VERSION ""

NS_ :

BS_:

BU_: ORC MPAD EVCU2 EPS CVADAS BSM2 BSM ADCAM

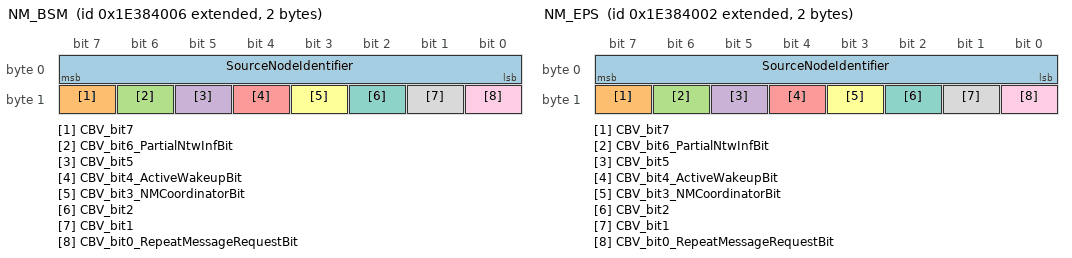
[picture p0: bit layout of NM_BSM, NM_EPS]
BO_ 2654486534 NM_BSM: 2 BSM
 SG_ SourceNodeIdentifier : 7|8@0+ (1,0) [0|255] "-"  CVADAS,ADCAM,MPAD,EVCU2,BSM2,ORC,EPS
 SG_ CBV_bit7 : 15|1@0+ (1,0) [0|1] "" CVADAS,ADCAM,MPAD,EVCU2,BSM2,ORC,EPS
 SG_ CBV_bit6_PartialNtwInfBit : 14|1@0+ (1,0) [0|1] "" CVADAS,ADCAM,MPAD,EVCU2,BSM2,ORC,EPS
 SG_ CBV_bit5 : 13|1@0+ (1,0) [0|1] "" CVADAS,ADCAM,MPAD,EVCU2,BSM2,ORC,EPS
 SG_ CBV_bit4_ActiveWakeupBit : 12|1@0+ (1,0) [0|1] "" CVADAS,ADCAM,MPAD,EVCU2,BSM2,ORC,EPS
 SG_ CBV_bit3_NMCoordinatorBit : 11|1@0+ (1,0) [0|1] "" CVADAS,ADCAM,MPAD,EVCU2,BSM2,ORC,EPS
 SG_ CBV_bit2 : 10|1@0+ (1,0) [0|1] "" CVADAS,ADCAM,MPAD,EVCU2,BSM2,ORC,EPS
 SG_ CBV_bit1 : 9|1@0+ (1,0) [0|1] "" CVADAS,ADCAM,MPAD,EVCU2,BSM2,ORC,EPS
 SG_ CBV_bit0_RepeatMessageRequestBit : 8|1@0+ (1,0) [0|1] "" CVADAS,ADCAM,MPAD,EVCU2,BSM2,ORC,EPS

BO_ 258 BRAKE_FD_2: 64 BSM
 SG_ YawRateFailSts_BSM : 87|1@0+ (1,0) [0|1] "-"  CVADAS,ADCAM,MPAD,EPS
 SG_ YawRate_BSM : 67|12@0+ (0.08,-163.84) [-163.84|163.68] "deg/s"  CVADAS,ADCAM,MPAD,EPS
 SG_ VehicleSpeedVSOSig : 4|13@0+ (0.0625,0) [0|511.875] "Km/h"  CVADAS,ADCAM,MPAD,EVCU2,BSM2,EPS
 SG_ Slope : 135|8@0+ (1,-100) [-100|154] "%"  CVADAS,MPAD
 SG_ PrefillActive : 86|1@0+ (1,0) [0|1] "-"  ADCAM,MPAD
 SG_ MessageCounter_BRAKE2 : 435|4@0+ (1,0) [0|15] "-"  CVADAS,ADCAM,MPAD,EVCU2,BSM2,EPS
 SG_ LongAccelerationFailSts_BSM : 69|1@0+ (1,0) [0|1] "-"  CVADAS,ADCAM,MPAD
 SG_ LongAcceleration_BSM : 35|12@0+ (0.02,-40.96) [-40.96|40.92] "m/s^2"  CVADAS,ADCAM,MPAD,EPS
 SG_ LatAccelerationFailSts_BSM : 68|1@0+ (1,0) [0|1] "-"  CVADAS,ADCAM,MPAD
 SG_ LatAcceleration_BSM : 19|12@0+ (0.02,-40.96) [-40.96|40.92] "m/s^2"  CVADAS,ADCAM,MPAD,EPS
 SG_ InternalError_BSM : 191|1@0+ (1,0) [0|1] "-"  ADCAM,MPAD
 SG_ ESP_Sys_Stat : 71|2@0+ (1,0) [0|3] "-"  Vector__XXX
 SG_ ESCActive : 84|1@0+ (1,0) [0|1] "-"  MPAD,EVCU2
 SG_ CRC_BRAKE2 : 447|8@0+ (1,0) [0|255] "-"  CVADAS,ADCAM,MPAD,EVCU2,BSM2,EPS
 SG_ BrakePedalPressure : 386|11@0+ (0.1,0) [0|200] "bar"  EVCU2
 SG_ BrakeInterventionSts : 103|1@0+ (1,0) [0|1] "-"  ADCAM,MPAD,BSM2
 SG_ BrakeBoostStat : 439|4@0+ (1,0) [0|14] "-"  Vector__XXX
 SG_ BrakeBoostPressure : 370|11@0+ (0.1,0) [0|200] "bar"  EVCU2
 SG_ ABSActive : 83|1@0+ (1,0) [0|1] "-"  MPAD,EVCU2
 SG_ WheelRPM_FR : 295|16@0+ (0.001953125,0) [0|127.9961] "Rev/s"  MPAD,EPS
 SG_ WheelRPM_FL : 279|16@0+ (0.001953125,0) [0|127.9961] "Rev/s"  MPAD,EPS
 SG_ Brk_Stat : 343|2@0+ (1,0) [0|2] "-"  CVADAS,ADCAM,MPAD,EVCU2
 SG_ ParkingGearShiftReq_BSM : 22|3@0+ (1,0) [0|6] "" CVADAS
 SG_ ParkingInterventionSts : 7|2@0+ (1,0) [0|3] "" CVADAS

BO_ 2654486530 NM_EPS: 2 EPS
 SG_ SourceNodeIdentifier : 7|8@0+ (1,0) [0|255] "-"  CVADAS,ADCAM,MPAD,EVCU2,BSM2,BSM,ORC
 SG_ CBV_bit7 : 15|1@0+ (1,0) [0|1] "" CVADAS,ADCAM,MPAD,EVCU2,BSM2,BSM,ORC
 SG_ CBV_bit6_PartialNtwInfBit : 14|1@0+ (1,0) [0|1] "" CVADAS,ADCAM,MPAD,EVCU2,BSM2,BSM,ORC
 SG_ CBV_bit5 : 13|1@0+ (1,0) [0|1] "" CVADAS,ADCAM,MPAD,EVCU2,BSM2,BSM,ORC
 SG_ CBV_bit4_ActiveWakeupBit : 12|1@0+ (1,0) [0|1] "" CVADAS,ADCAM,MPAD,EVCU2,BSM2,BSM,ORC
 SG_ CBV_bit3_NMCoordinatorBit : 11|1@0+ (1,0) [0|1] "" CVADAS,ADCAM,MPAD,EVCU2,BSM2,BSM,ORC
 SG_ CBV_bit2 : 10|1@0+ (1,0) [0|1] "" CVADAS,ADCAM,MPAD,EVCU2,BSM2,BSM,ORC
 SG_ CBV_bit1 : 9|1@0+ (1,0) [0|1] "" CVADAS,ADCAM,MPAD,EVCU2,BSM2,BSM,ORC
 SG_ CBV_bit0_RepeatMessageRequestBit : 8|1@0+ (1,0) [0|1] "" CVADAS,ADCAM,MPAD,EVCU2,BSM2,BSM,ORC

BO_ 524 BRAKE2_FD_2: 32 BSM2
 SG_ VehicleStandStillSts_B2 : 47|2@0+ (1,0) [0|2] "" MPAD,BSM
 SG_ BSM2_OpStat : 50|3@0+ (1,0) [0|5] "" MPAD,BSM
 SG_ Brake_OpStat_Sec : 53|3@0+ (1,0) [0|5] "" MPAD
 SG_ MessageCounter_BRAKE2_2 : 179|4@0+ (1,0) [0|15] "-"  MPAD,BSM,ORC
 SG_ CRC_BRAKE2_2 : 191|8@0+ (1,0) [0|255] "-"  MPAD,BSM,ORC
 SG_ BrkTrq_B2 : 6|15@0+ (3,0) [0|98301] "Nm"  MPAD
 SG_ BSM2_HEALTH_CHECK : 63|8@0+ (1,0) [0|255] "" BSM
 SG_ AEB_Type_Brk_B2 : 43|4@0+ (1,0) [0|15] "" MPAD

BO_ 257 BRAKE2_FD_1: 64 BSM2
 SG_ VehicleSpeedVSOSig_B2 : 36|13@0+ (0.0625,0) [0|511.875] "Km/h"  MPAD,EPS
 SG_ RHFWheelSpeed_B2 : 68|13@0+ (0.0625,0) [0|511.875] "Km/h"  MPAD
 SG_ RHF_FastPulseCounter_B2 : 95|8@0+ (1,0) [0|255] "pulse"  MPAD
 SG_ LHFWheelSpeed_B2 : 52|13@0+ (0.0625,0) [0|511.875] "Km/h"  MPAD
 SG_ LHF_FastPulseCounter_B2 : 87|8@0+ (1,0) [0|255] "pulse"  MPAD
 SG_ RHF_WheelSensorFailSts_B2 : 69|1@0+ (1,0) [0|1] "" MPAD
 SG_ RHF_Spin_B2 : 55|2@0+ (1,0) [0|3] "" MPAD
 SG_ MessageCounter_BRAKE2_1 : 435|4@0+ (1,0) [0|15] "-"  MPAD,ORC,EPS
 SG_ LHF_WheelSensorFailSts_B2 : 53|1@0+ (1,0) [0|1] "" MPAD
 SG_ LHF_Spin_B2 : 39|2@0+ (1,0) [0|3] "" MPAD
 SG_ Inlet_Pressure_Pos : 98|2@0+ (1,0) [0|2] "" MPAD
 SG_ CRC_BRAKE2_1 : 447|8@0+ (1,0) [0|255] "-"  MPAD,ORC,EPS
 SG_ Brk_Stat_B2 : 71|2@0+ (1,0) [0|2] "" MPAD
 SG_ ABSActive_B2 : 37|1@0+ (1,0) [0|1] "" MPAD
 SG_ Ft_RrTrqCoupling_ModeRq_B2 : 158|2@0+ (1,0) [0|3] "-"  Vector__XXX
 SG_ Ft_RrAxleCoupling_TrqRq_B2 : 143|8@0+ (12,0) [0|3060] "Nm"  Vector__XXX

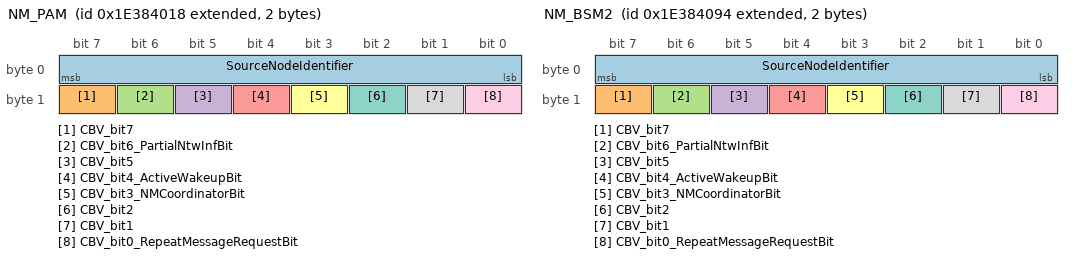
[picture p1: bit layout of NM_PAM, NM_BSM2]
BO_ 2654486552 NM_PAM: 2 CVADAS
 SG_ SourceNodeIdentifier : 7|8@0+ (1,0) [0|255] "-"  ADCAM,MPAD,EVCU2,BSM2,BSM,ORC,EPS
 SG_ CBV_bit7 : 15|1@0+ (1,0) [0|1] "" ADCAM,MPAD,EVCU2,BSM2,BSM,ORC,EPS
 SG_ CBV_bit6_PartialNtwInfBit : 14|1@0+ (1,0) [0|1] "" ADCAM,MPAD,EVCU2,BSM2,BSM,ORC,EPS
 SG_ CBV_bit5 : 13|1@0+ (1,0) [0|1] "" ADCAM,MPAD,EVCU2,BSM2,BSM,ORC,EPS
 SG_ CBV_bit4_ActiveWakeupBit : 12|1@0+ (1,0) [0|1] "" ADCAM,MPAD,EVCU2,BSM2,BSM,ORC,EPS
 SG_ CBV_bit3_NMCoordinatorBit : 11|1@0+ (1,0) [0|1] "" ADCAM,MPAD,EVCU2,BSM2,BSM,ORC,EPS
 SG_ CBV_bit2 : 10|1@0+ (1,0) [0|1] "" ADCAM,MPAD,EVCU2,BSM2,BSM,ORC,EPS
 SG_ CBV_bit1 : 9|1@0+ (1,0) [0|1] "" ADCAM,MPAD,EVCU2,BSM2,BSM,ORC,EPS
 SG_ CBV_bit0_RepeatMessageRequestBit : 8|1@0+ (1,0) [0|1] "" ADCAM,MPAD,EVCU2,BSM2,BSM,ORC,EPS

BO_ 2654486676 NM_BSM2: 2 BSM2
 SG_ SourceNodeIdentifier : 7|8@0+ (1,0) [0|255] "-"  CVADAS,ADCAM,MPAD,EVCU2,BSM,ORC,EPS
 SG_ CBV_bit7 : 15|1@0+ (1,0) [0|1] "" CVADAS,ADCAM,MPAD,EVCU2,BSM,ORC,EPS
 SG_ CBV_bit6_PartialNtwInfBit : 14|1@0+ (1,0) [0|1] "" CVADAS,ADCAM,MPAD,EVCU2,BSM,ORC,EPS
 SG_ CBV_bit5 : 13|1@0+ (1,0) [0|1] "" CVADAS,ADCAM,MPAD,EVCU2,BSM,ORC,EPS
 SG_ CBV_bit4_ActiveWakeupBit : 12|1@0+ (1,0) [0|1] "" CVADAS,ADCAM,MPAD,EVCU2,BSM,ORC,EPS
 SG_ CBV_bit3_NMCoordinatorBit : 11|1@0+ (1,0) [0|1] "" CVADAS,ADCAM,MPAD,EVCU2,BSM,ORC,EPS
 SG_ CBV_bit2 : 10|1@0+ (1,0) [0|1] "" CVADAS,ADCAM,MPAD,EVCU2,BSM,ORC,EPS
 SG_ CBV_bit1 : 9|1@0+ (1,0) [0|1] "" CVADAS,ADCAM,MPAD,EVCU2,BSM,ORC,EPS
 SG_ CBV_bit0_RepeatMessageRequestBit : 8|1@0+ (1,0) [0|1] "" CVADAS,ADCAM,MPAD,EVCU2,BSM,ORC,EPS

BO_ 727 CVPAM_FD_Data2: 64 CVADAS
 SG_ MessageCounter_CVPAM_FD_Data2 : 435|4@0+ (1,0) [0|15] "-"  MPAD
 SG_ CRC_CVPAM_FD_Data2 : 447|8@0+ (1,0) [0|255] "-"  MPAD

BO_ 726 CVPAM_FD_Data: 64 CVADAS
 SG_ MessageCounter_CVPAM_FD_Data : 435|4@0+ (1,0) [0|15] "-"  MPAD
 SG_ CRC_CVPAM_FD_Data : 447|8@0+ (1,0) [0|255] "-"  MPAD

BO_ 1156 BRAKE2_FD_3: 32 BSM2
 SG_ RollsModeAct_B2 : 6|1@0+ (1,0) [0|1] "" MPAD
 SG_ MessageCounter_BRAKE2_3 : 179|4@0+ (1,0) [0|15] "-"  ORC
 SG_ CRC_BRAKE2_3 : 191|8@0+ (1,0) [0|255] "-"  ORC
 SG_ ABSFailSts_B2 : 7|1@0+ (1,0) [0|1] "" MPAD

BO_ 280 ADAS_FD_INFO: 32 ADCAM
 SG_ Object_Dist : 127|8@0+ (1,0) [0|255] "m"  EVCU2,BSM,ORC
 SG_ MessageCounter_ADAS_FD_INFO : 179|4@0+ (1,0) [0|15] "-"  CVADAS,EVCU2,BSM2,BSM,ORC,EPS
 SG_ CRC_ADAS_FD_INFO : 191|8@0+ (1,0) [0|255] "-"  CVADAS,EVCU2,BSM2,BSM,ORC,EPS
 SG_ ACC_DsrSpeedKPH : 119|8@0+ (1,0) [0|255] "km/h"  EVCU2
 SG_ Intervention : 163|12@0+ (0.01,-16) [-16|24.95] "m/s2"  BSM2,BSM,ORC
 SG_ HIS_Req : 89|1@0+ (1,0) [0|1] "-"  BSM2,BSM,ORC
 SG_ GrMax_Rq_ACC : 150|4@0+ (1,0) [0|15] "-"  BSM
 SG_ CIPV_Fused : 101|1@0+ (1,0) [0|1] "-"  ORC
 SG_ Brake_Jerk_Req : 100|1@0+ (1,0) [0|1] "-"  BSM
 SG_ ACC_Engine_Torque_Enabled : 111|1@0+ (1,0) [0|1] "-"  BSM
 SG_ ACC_Drive_Cmd : 151|1@0+ (1,0) [0|1] "-"  BSM
 SG_ Prefill_Req : 91|1@0+ (1,0) [0|1] "-"  BSM
 SG_ PEB_SystemSts : 90|1@0+ (1,0) [0|1] "-"  ORC
 SG_ MRM_STATUS : 23|3@0+ (1,0) [0|6] "" CVADAS,EVCU2,BSM,ORC
 SG_ LANE_CHANGE_SIDE : 95|2@0+ (1,0) [0|2] "" ORC
 SG_ HAS_Status : 106|2@0+ (1,0) [0|3] "" CVADAS,BSM2,BSM
 SG_ HAS_OpStat_Prim : 4|3@0+ (1,0) [0|5] "" ORC
 SG_ HAS_LAT_CTRL_RequestSts : 110|2@0+ (1,0) [0|3] "-"  EPS
 SG_ ESCALATION_TYPE : 12|3@0+ (1,0) [0|4] "" ORC
 SG_ DDD_SystemSts : 103|1@0+ (1,0) [0|1] "-"  ORC
 SG_ DDD_Setting_Avail : 102|1@0+ (1,0) [0|1] "-"  Vector__XXX
 SG_ CADM_OpStat : 7|3@0+ (1,0) [0|5] "" CVADAS
 SG_ AEB_Type : 167|4@0+ (1,0) [0|14] "-"  BSM2,BSM,ORC
 SG_ AEB_Systemsts : 99|2@0+ (1,0) [0|2] "-"  ORC
 SG_ AEB_Sensitivity_Setting : 1|2@0+ (1,0) [0|2] "" Vector__XXX
 SG_ ACC_Systemsts : 183|4@0+ (1,0) [0|14] "-"  CVADAS,ADCAM,EVCU2,BSM2,BSM,ORC
 SG_ SteeringVibration_Type : 67|4@0+ (1,0) [0|14] "-"  EPS
 SG_ SteeringVibration_Rq : 135|1@0+ (1,0) [0|1] "-"  EPS
 SG_ LKA_LAT_CTRL_RequestSts : 108|2@0+ (1,0) [0|3] "-"  EPS
 SG_ LANE_CHANGE_STATUS : 71|4@0+ (1,0) [0|14] "" ADCAM,ORC
 SG_ LC_Jerk : 104|1@0+ (1,0) [0|1] "-"  BSM
 SG_ CADM2_EPSSEC_FAIL : 8|1@0+ (1,0) [0|1] "" EPS
 SG_ TorqueOverlaySteeringReq : 130|11@0+ (0.0048828125,-5) [-5|4.995117188] "-"  ORC,EPS

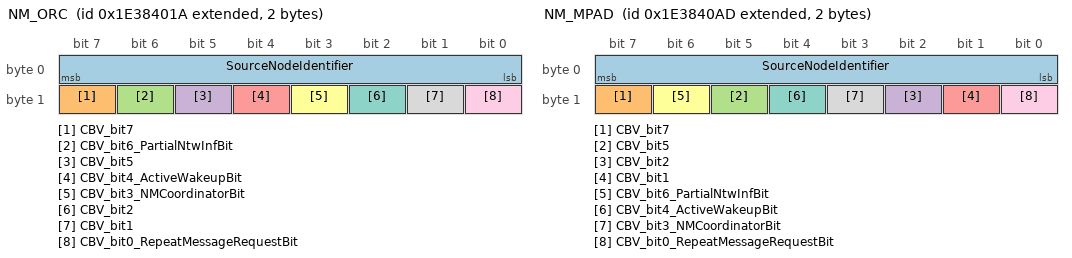
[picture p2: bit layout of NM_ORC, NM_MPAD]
BO_ 2654486554 NM_ORC: 2 ORC
 SG_ SourceNodeIdentifier : 7|8@0+ (1,0) [0|255] "-"  CVADAS,ADCAM,MPAD,EVCU2,BSM2,BSM,EPS
 SG_ CBV_bit7 : 15|1@0+ (1,0) [0|1] "" CVADAS,ADCAM,MPAD,EVCU2,BSM2,BSM,EPS
 SG_ CBV_bit6_PartialNtwInfBit : 14|1@0+ (1,0) [0|1] "" CVADAS,ADCAM,MPAD,EVCU2,BSM2,BSM,EPS
 SG_ CBV_bit5 : 13|1@0+ (1,0) [0|1] "" CVADAS,ADCAM,MPAD,EVCU2,BSM2,BSM,EPS
 SG_ CBV_bit4_ActiveWakeupBit : 12|1@0+ (1,0) [0|1] "" CVADAS,ADCAM,MPAD,EVCU2,BSM2,BSM,EPS
 SG_ CBV_bit3_NMCoordinatorBit : 11|1@0+ (1,0) [0|1] "" CVADAS,ADCAM,MPAD,EVCU2,BSM2,BSM,EPS
 SG_ CBV_bit2 : 10|1@0+ (1,0) [0|1] "" CVADAS,ADCAM,MPAD,EVCU2,BSM2,BSM,EPS
 SG_ CBV_bit1 : 9|1@0+ (1,0) [0|1] "" CVADAS,ADCAM,MPAD,EVCU2,BSM2,BSM,EPS
 SG_ CBV_bit0_RepeatMessageRequestBit : 8|1@0+ (1,0) [0|1] "" CVADAS,ADCAM,MPAD,EVCU2,BSM2,BSM,EPS

BO_ 205 BRAKE_FD_6: 64 BSM
 SG_ CRC_BRAKE_FD_6 : 447|8@0+ (1,0) [0|255] "-"  EVCU2
 SG_ MessageCounter_BRAKE_FD_6 : 435|4@0+ (1,0) [0|15] "-"  EVCU2
 SG_ RearAxle_Min_Rq_BSM : 52|1@0+ (1,0) [0|1] "" EVCU2
 SG_ RearAxle_Max_Rq_BSM : 53|1@0+ (1,0) [0|1] "" EVCU2
 SG_ FrontAxle_Min_Rq_BSM : 54|1@0+ (1,0) [0|1] "" EVCU2
 SG_ FrontAxle_Max_Rq_BSM : 55|1@0+ (1,0) [0|1] "" EVCU2
 SG_ TotalAxle_Min_Rq_BSM : 50|1@0+ (1,0) [0|1] "" EVCU2
 SG_ TotalAxle_Max_Rq_BSM : 51|1@0+ (1,0) [0|1] "" EVCU2
 SG_ DrvrIntd_TotalBrk_AxleTorq : 142|15@0+ (2,0) [0|65532] "Nm"  EVCU2
 SG_ DriverReq_AxleTrq_Enabled_BSM : 175|4@0+ (1,0) [0|15] "" CVADAS,EVCU2
 SG_ Cmnd_TotBrkFrict_AxleTorq : 126|15@0+ (2,0) [0|65532] "Nm"  EVCU2
 SG_ TotalAxle_Rq_BSM : 95|16@0+ (2,-65534) [-65534|65536] "Nm"  EVCU2
 SG_ DriverRequested_AxleTrq_BSM : 159|16@0+ (2,-65534) [-65534|65536] "Nm"  EVCU2
 SG_ RearAxle_Rq_BSM : 79|16@0+ (2,-65534) [-65534|65536] "Nm"  EVCU2
 SG_ FrontAxle_Rq_BSM : 63|16@0+ (2,-65534) [-65534|65536] "Nm"  EVCU2

BO_ 204 AXLE_TORQUE_FD_1: 48 EVCU2
 SG_ MessageCounter_AXLE_TORQUE_FD_1 : 307|4@0+ (1,0) [0|15] "-"  ADCAM,MPAD
 SG_ CRC_AXLE_TORQUE_FD_1 : 319|8@0+ (1,0) [0|255] "-"  ADCAM,MPAD
 SG_ Rear_Axle_Regen_Capacity : 197|14@0+ (2,0) [0|32764] "Nm"  BSM
 SG_ Rear_Axle_Est_Regen_Torq : 181|14@0+ (2,0) [0|32764] "Nm"  BSM
 SG_ Front_Axle_Regen_Capacity : 165|14@0+ (2,0) [0|32764] "Nm"  BSM
 SG_ Front_Axle_Est_Regen_Torq : 149|14@0+ (2,0) [0|32764] "Nm"  BSM
 SG_ Total_AxleTorque_Min : 23|16@0+ (2,-65534) [-65534|65536] "Nm"  ADCAM,MPAD,BSM
 SG_ Total_AxleTorque_Max : 7|16@0+ (2,-65534) [-65534|65536] "Nm"  ADCAM,MPAD
 SG_ Axle_TorqueStatic_D_TTC : 39|16@0+ (2,-65534) [-65534|65536] "Nm"  ADCAM,MPAD,BSM
 SG_ Axle_Torque_DrvReqMod : 55|16@0+ (2,-65534) [-65534|65536] "Nm"  ADCAM,MPAD,BSM
 SG_ Rear_AxleTorque_Min : 119|16@0+ (2,-65534) [-65534|65536] "Nm"  BSM
 SG_ Rear_AxleTorque_Max : 103|16@0+ (2,-65534) [-65534|65536] "Nm"  BSM
 SG_ Front_AxleTorque_Min : 87|16@0+ (2,-65534) [-65534|65536] "Nm"  BSM
 SG_ Front_AxleTorque_Max : 71|16@0+ (2,-65534) [-65534|65536] "Nm"  BSM

BO_ 292 BATTERY_HV_STATUS1: 64 EVCU2
 SG_ BPCM_HV_Trac_Main_Contac_Sts : 181|3@0+ (1,0) [0|7] "" Vector__XXX
 SG_ BPCM_HV_Trac_Bus_Sts : 36|3@0+ (1,0) [0|7] "" ORC
 SG_ BPCM_HV_SOC : 33|10@0+ (0.1,0) [0|102.3] "%"  BSM
 SG_ BPCM_HV_InternalVoltage : 133|14@0+ (0.1,90.9) [90.9|1729.2] "V"  ORC
 SG_ MessageCounter_BATT_HV_STATUS1 : 435|4@0+ (1,0) [0|15] "" ORC,BSM
 SG_ CRC_BATT_HV_STATUS1 : 447|8@0+ (1,0) [0|255] "" ORC,BSM

BO_ 2654486701 NM_MPAD: 2 MPAD
 SG_ SourceNodeIdentifier : 7|8@0+ (1,0) [0|255] "-"  CVADAS,ADCAM,EVCU2,BSM2,BSM,ORC,EPS
 SG_ CBV_bit7 : 15|1@0+ (1,0) [0|1] "" CVADAS,ADCAM,EVCU2,BSM2,BSM,ORC,EPS
 SG_ CBV_bit5 : 13|1@0+ (1,0) [0|1] "" CVADAS,ADCAM,EVCU2,BSM2,BSM,ORC,EPS
 SG_ CBV_bit2 : 10|1@0+ (1,0) [0|1] "" CVADAS,ADCAM,EVCU2,BSM2,BSM,ORC,EPS
 SG_ CBV_bit1 : 9|1@0+ (1,0) [0|1] "" CVADAS,ADCAM,EVCU2,BSM2,BSM,ORC,EPS
 SG_ CBV_bit6_PartialNtwInfBit : 14|1@0+ (1,0) [0|1] "-"  CVADAS,ADCAM,EVCU2,BSM2,BSM,ORC,EPS
 SG_ CBV_bit4_ActiveWakeupBit : 12|1@0+ (1,0) [0|1] "-"  CVADAS,ADCAM,EVCU2,BSM2,BSM,ORC,EPS
 SG_ CBV_bit3_NMCoordinatorBit : 11|1@0+ (1,0) [0|1] "-"  CVADAS,ADCAM,EVCU2,BSM2,BSM,ORC,EPS
 SG_ CBV_bit0_RepeatMessageRequestBit : 8|1@0+ (1,0) [0|1] "-"  CVADAS,ADCAM,EVCU2,BSM2,BSM,ORC,EPS

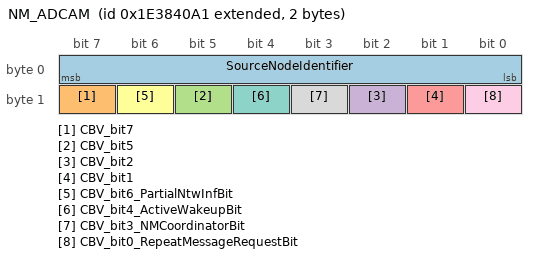
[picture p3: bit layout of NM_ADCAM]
BO_ 2654486689 NM_ADCAM: 2 ADCAM
 SG_ SourceNodeIdentifier : 7|8@0+ (1,0) [0|255] "-"  CVADAS,MPAD,EVCU2,BSM2,BSM,ORC,EPS
 SG_ CBV_bit7 : 15|1@0+ (1,0) [0|1] "" CVADAS,MPAD,EVCU2,BSM2,BSM,ORC,EPS
 SG_ CBV_bit5 : 13|1@0+ (1,0) [0|1] "" CVADAS,MPAD,EVCU2,BSM2,BSM,ORC,EPS
 SG_ CBV_bit2 : 10|1@0+ (1,0) [0|1] "" CVADAS,MPAD,EVCU2,BSM2,BSM,ORC,EPS
 SG_ CBV_bit1 : 9|1@0+ (1,0) [0|1] "" CVADAS,MPAD,EVCU2,BSM2,BSM,ORC,EPS
 SG_ CBV_bit6_PartialNtwInfBit : 14|1@0+ (1,0) [0|1] "-"  CVADAS,MPAD,EVCU2,BSM2,BSM,ORC,EPS
 SG_ CBV_bit4_ActiveWakeupBit : 12|1@0+ (1,0) [0|1] "-"  CVADAS,MPAD,EVCU2,BSM2,BSM,ORC,EPS
 SG_ CBV_bit3_NMCoordinatorBit : 11|1@0+ (1,0) [0|1] "-"  CVADAS,MPAD,EVCU2,BSM2,BSM,ORC,EPS
 SG_ CBV_bit0_RepeatMessageRequestBit : 8|1@0+ (1,0) [0|1] "-"  CVADAS,MPAD,EVCU2,BSM2,BSM,ORC,EPS

BO_ 299 ADAS_FD_INFO3: 32 ADCAM
 SG_ ACC_Axle_Torque : 7|16@0+ (2,-65534) [-65534|65536] "Nm"  BSM
 SG_ ACC_Axle_Torque_Enabled : 180|1@0+ (1,0) [0|1] "" BSM
 SG_ MessageCounter_ADAS_FD_INFO3 : 179|4@0+ (1,0) [0|15] "-"  MPAD,BSM
 SG_ CRC_ADAS_FD_INFO3 : 191|8@0+ (1,0) [0|255] "-"  MPAD,BSM
 SG_ ACC_TORSts : 22|1@0+ (1,0) [0|1] "" ADCAM

BO_TX_BU_ 280 : ADCAM,MPAD;
BO_TX_BU_ 299 : ADCAM,MPAD;
CM_ SG_ 2654486534 CBV_bit6_PartialNtwInfBit "Partial Network Information Bit (PNI)";
CM_ SG_ 2654486534 CBV_bit4_ActiveWakeupBit "Active Wakeup Bit";
CM_ SG_ 2654486534 CBV_bit3_NMCoordinatorBit "NM Coordinator Sleep Bit";
CM_ SG_ 2654486534 CBV_bit0_RepeatMessageRequestBit "Repeat Message Request Bit";
CM_ SG_ 2654486534 SourceNodeIdentifier "Source Node Identifier";
CM_ SG_ 258 YawRateFailSts_BSM "This signal indicates the Status of Yaw Rate Signal";
CM_ SG_ 258 YawRate_BSM "This signal indicates the Yaw Rate Value";
CM_ SG_ 258 WheelRPM_FL "Wheel RPM front left";
CM_ SG_ 258 Slope "Slope value detected by BSM";
CM_ SG_ 258 PrefillActive "This signal indicates the prefill function status.";
CM_ SG_ 258 ParkingInterventionSts "Current status of BSM during Autonomous Parking Maneuver";
CM_ SG_ 258 ParkingGearShiftReq_BSM "CVPAM Request to autonomously shift gears";
CM_ SG_ 258 VehicleSpeedVSOSig "It is the average vehicle speed calculated.";
CM_ SG_ 258 MessageCounter_BRAKE2 "This signal is a counter used for safety checks strategies. This counter is incremented of 1 (one) unit at each frame transmission.";
CM_ SG_ 258 LongAccelerationFailSts_BSM "This signal indicates the status of Longitudinal acceleration signal";
CM_ SG_ 258 LongAcceleration_BSM "This signal indicates the Longitudinal Acceleration Value";
CM_ SG_ 258 LatAccelerationFailSts_BSM "This signal indicates the status of Lateral Acceleration Signal";
CM_ SG_ 258 LatAcceleration_BSM "This signal indicates the Lateral Acceleration Value";
CM_ SG_ 258 InternalError_BSM "This signal indicates if an internal error has been processed";
CM_ SG_ 258 ESP_Sys_Stat "0";
CM_ SG_ 258 ESCActive "This signal is set to Active when the brake intervention by ESC is active.";
CM_ SG_ 258 Brk_Stat "Brake state";
CM_ SG_ 258 BrakePedalPressure "Pressure Information from Brake Pedal Simulator Pressure Sensor";
CM_ SG_ 258 BrakeInterventionSts "This signal is ?active? when the brake intervention is due to BSM events and ?not active? when the brake intervention is due to the driver";
CM_ SG_ 258 BrakeBoostStat "eBoost System Status INIT, eBOOST, PUSH-THROUGH, SNA";
CM_ SG_ 258 BrakeBoostPressure "Pressure Information from Brake Booster Pressure Sensor";
CM_ SG_ 258 ABSActive "This signal is set to Active when the ABS functionality is active.";
CM_ SG_ 258 CRC_BRAKE2 "CRC according to SAE J1850 standard at each frame transmission.";
CM_ SG_ 258 WheelRPM_FR "Wheel RPM front right";
CM_ SG_ 2654486530 SourceNodeIdentifier "Source Node Identifier";
CM_ SG_ 2654486530 CBV_bit6_PartialNtwInfBit "Partial Network Information Bit (PNI)";
CM_ SG_ 2654486530 CBV_bit4_ActiveWakeupBit "Active Wakeup Bit";
CM_ SG_ 2654486530 CBV_bit3_NMCoordinatorBit "NM Coordinator Sleep Bit";
CM_ SG_ 2654486530 CBV_bit0_RepeatMessageRequestBit "Repeat Message Request Bit";
CM_ SG_ 524 VehicleStandStillSts_B2 "VehicleStandStillSts_B2";
CM_ SG_ 524 MessageCounter_BRAKE2_2 "This signal is a counter used for safety checks strategies. This counter is incremented of 1 (one) unit at each frame transmission.";
CM_ SG_ 524 CRC_BRAKE2_2 "CRC according to SAE J1850 standard at each frame transmission.";
CM_ SG_ 524 BSM2_OpStat "Capability of the secondary brake control module to provide deceleration and/or stability control";
CM_ SG_ 524 BSM2_HEALTH_CHECK "BSM2_HEALTH_CHECK";
CM_ SG_ 524 BrkTrq_B2 "BrkTrq_B2";
CM_ SG_ 524 Brake_OpStat_Sec "Capability of the Braking system to perform deceleration and/or stability control as reported by the secondary actuator.";
CM_ SG_ 524 AEB_Type_Brk_B2 "AEB_Type_Brk_B2";
CM_ SG_ 257 VehicleSpeedVSOSig_B2 "VehicleSpeedVSOSig_B2";
CM_ SG_ 257 RHFWheelSpeed_B2 "RHFWheelSpeed_B2";
CM_ SG_ 257 RHF_WheelSensorFailSts_B2 "RHF_WheelSensorFailSts_B2";
CM_ SG_ 257 RHF_Spin_B2 "RHF_Spin_B2";
CM_ SG_ 257 RHF_FastPulseCounter_B2 "RHF_FastPulseCounter_B2";
CM_ SG_ 257 MessageCounter_BRAKE2_1 "This signal is a counter used for safety checks strategies. This counter is incremented of 1 (one) unit at each frame transmission.";
CM_ SG_ 257 LHFWheelSpeed_B2 "LHFWheelSpeed_B2";
CM_ SG_ 257 LHF_WheelSensorFailSts_B2 "LHF_WheelSensorFailSts_B2";
CM_ SG_ 257 LHF_Spin_B2 "LHF_Spin_B2";
CM_ SG_ 257 LHF_FastPulseCounter_B2 "LHF_FastPulseCounter_B2";
CM_ SG_ 257 Inlet_Pressure_Pos "Inlet Pressure Pos Indicates if the secondary brake control module detects upstream brake pressure";
CM_ SG_ 257 Ft_RrTrqCoupling_ModeRq_B2 "ESP Requested Center Differential State";
CM_ SG_ 257 Ft_RrAxleCoupling_TrqRq_B2 "Desired Torque for Center Diff";
CM_ SG_ 257 CRC_BRAKE2_1 "CRC according to SAE J1850 standard at each frame transmission.";
CM_ SG_ 257 Brk_Stat_B2 "Signifies a general braking event (both autonomous and driver requested) with the secondary brake control module";
CM_ SG_ 257 ABSActive_B2 "ABSActive_B2";
CM_ SG_ 2654486552 SourceNodeIdentifier "Source Node Identifier";
CM_ SG_ 2654486552 CBV_bit6_PartialNtwInfBit "Partial Network Information Bit (PNI)";
CM_ SG_ 2654486552 CBV_bit4_ActiveWakeupBit "Active Wakeup Bit";
CM_ SG_ 2654486552 CBV_bit3_NMCoordinatorBit "NM Coordinator Sleep Bit";
CM_ SG_ 2654486552 CBV_bit0_RepeatMessageRequestBit "Repeat Message Request Bit";
CM_ SG_ 2654486676 CBV_bit0_RepeatMessageRequestBit "Repeat Message Request Bit";
CM_ SG_ 2654486676 CBV_bit3_NMCoordinatorBit "NM Coordinator Sleep Bit";
CM_ SG_ 2654486676 CBV_bit4_ActiveWakeupBit "Active Wakeup Bit";
CM_ SG_ 2654486676 CBV_bit6_PartialNtwInfBit "Partial Network Information Bit (PNI)";
CM_ SG_ 2654486676 SourceNodeIdentifier "Source Node Identifier";
CM_ SG_ 727 MessageCounter_CVPAM_FD_Data2 "This signal is a counter used for safety checks strategies. This counter is incremented of 1 (one) unit at each frame transmission.";
CM_ SG_ 727 CRC_CVPAM_FD_Data2 "CRC according to SAE J1850 standard at each frame transmission.";
CM_ SG_ 726 MessageCounter_CVPAM_FD_Data "This signal is a counter used for safety checks strategies. This counter is incremented of 1 (one) unit at each frame transmission.";
CM_ SG_ 726 CRC_CVPAM_FD_Data "CRC according to SAE J1850 standard at each frame transmission.";
CM_ SG_ 1156 RollsModeAct_B2 "RollsModeAct_B2";
CM_ SG_ 1156 MessageCounter_BRAKE2_3 "This signal is a counter used for safety checks strategies. This counter is incremented of 1 (one) unit at each frame transmission.";
CM_ SG_ 1156 CRC_BRAKE2_3 "CRC according to SAE J1850 standard at each frame transmission.";
CM_ SG_ 1156 ABSFailSts_B2 "ABSFailSts_B2";
CM_ SG_ 280 TorqueOverlaySteeringReq "TorqueOverlaySteeringReq";
CM_ SG_ 280 SteeringVibration_Type "Type of Steering Wheel Vibration Request";
CM_ SG_ 280 SteeringVibration_Rq "Request to activate Steering Wheel Vibration";
CM_ SG_ 280 Prefill_Req "Prefill command of Brake System by DASM";
CM_ SG_ 280 PEB_SystemSts "PEB System Status";
CM_ SG_ 280 Object_Dist "It indicates the distance to the recognized object";
CM_ SG_ 280 MRM_STATUS "Status of the minimum risk maneuver to handle system faults or driver abuse as understood by primary controller";
CM_ SG_ 280 LKA_LAT_CTRL_RequestSts "LKA_LAT_CTRL_RequestSts";
CM_ SG_ 280 LC_Jerk "Lane Centering request for brake jerk";
CM_ SG_ 280 LANE_CHANGE_STATUS "Status of assisted lane change maneuver";
CM_ SG_ 280 LANE_CHANGE_SIDE "Direction of the currently in-progress lane change from a vehicle perspective";
CM_ SG_ 280 Intervention "Request to set target acceleration/deceleration for any feature";
CM_ SG_ 280 HIS_Req "Used to command Stop during Stop and Go ACC and FSFCW+";
CM_ SG_ 280 HAS_Status "Highway Assist System Status as reported by the main controller";
CM_ SG_ 280 HAS_OpStat_Prim "Capability of the primary controller to perform sensing, computing, and actuation";
CM_ SG_ 280 HAS_LAT_CTRL_RequestSts "HAS_LAT_CTRL_RequestSts";
CM_ SG_ 280 GrMax_Rq_ACC "Used to request Max Gear from TCM";
CM_ SG_ 280 ESCALATION_TYPE "Type of HMI escalation to be provided to driver from primary controller";
CM_ SG_ 280 DDD_SystemSts "DDD System Status";
CM_ SG_ 280 DDD_Setting_Avail "DDD_Setting Av Status";
CM_ SG_ 280 MessageCounter_ADAS_FD_INFO "This signal is a counter used for safety checks strategies. This counter is incremented of 1 (one) unit at each frame transmission.";
CM_ SG_ 280 CRC_ADAS_FD_INFO "CRC according to SAE J1850 standard at each frame transmission.";
CM_ SG_ 280 CIPV_Fused "Closest in-path vehicle is fused True = 1";
CM_ SG_ 280 CADM2_EPSSEC_FAIL "CADM2 detection of failure to communicate to EPS";
CM_ SG_ 280 CADM_OpStat "Capability of primary controller to sense and compute a valid trajectory path based on external data dependencies and internal failures";
CM_ SG_ 280 Brake_Jerk_Req "Request from DASM to perform Jerk Warning";
CM_ SG_ 280 AEB_Type "AEB Type";
CM_ SG_ 280 AEB_Systemsts "AEB System Status";
CM_ SG_ 280 AEB_Sensitivity_Setting "AEB sensitivity status";
CM_ SG_ 280 ACC_Engine_Torque_Enabled "An enable bit that Torque commands should be followed";
CM_ SG_ 280 ACC_DsrSpeedKPH "Desired speed in kilometers per hour";
CM_ SG_ 280 ACC_Drive_Cmd "ACC Drive Command";
CM_ SG_ 280 ACC_Systemsts "ACC System Status";
CM_ SG_ 2654486554 SourceNodeIdentifier "Source Node Identifier";
CM_ SG_ 2654486554 CBV_bit6_PartialNtwInfBit "Partial Network Information Bit (PNI)";
CM_ SG_ 2654486554 CBV_bit4_ActiveWakeupBit "Active Wakeup Bit";
CM_ SG_ 2654486554 CBV_bit3_NMCoordinatorBit "NM Coordinator Sleep Bit";
CM_ SG_ 2654486554 CBV_bit0_RepeatMessageRequestBit "Repeat Message Request Bit";
CM_ SG_ 205 TotalAxle_Rq_BSM "Combined axle traction torque request";
CM_ SG_ 205 TotalAxle_Min_Rq_BSM "Combined axle traction torque min limit flag. Active = [1]";
CM_ SG_ 205 TotalAxle_Max_Rq_BSM "Combined axle traction torque max limit flag. Active = [1]";
CM_ SG_ 205 RearAxle_Rq_BSM "Rear axle traction control torque request";
CM_ SG_ 205 RearAxle_Min_Rq_BSM "Rear axle traction torque min limit  flag. Active = [1]";
CM_ SG_ 205 RearAxle_Max_Rq_BSM "Rear axle traction torque max limit  flag. Active = [1]";
CM_ SG_ 205 MessageCounter_BRAKE_FD_6 "This signal is a counter used for safety checks strategies. This counter is incremented of 1 (one) unit at each frame transmission.";
CM_ SG_ 205 FrontAxle_Rq_BSM "Front axle traction control torque request";
CM_ SG_ 205 FrontAxle_Min_Rq_BSM "Front axle traction torque min limit flag. Active = [1]";
CM_ SG_ 205 FrontAxle_Max_Rq_BSM "Front axle traction torque max limit flag. Active = [1]";
CM_ SG_ 205 DrvrIntd_TotalBrk_AxleTorq "Total Brake Torque in Axle domain";
CM_ SG_ 205 DriverRequested_AxleTrq_BSM "Virtual driver torque request from BSM";
CM_ SG_ 205 DriverReq_AxleTrq_Enabled_BSM "It indicates the request to enable virtual driver torque interface for BSM driver functions";
CM_ SG_ 205 CRC_BRAKE_FD_6 "CRC according to SAE J1850 standard at each frame transmission.";
CM_ SG_ 205 Cmnd_TotBrkFrict_AxleTorq "Commanded Total Brake Friction torque in Axle domain";
CM_ SG_ 204 Axle_Torque_DrvReqMod "Driver requested Axle torque raw (no torque shaping)";
CM_ SG_ 204 Axle_TorqueStatic_D_TTC "Driver requested Axle torque (filtered/ torque shaped)";
CM_ SG_ 204 CRC_AXLE_TORQUE_FD_1 "CRC according to SAE J1850 standard at each frame transmission.";
CM_ SG_ 204 Front_Axle_Est_Regen_Torq "Estimated regen Braking Torque at the Front axle";
CM_ SG_ 204 Front_Axle_Regen_Capacity "Regenerative Braking front Axle Torque Capability";
CM_ SG_ 204 Front_AxleTorque_Max "Maximum front Axle torque";
CM_ SG_ 204 Front_AxleTorque_Min "Minimum front Axle torque";
CM_ SG_ 204 MessageCounter_AXLE_TORQUE_FD_1 "This signal is a counter used for safety checks strategies. This counter is incremented of 1 (one) unit at each frame transmission.";
CM_ SG_ 204 Rear_Axle_Est_Regen_Torq "Estimated regen Braking Torque at the Rear axle";
CM_ SG_ 204 Rear_Axle_Regen_Capacity "Regenerative Braking rear Axle Torque Capability";
CM_ SG_ 204 Rear_AxleTorque_Max "Maximum rear Axle torque";
CM_ SG_ 204 Rear_AxleTorque_Min "Minimum rear Axle torque";
CM_ SG_ 204 Total_AxleTorque_Max "Maximum total Axle torque";
CM_ SG_ 204 Total_AxleTorque_Min "Minimum total Axle torque";
CM_ SG_ 292 CRC_BATT_HV_STATUS1 "CRC according to SAE J1850 standard at each frame transmission.";
CM_ SG_ 292 MessageCounter_BATT_HV_STATUS1 "This signal is a counter used for safety checks strategies. This counter is incremented of 1 (one) unit at each frame transmission.";
CM_ SG_ 292 BPCM_HV_InternalVoltage "Battery internal voltage.";
CM_ SG_ 292 BPCM_HV_SOC "State of Charge";
CM_ SG_ 292 BPCM_HV_Trac_Main_Contac_Sts "Traction main contactor physical relay status";
CM_ SG_ 2654486701 SourceNodeIdentifier "Source Node Identifier";
CM_ SG_ 2654486701 CBV_bit6_PartialNtwInfBit "Partial Network Information Bit (PNI)";
CM_ SG_ 2654486701 CBV_bit4_ActiveWakeupBit "Active Wakeup Bit";
CM_ SG_ 2654486701 CBV_bit3_NMCoordinatorBit "NM Coordinator Sleep Bit";
CM_ SG_ 2654486701 CBV_bit0_RepeatMessageRequestBit "Repeat Message Request Bit";
CM_ SG_ 2654486689 SourceNodeIdentifier "Source Node Identifier";
CM_ SG_ 2654486689 CBV_bit6_PartialNtwInfBit "Partial Network Information Bit (PNI)";
CM_ SG_ 2654486689 CBV_bit4_ActiveWakeupBit "Active Wakeup Bit";
CM_ SG_ 2654486689 CBV_bit3_NMCoordinatorBit "NM Coordinator Sleep Bit";
CM_ SG_ 2654486689 CBV_bit0_RepeatMessageRequestBit "Repeat Message Request Bit";
CM_ SG_ 299 MessageCounter_ADAS_FD_INFO3 "This signal is a counter used for safety checks strategies. This counter is incremented of 1 (one) unit at each frame transmission.";
CM_ SG_ 299 CRC_ADAS_FD_INFO3 "CRC according to SAE J1850 standard at each frame transmission.";
CM_ SG_ 299 ACC_TORSts "Take Over Request status";
CM_ SG_ 299 ACC_Axle_Torque_Enabled "An enable bit that axle torque commands should be followed";
CM_ SG_ 299 ACC_Axle_Torque "ACC requested Axle Torque";
BA_DEF_ BO_ "CANFD_BRS" ENUM "0","1";
BA_DEF_ BO_ "VFrameFormat" ENUM "StandardCAN","ExtendedCAN","reserved","reserved","reserved","reserved","reserved","reserved","reserved","reserved","reserved","reserved","reserved","reserved","StandardCAN_FD","ExtendedCAN_FD";
BA_DEF_ BO_ "DiagConnection" HEX 0 65535;
BA_DEF_ BO_ "DiagState" ENUM "No","Yes";
BA_DEF_ BO_ "NmAsrMessage" ENUM "No","Yes";
BA_DEF_ BO_ "GenMsgDelayTime" INT 0 65535;
BA_DEF_ BO_ "GenMsgCycleTime" INT 0 65535;
BA_DEF_ BO_ "GenMsgCycleTimeFast" INT 0 65535;
BA_DEF_ BO_ "GenMsgStartDelayTime" INT 0 65535;
BA_DEF_ BO_ "GenMsgILSupport" ENUM "No","Yes";
BA_DEF_ BO_ "GenMsgNrOfRepetition" INT 0 255;
BA_DEF_ BO_ "GenMsgSendType" ENUM "Cyclic","NotUsed","NotUsed","NotUsed","NotUsed","NotUsed","NotUsed","NotUsed","NoMsgSendType";
BA_DEF_ BO_ "NmMessage" ENUM "No","Yes";
BA_DEF_ BO_ "DiagResponse" ENUM "No","Yes";
BA_DEF_ BO_ "Type" ENUM "P","C","PE","COC","PE_Cntrl","E","E_Cntrl","OC","S","BAF","DC","EM","MM","ISO-TP","-";
BA_DEF_ BO_ "DiagRequest" ENUM "No","Yes";
BA_DEF_ SG_ "GenSigTimeoutTime_ORC" INT 0 65535;
BA_DEF_ SG_ "GenSigTimeoutTime_MPAD" INT 0 65535;
BA_DEF_ SG_ "GenSigTimeoutTime_EVCU2" INT 0 65535;
BA_DEF_ SG_ "GenSigTimeoutTime_EPS" INT 0 65535;
BA_DEF_ SG_ "GenSigTimeoutTime_CVADAS" INT 0 65535;
BA_DEF_ SG_ "GenSigTimeoutTime_BSM2" INT 0 65535;
BA_DEF_ SG_ "GenSigTimeoutTime_BSM" INT 0 65535;
BA_DEF_ SG_ "GenSigTimeoutTime_ADCAM" INT 0 65535;
BA_DEF_ SG_ "GenSigSendType" ENUM "NotUsed","OnWrite","OnWriteWithRepetition","OnChange","OnChangeWithRepetition","IfActive","IfActiveWithRepetition","NoSigSendType";
BA_DEF_ SG_ "GenSigInactiveValue" INT 0 2147483647;
BA_DEF_ SG_ "GenSigStartValue" INT 0 2147483647;
BA_DEF_DEF_ "CANFD_BRS" "0";
BA_DEF_DEF_ "VFrameFormat" "StandardCAN_FD";
BA_DEF_DEF_ "DiagConnection" 0;
BA_DEF_DEF_ "DiagState" "No";
BA_DEF_DEF_ "NmAsrMessage" "No";
BA_DEF_DEF_ "GenMsgDelayTime" 0;
BA_DEF_DEF_ "GenMsgCycleTime" 0;
BA_DEF_DEF_ "GenMsgCycleTimeFast" 0;
BA_DEF_DEF_ "GenMsgStartDelayTime" 0;
BA_DEF_DEF_ "GenMsgILSupport" "No";
BA_DEF_DEF_ "GenMsgNrOfRepetition" 0;
BA_DEF_DEF_ "GenMsgSendType" "NoMsgSendType";
BA_DEF_DEF_ "NmMessage" "No";
BA_DEF_DEF_ "DiagResponse" "No";
BA_DEF_DEF_ "Type" "-";
BA_DEF_DEF_ "DiagRequest" "No";
BA_DEF_DEF_ "GenSigTimeoutTime_ORC" 2500;
BA_DEF_DEF_ "GenSigTimeoutTime_MPAD" 2500;
BA_DEF_DEF_ "GenSigTimeoutTime_EVCU2" 2500;
BA_DEF_DEF_ "GenSigTimeoutTime_EPS" 2500;
BA_DEF_DEF_ "GenSigTimeoutTime_CVADAS" 2500;
BA_DEF_DEF_ "GenSigTimeoutTime_BSM2" 2500;
BA_DEF_DEF_ "GenSigTimeoutTime_BSM" 2500;
BA_DEF_DEF_ "GenSigTimeoutTime_ADCAM" 2500;
BA_DEF_DEF_ "GenSigSendType" "NoSigSendType";
BA_DEF_DEF_ "GenSigInactiveValue" 0;
BA_DEF_DEF_ "GenSigStartValue" 0;
BA_ "CANFD_BRS" BO_ 2654486534 1;
BA_ "VFrameFormat" BO_ 2654486534 15;
BA_ "NmAsrMessage" BO_ 2654486534 1;
BA_ "NmMessage" BO_ 2654486534 1;
BA_ "Type" BO_ 2654486534 8;
BA_ "CANFD_BRS" BO_ 258 1;
BA_ "GenMsgCycleTime" BO_ 258 10;
BA_ "GenMsgILSupport" BO_ 258 1;
BA_ "GenMsgSendType" BO_ 258 0;
BA_ "Type" BO_ 258 1;
BA_ "CANFD_BRS" BO_ 2654486530 1;
BA_ "VFrameFormat" BO_ 2654486530 15;
BA_ "NmAsrMessage" BO_ 2654486530 1;
BA_ "NmMessage" BO_ 2654486530 1;
BA_ "Type" BO_ 2654486530 8;
BA_ "CANFD_BRS" BO_ 524 1;
BA_ "GenMsgCycleTime" BO_ 524 20;
BA_ "GenMsgILSupport" BO_ 524 1;
BA_ "GenMsgSendType" BO_ 524 0;
BA_ "Type" BO_ 524 1;
BA_ "CANFD_BRS" BO_ 257 1;
BA_ "GenMsgCycleTime" BO_ 257 10;
BA_ "GenMsgILSupport" BO_ 257 1;
BA_ "GenMsgSendType" BO_ 257 0;
BA_ "Type" BO_ 257 1;
BA_ "CANFD_BRS" BO_ 2654486552 1;
BA_ "VFrameFormat" BO_ 2654486552 15;
BA_ "NmAsrMessage" BO_ 2654486552 1;
BA_ "NmMessage" BO_ 2654486552 1;
BA_ "Type" BO_ 2654486552 8;
BA_ "CANFD_BRS" BO_ 2654486676 1;
BA_ "VFrameFormat" BO_ 2654486676 15;
BA_ "NmAsrMessage" BO_ 2654486676 1;
BA_ "NmMessage" BO_ 2654486676 1;
BA_ "Type" BO_ 2654486676 8;
BA_ "CANFD_BRS" BO_ 727 1;
BA_ "GenMsgCycleTime" BO_ 727 40;
BA_ "GenMsgILSupport" BO_ 727 1;
BA_ "GenMsgSendType" BO_ 727 0;
BA_ "Type" BO_ 727 1;
BA_ "CANFD_BRS" BO_ 726 1;
BA_ "GenMsgCycleTime" BO_ 726 40;
BA_ "GenMsgILSupport" BO_ 726 1;
BA_ "GenMsgSendType" BO_ 726 0;
BA_ "Type" BO_ 726 1;
BA_ "CANFD_BRS" BO_ 1156 1;
BA_ "GenMsgDelayTime" BO_ 1156 20;
BA_ "GenMsgCycleTime" BO_ 1156 500;
BA_ "GenMsgCycleTimeFast" BO_ 1156 20;
BA_ "GenMsgILSupport" BO_ 1156 1;
BA_ "GenMsgNrOfRepetition" BO_ 1156 2;
BA_ "GenMsgSendType" BO_ 1156 0;
BA_ "Type" BO_ 1156 3;
BA_ "CANFD_BRS" BO_ 280 1;
BA_ "GenMsgCycleTime" BO_ 280 10;
BA_ "GenMsgILSupport" BO_ 280 1;
BA_ "GenMsgSendType" BO_ 280 0;
BA_ "Type" BO_ 280 1;
BA_ "CANFD_BRS" BO_ 2654486554 1;
BA_ "VFrameFormat" BO_ 2654486554 15;
BA_ "NmAsrMessage" BO_ 2654486554 1;
BA_ "NmMessage" BO_ 2654486554 1;
BA_ "Type" BO_ 2654486554 8;
BA_ "GenMsgCycleTime" BO_ 205 10;
BA_ "GenMsgILSupport" BO_ 205 1;
BA_ "GenMsgSendType" BO_ 205 0;
BA_ "Type" BO_ 205 1;
BA_ "CANFD_BRS" BO_ 205 1;
BA_ "CANFD_BRS" BO_ 204 1;
BA_ "GenMsgCycleTime" BO_ 204 10;
BA_ "GenMsgILSupport" BO_ 204 1;
BA_ "GenMsgSendType" BO_ 204 0;
BA_ "Type" BO_ 204 1;
BA_ "CANFD_BRS" BO_ 292 1;
BA_ "GenMsgCycleTime" BO_ 292 10;
BA_ "GenMsgILSupport" BO_ 292 1;
BA_ "GenMsgSendType" BO_ 292 0;
BA_ "Type" BO_ 292 1;
BA_ "CANFD_BRS" BO_ 2654486701 1;
BA_ "VFrameFormat" BO_ 2654486701 15;
BA_ "NmAsrMessage" BO_ 2654486701 1;
BA_ "NmMessage" BO_ 2654486701 1;
BA_ "Type" BO_ 2654486701 8;
BA_ "CANFD_BRS" BO_ 2654486689 1;
BA_ "VFrameFormat" BO_ 2654486689 15;
BA_ "NmAsrMessage" BO_ 2654486689 1;
BA_ "NmMessage" BO_ 2654486689 1;
BA_ "Type" BO_ 2654486689 8;
BA_ "CANFD_BRS" BO_ 299 1;
BA_ "GenMsgCycleTime" BO_ 299 10;
BA_ "GenMsgILSupport" BO_ 299 1;
BA_ "GenMsgSendType" BO_ 299 0;
BA_ "Type" BO_ 299 1;
BA_ "GenSigTimeoutTime_ORC" SG_ 2654486530 CBV_bit6_PartialNtwInfBit 0;
BA_ "GenSigTimeoutTime_MPAD" SG_ 2654486530 CBV_bit6_PartialNtwInfBit 0;
BA_ "GenSigTimeoutTime_EVCU2" SG_ 2654486530 CBV_bit6_PartialNtwInfBit 0;
BA_ "GenSigTimeoutTime_EPS" SG_ 2654486530 CBV_bit6_PartialNtwInfBit 0;
BA_ "GenSigTimeoutTime_CVADAS" SG_ 2654486530 CBV_bit6_PartialNtwInfBit 0;
BA_ "GenSigTimeoutTime_BSM2" SG_ 2654486530 CBV_bit6_PartialNtwInfBit 0;
BA_ "GenSigTimeoutTime_BSM" SG_ 2654486530 CBV_bit6_PartialNtwInfBit 0;
BA_ "GenSigTimeoutTime_ADCAM" SG_ 2654486530 CBV_bit6_PartialNtwInfBit 0;
BA_ "GenSigTimeoutTime_ORC" SG_ 2654486676 CBV_bit6_PartialNtwInfBit 0;
BA_ "GenSigTimeoutTime_MPAD" SG_ 2654486676 CBV_bit6_PartialNtwInfBit 0;
BA_ "GenSigTimeoutTime_EVCU2" SG_ 2654486676 CBV_bit6_PartialNtwInfBit 0;
BA_ "GenSigTimeoutTime_EPS" SG_ 2654486676 CBV_bit6_PartialNtwInfBit 0;
BA_ "GenSigTimeoutTime_CVADAS" SG_ 2654486676 CBV_bit6_PartialNtwInfBit 0;
BA_ "GenSigTimeoutTime_BSM2" SG_ 2654486676 CBV_bit6_PartialNtwInfBit 0;
BA_ "GenSigTimeoutTime_BSM" SG_ 2654486676 CBV_bit6_PartialNtwInfBit 0;
BA_ "GenSigTimeoutTime_ADCAM" SG_ 2654486676 CBV_bit6_PartialNtwInfBit 0;
BA_ "GenSigTimeoutTime_ORC" SG_ 2654486530 CBV_bit7 0;
BA_ "GenSigTimeoutTime_MPAD" SG_ 2654486530 CBV_bit7 0;
BA_ "GenSigTimeoutTime_EVCU2" SG_ 2654486530 CBV_bit7 0;
BA_ "GenSigTimeoutTime_EPS" SG_ 2654486530 CBV_bit7 0;
BA_ "GenSigTimeoutTime_CVADAS" SG_ 2654486530 CBV_bit7 0;
BA_ "GenSigTimeoutTime_BSM2" SG_ 2654486530 CBV_bit7 0;
BA_ "GenSigTimeoutTime_BSM" SG_ 2654486530 CBV_bit7 0;
BA_ "GenSigTimeoutTime_ADCAM" SG_ 2654486530 CBV_bit7 0;
BA_ "GenSigTimeoutTime_ORC" SG_ 2654486676 CBV_bit7 0;
BA_ "GenSigTimeoutTime_MPAD" SG_ 2654486676 CBV_bit7 0;
BA_ "GenSigTimeoutTime_EVCU2" SG_ 2654486676 CBV_bit7 0;
BA_ "GenSigTimeoutTime_EPS" SG_ 2654486676 CBV_bit7 0;
BA_ "GenSigTimeoutTime_CVADAS" SG_ 2654486676 CBV_bit7 0;
BA_ "GenSigTimeoutTime_BSM2" SG_ 2654486676 CBV_bit7 0;
BA_ "GenSigTimeoutTime_BSM" SG_ 2654486676 CBV_bit7 0;
BA_ "GenSigTimeoutTime_ADCAM" SG_ 2654486676 CBV_bit7 0;
BA_ "GenSigTimeoutTime_ORC" SG_ 2654486534 CBV_bit7 0;
BA_ "GenSigTimeoutTime_MPAD" SG_ 2654486534 CBV_bit7 0;
BA_ "GenSigTimeoutTime_EVCU2" SG_ 2654486534 CBV_bit7 0;
BA_ "GenSigTimeoutTime_EPS" SG_ 2654486534 CBV_bit7 0;
BA_ "GenSigTimeoutTime_CVADAS" SG_ 2654486534 CBV_bit7 0;
BA_ "GenSigTimeoutTime_ORC" SG_ 2654486676 SourceNodeIdentifier 0;
BA_ "GenSigTimeoutTime_MPAD" SG_ 2654486676 SourceNodeIdentifier 0;
BA_ "GenSigTimeoutTime_EVCU2" SG_ 2654486676 SourceNodeIdentifier 0;
BA_ "GenSigTimeoutTime_EPS" SG_ 2654486676 SourceNodeIdentifier 0;
BA_ "GenSigTimeoutTime_CVADAS" SG_ 2654486676 SourceNodeIdentifier 0;
BA_ "GenSigTimeoutTime_BSM2" SG_ 2654486676 SourceNodeIdentifier 0;
BA_ "GenSigTimeoutTime_BSM" SG_ 2654486676 SourceNodeIdentifier 0;
BA_ "GenSigTimeoutTime_ADCAM" SG_ 2654486676 SourceNodeIdentifier 0;
BA_ "GenSigTimeoutTime_ORC" SG_ 2654486534 SourceNodeIdentifier 0;
BA_ "GenSigTimeoutTime_MPAD" SG_ 2654486534 SourceNodeIdentifier 0;
BA_ "GenSigTimeoutTime_EVCU2" SG_ 2654486534 SourceNodeIdentifier 0;
BA_ "GenSigTimeoutTime_EPS" SG_ 2654486534 SourceNodeIdentifier 0;
BA_ "GenSigTimeoutTime_CVADAS" SG_ 2654486534 SourceNodeIdentifier 0;
BA_ "GenSigTimeoutTime_BSM2" SG_ 2654486534 SourceNodeIdentifier 0;
BA_ "GenSigTimeoutTime_BSM" SG_ 2654486534 SourceNodeIdentifier 0;
BA_ "GenSigTimeoutTime_ADCAM" SG_ 2654486534 SourceNodeIdentifier 0;
BA_ "GenSigTimeoutTime_ORC" SG_ 2654486530 SourceNodeIdentifier 0;
BA_ "GenSigTimeoutTime_MPAD" SG_ 2654486530 SourceNodeIdentifier 0;
BA_ "GenSigTimeoutTime_EVCU2" SG_ 2654486530 SourceNodeIdentifier 0;
BA_ "GenSigTimeoutTime_EPS" SG_ 2654486530 SourceNodeIdentifier 0;
BA_ "GenSigTimeoutTime_CVADAS" SG_ 2654486530 SourceNodeIdentifier 0;
BA_ "GenSigTimeoutTime_BSM2" SG_ 2654486530 SourceNodeIdentifier 0;
BA_ "GenSigTimeoutTime_BSM" SG_ 2654486530 SourceNodeIdentifier 0;
BA_ "GenSigTimeoutTime_ADCAM" SG_ 2654486530 SourceNodeIdentifier 0;
BA_ "GenSigTimeoutTime_ORC" SG_ 2654486530 CBV_bit2 0;
BA_ "GenSigTimeoutTime_MPAD" SG_ 2654486530 CBV_bit2 0;
BA_ "GenSigTimeoutTime_EVCU2" SG_ 2654486530 CBV_bit2 0;
BA_ "GenSigTimeoutTime_EPS" SG_ 2654486530 CBV_bit2 0;
BA_ "GenSigTimeoutTime_CVADAS" SG_ 2654486530 CBV_bit2 0;
BA_ "GenSigTimeoutTime_BSM2" SG_ 2654486530 CBV_bit2 0;
BA_ "GenSigTimeoutTime_BSM" SG_ 2654486530 CBV_bit2 0;
BA_ "GenSigTimeoutTime_ADCAM" SG_ 2654486530 CBV_bit2 0;
BA_ "GenSigTimeoutTime_ORC" SG_ 2654486676 CBV_bit2 0;
BA_ "GenSigTimeoutTime_MPAD" SG_ 2654486676 CBV_bit2 0;
BA_ "GenSigTimeoutTime_EVCU2" SG_ 2654486676 CBV_bit2 0;
BA_ "GenSigTimeoutTime_EPS" SG_ 2654486676 CBV_bit2 0;
BA_ "GenSigTimeoutTime_CVADAS" SG_ 2654486676 CBV_bit2 0;
BA_ "GenSigTimeoutTime_BSM2" SG_ 2654486676 CBV_bit2 0;
BA_ "GenSigTimeoutTime_BSM" SG_ 2654486676 CBV_bit2 0;
BA_ "GenSigTimeoutTime_ADCAM" SG_ 2654486676 CBV_bit2 0;
BA_ "GenSigTimeoutTime_ORC" SG_ 2654486530 CBV_bit3_NMCoordinatorBit 0;
BA_ "GenSigTimeoutTime_MPAD" SG_ 2654486530 CBV_bit3_NMCoordinatorBit 0;
BA_ "GenSigTimeoutTime_EVCU2" SG_ 2654486530 CBV_bit3_NMCoordinatorBit 0;
BA_ "GenSigTimeoutTime_EPS" SG_ 2654486530 CBV_bit3_NMCoordinatorBit 0;
BA_ "GenSigTimeoutTime_CVADAS" SG_ 2654486530 CBV_bit3_NMCoordinatorBit 0;
BA_ "GenSigTimeoutTime_BSM2" SG_ 2654486530 CBV_bit3_NMCoordinatorBit 0;
BA_ "GenSigTimeoutTime_BSM" SG_ 2654486530 CBV_bit3_NMCoordinatorBit 0;
BA_ "GenSigTimeoutTime_ADCAM" SG_ 2654486530 CBV_bit3_NMCoordinatorBit 0;
BA_ "GenSigTimeoutTime_ORC" SG_ 2654486676 CBV_bit3_NMCoordinatorBit 0;
BA_ "GenSigTimeoutTime_MPAD" SG_ 2654486676 CBV_bit3_NMCoordinatorBit 0;
BA_ "GenSigTimeoutTime_EVCU2" SG_ 2654486676 CBV_bit3_NMCoordinatorBit 0;
BA_ "GenSigTimeoutTime_EPS" SG_ 2654486676 CBV_bit3_NMCoordinatorBit 0;
BA_ "GenSigTimeoutTime_CVADAS" SG_ 2654486676 CBV_bit3_NMCoordinatorBit 0;
BA_ "GenSigTimeoutTime_BSM2" SG_ 2654486676 CBV_bit3_NMCoordinatorBit 0;
BA_ "GenSigTimeoutTime_BSM" SG_ 2654486676 CBV_bit3_NMCoordinatorBit 0;
BA_ "GenSigTimeoutTime_ADCAM" SG_ 2654486676 CBV_bit3_NMCoordinatorBit 0;
BA_ "GenSigTimeoutTime_ORC" SG_ 2654486530 CBV_bit5 0;
BA_ "GenSigTimeoutTime_MPAD" SG_ 2654486530 CBV_bit5 0;
BA_ "GenSigTimeoutTime_EVCU2" SG_ 2654486530 CBV_bit5 0;
BA_ "GenSigTimeoutTime_EPS" SG_ 2654486530 CBV_bit5 0;
BA_ "GenSigTimeoutTime_CVADAS" SG_ 2654486530 CBV_bit5 0;
BA_ "GenSigTimeoutTime_BSM2" SG_ 2654486530 CBV_bit5 0;
BA_ "GenSigTimeoutTime_BSM" SG_ 2654486530 CBV_bit5 0;
BA_ "GenSigTimeoutTime_ADCAM" SG_ 2654486530 CBV_bit5 0;
BA_ "GenSigTimeoutTime_ORC" SG_ 2654486676 CBV_bit5 0;
BA_ "GenSigTimeoutTime_MPAD" SG_ 2654486676 CBV_bit5 0;
BA_ "GenSigTimeoutTime_EVCU2" SG_ 2654486676 CBV_bit5 0;
BA_ "GenSigTimeoutTime_EPS" SG_ 2654486676 CBV_bit5 0;
BA_ "GenSigTimeoutTime_CVADAS" SG_ 2654486676 CBV_bit5 0;
BA_ "GenSigTimeoutTime_BSM2" SG_ 2654486676 CBV_bit5 0;
BA_ "GenSigTimeoutTime_BSM" SG_ 2654486676 CBV_bit5 0;
BA_ "GenSigTimeoutTime_ADCAM" SG_ 2654486676 CBV_bit5 0;
BA_ "GenSigTimeoutTime_ORC" SG_ 2654486530 CBV_bit4_ActiveWakeupBit 0;
BA_ "GenSigTimeoutTime_MPAD" SG_ 2654486530 CBV_bit4_ActiveWakeupBit 0;
BA_ "GenSigTimeoutTime_EVCU2" SG_ 2654486530 CBV_bit4_ActiveWakeupBit 0;
BA_ "GenSigTimeoutTime_EPS" SG_ 2654486530 CBV_bit4_ActiveWakeupBit 0;
BA_ "GenSigTimeoutTime_CVADAS" SG_ 2654486530 CBV_bit4_ActiveWakeupBit 0;
BA_ "GenSigTimeoutTime_BSM2" SG_ 2654486530 CBV_bit4_ActiveWakeupBit 0;
BA_ "GenSigTimeoutTime_BSM" SG_ 2654486530 CBV_bit4_ActiveWakeupBit 0;
BA_ "GenSigTimeoutTime_ADCAM" SG_ 2654486530 CBV_bit4_ActiveWakeupBit 0;
BA_ "GenSigTimeoutTime_ORC" SG_ 2654486676 CBV_bit4_ActiveWakeupBit 0;
BA_ "GenSigTimeoutTime_MPAD" SG_ 2654486676 CBV_bit4_ActiveWakeupBit 0;
BA_ "GenSigTimeoutTime_EVCU2" SG_ 2654486676 CBV_bit4_ActiveWakeupBit 0;
BA_ "GenSigTimeoutTime_EPS" SG_ 2654486676 CBV_bit4_ActiveWakeupBit 0;
BA_ "GenSigTimeoutTime_CVADAS" SG_ 2654486676 CBV_bit4_ActiveWakeupBit 0;
BA_ "GenSigTimeoutTime_BSM2" SG_ 2654486676 CBV_bit4_ActiveWakeupBit 0;
BA_ "GenSigTimeoutTime_BSM" SG_ 2654486676 CBV_bit4_ActiveWakeupBit 0;
BA_ "GenSigTimeoutTime_ADCAM" SG_ 2654486676 CBV_bit4_ActiveWakeupBit 0;
BA_ "GenSigTimeoutTime_ORC" SG_ 2654486530 CBV_bit1 0;
BA_ "GenSigTimeoutTime_MPAD" SG_ 2654486530 CBV_bit1 0;
BA_ "GenSigTimeoutTime_EVCU2" SG_ 2654486530 CBV_bit1 0;
BA_ "GenSigTimeoutTime_EPS" SG_ 2654486530 CBV_bit1 0;
BA_ "GenSigTimeoutTime_CVADAS" SG_ 2654486530 CBV_bit1 0;
BA_ "GenSigTimeoutTime_BSM2" SG_ 2654486530 CBV_bit1 0;
BA_ "GenSigTimeoutTime_BSM" SG_ 2654486530 CBV_bit1 0;
BA_ "GenSigTimeoutTime_ADCAM" SG_ 2654486530 CBV_bit1 0;
BA_ "GenSigTimeoutTime_ORC" SG_ 2654486530 CBV_bit0_RepeatMessageRequestBit 0;
BA_ "GenSigTimeoutTime_MPAD" SG_ 2654486530 CBV_bit0_RepeatMessageRequestBit 0;
BA_ "GenSigTimeoutTime_EVCU2" SG_ 2654486530 CBV_bit0_RepeatMessageRequestBit 0;
BA_ "GenSigTimeoutTime_EPS" SG_ 2654486530 CBV_bit0_RepeatMessageRequestBit 0;
BA_ "GenSigTimeoutTime_CVADAS" SG_ 2654486530 CBV_bit0_RepeatMessageRequestBit 0;
BA_ "GenSigTimeoutTime_BSM2" SG_ 2654486530 CBV_bit0_RepeatMessageRequestBit 0;
BA_ "GenSigTimeoutTime_BSM" SG_ 2654486530 CBV_bit0_RepeatMessageRequestBit 0;
BA_ "GenSigTimeoutTime_ADCAM" SG_ 2654486530 CBV_bit0_RepeatMessageRequestBit 0;
BA_ "GenSigTimeoutTime_ORC" SG_ 2654486676 CBV_bit0_RepeatMessageRequestBit 0;
BA_ "GenSigTimeoutTime_MPAD" SG_ 2654486676 CBV_bit0_RepeatMessageRequestBit 0;
BA_ "GenSigTimeoutTime_EVCU2" SG_ 2654486676 CBV_bit0_RepeatMessageRequestBit 0;
BA_ "GenSigTimeoutTime_EPS" SG_ 2654486676 CBV_bit0_RepeatMessageRequestBit 0;
BA_ "GenSigTimeoutTime_CVADAS" SG_ 2654486676 CBV_bit0_RepeatMessageRequestBit 0;
BA_ "GenSigTimeoutTime_BSM2" SG_ 2654486676 CBV_bit0_RepeatMessageRequestBit 0;
BA_ "GenSigTimeoutTime_BSM" SG_ 2654486676 CBV_bit0_RepeatMessageRequestBit 0;
BA_ "GenSigTimeoutTime_ADCAM" SG_ 2654486676 CBV_bit0_RepeatMessageRequestBit 0;
BA_ "GenSigTimeoutTime_ORC" SG_ 2654486676 CBV_bit1 0;
BA_ "GenSigTimeoutTime_MPAD" SG_ 2654486676 CBV_bit1 0;
BA_ "GenSigTimeoutTime_EVCU2" SG_ 2654486676 CBV_bit1 0;
BA_ "GenSigTimeoutTime_EPS" SG_ 2654486676 CBV_bit1 0;
BA_ "GenSigTimeoutTime_CVADAS" SG_ 2654486676 CBV_bit1 0;
BA_ "GenSigTimeoutTime_BSM2" SG_ 2654486676 CBV_bit1 0;
BA_ "GenSigTimeoutTime_BSM" SG_ 2654486676 CBV_bit1 0;
BA_ "GenSigTimeoutTime_ADCAM" SG_ 2654486676 CBV_bit1 0;
BA_ "GenSigTimeoutTime_MPAD" SG_ 292 BPCM_HV_Trac_Bus_Sts 0;
BA_ "GenSigTimeoutTime_EVCU2" SG_ 292 BPCM_HV_Trac_Bus_Sts 0;
BA_ "GenSigTimeoutTime_EPS" SG_ 292 BPCM_HV_Trac_Bus_Sts 0;
BA_ "GenSigTimeoutTime_CVADAS" SG_ 292 BPCM_HV_Trac_Bus_Sts 0;
BA_ "GenSigTimeoutTime_BSM2" SG_ 292 BPCM_HV_Trac_Bus_Sts 0;
BA_ "GenSigTimeoutTime_BSM" SG_ 292 BPCM_HV_Trac_Bus_Sts 0;
BA_ "GenSigTimeoutTime_ADCAM" SG_ 292 BPCM_HV_Trac_Bus_Sts 0;
BA_ "GenSigTimeoutTime_ORC" SG_ 204 Total_AxleTorque_Min 0;
BA_ "GenSigTimeoutTime_EVCU2" SG_ 204 Total_AxleTorque_Min 0;
BA_ "GenSigTimeoutTime_EPS" SG_ 204 Total_AxleTorque_Min 0;
BA_ "GenSigTimeoutTime_CVADAS" SG_ 204 Total_AxleTorque_Min 0;
BA_ "GenSigTimeoutTime_BSM2" SG_ 204 Total_AxleTorque_Min 0;
BA_ "GenSigStartValue" SG_ 204 Total_AxleTorque_Min 32767;
BA_ "GenSigTimeoutTime_ORC" SG_ 204 Total_AxleTorque_Max 0;
BA_ "GenSigTimeoutTime_EVCU2" SG_ 204 Total_AxleTorque_Max 0;
BA_ "GenSigTimeoutTime_EPS" SG_ 204 Total_AxleTorque_Max 0;
BA_ "GenSigTimeoutTime_CVADAS" SG_ 204 Total_AxleTorque_Max 0;
BA_ "GenSigTimeoutTime_BSM2" SG_ 204 Total_AxleTorque_Max 0;
BA_ "GenSigTimeoutTime_BSM" SG_ 204 Total_AxleTorque_Max 0;
BA_ "GenSigStartValue" SG_ 204 Total_AxleTorque_Max 32767;
BA_ "GenSigTimeoutTime_ORC" SG_ 204 Axle_Torque_DrvReqMod 0;
BA_ "GenSigTimeoutTime_EVCU2" SG_ 204 Axle_Torque_DrvReqMod 0;
BA_ "GenSigTimeoutTime_EPS" SG_ 204 Axle_Torque_DrvReqMod 0;
BA_ "GenSigTimeoutTime_CVADAS" SG_ 204 Axle_Torque_DrvReqMod 0;
BA_ "GenSigTimeoutTime_BSM2" SG_ 204 Axle_Torque_DrvReqMod 0;
BA_ "GenSigStartValue" SG_ 204 Axle_Torque_DrvReqMod 32768;
BA_ "GenSigTimeoutTime_ORC" SG_ 292 BPCM_HV_Trac_Main_Contac_Sts 0;
BA_ "GenSigTimeoutTime_MPAD" SG_ 292 BPCM_HV_Trac_Main_Contac_Sts 0;
BA_ "GenSigTimeoutTime_EVCU2" SG_ 292 BPCM_HV_Trac_Main_Contac_Sts 0;
BA_ "GenSigTimeoutTime_EPS" SG_ 292 BPCM_HV_Trac_Main_Contac_Sts 0;
BA_ "GenSigTimeoutTime_CVADAS" SG_ 292 BPCM_HV_Trac_Main_Contac_Sts 0;
BA_ "GenSigTimeoutTime_BSM2" SG_ 292 BPCM_HV_Trac_Main_Contac_Sts 0;
BA_ "GenSigTimeoutTime_BSM" SG_ 292 BPCM_HV_Trac_Main_Contac_Sts 0;
BA_ "GenSigTimeoutTime_ADCAM" SG_ 292 BPCM_HV_Trac_Main_Contac_Sts 0;
BA_ "GenSigTimeoutTime_ORC" SG_ 204 Front_Axle_Regen_Capacity 0;
BA_ "GenSigTimeoutTime_MPAD" SG_ 204 Front_Axle_Regen_Capacity 0;
BA_ "GenSigTimeoutTime_EVCU2" SG_ 204 Front_Axle_Regen_Capacity 0;
BA_ "GenSigTimeoutTime_EPS" SG_ 204 Front_Axle_Regen_Capacity 0;
BA_ "GenSigTimeoutTime_CVADAS" SG_ 204 Front_Axle_Regen_Capacity 0;
BA_ "GenSigTimeoutTime_BSM2" SG_ 204 Front_Axle_Regen_Capacity 0;
BA_ "GenSigTimeoutTime_ADCAM" SG_ 204 Front_Axle_Regen_Capacity 0;
BA_ "GenSigTimeoutTime_ORC" SG_ 204 Front_Axle_Est_Regen_Torq 0;
BA_ "GenSigTimeoutTime_MPAD" SG_ 204 Front_Axle_Est_Regen_Torq 0;
BA_ "GenSigTimeoutTime_EVCU2" SG_ 204 Front_Axle_Est_Regen_Torq 0;
BA_ "GenSigTimeoutTime_EPS" SG_ 204 Front_Axle_Est_Regen_Torq 0;
BA_ "GenSigTimeoutTime_CVADAS" SG_ 204 Front_Axle_Est_Regen_Torq 0;
BA_ "GenSigTimeoutTime_BSM2" SG_ 204 Front_Axle_Est_Regen_Torq 0;
BA_ "GenSigTimeoutTime_ADCAM" SG_ 204 Front_Axle_Est_Regen_Torq 0;
BA_ "GenSigTimeoutTime_ORC" SG_ 204 MessageCounter_AXLE_TORQUE_FD_1 0;
BA_ "GenSigTimeoutTime_EVCU2" SG_ 204 MessageCounter_AXLE_TORQUE_FD_1 0;
BA_ "GenSigTimeoutTime_EPS" SG_ 204 MessageCounter_AXLE_TORQUE_FD_1 0;
BA_ "GenSigTimeoutTime_CVADAS" SG_ 204 MessageCounter_AXLE_TORQUE_FD_1 0;
BA_ "GenSigTimeoutTime_BSM2" SG_ 204 MessageCounter_AXLE_TORQUE_FD_1 0;
BA_ "GenSigTimeoutTime_BSM" SG_ 204 MessageCounter_AXLE_TORQUE_FD_1 0;
BA_ "GenSigTimeoutTime_ORC" SG_ 204 CRC_AXLE_TORQUE_FD_1 0;
BA_ "GenSigTimeoutTime_EVCU2" SG_ 204 CRC_AXLE_TORQUE_FD_1 0;
BA_ "GenSigTimeoutTime_EPS" SG_ 204 CRC_AXLE_TORQUE_FD_1 0;
BA_ "GenSigTimeoutTime_CVADAS" SG_ 204 CRC_AXLE_TORQUE_FD_1 0;
BA_ "GenSigTimeoutTime_BSM2" SG_ 204 CRC_AXLE_TORQUE_FD_1 0;
BA_ "GenSigTimeoutTime_BSM" SG_ 204 CRC_AXLE_TORQUE_FD_1 0;
BA_ "GenSigTimeoutTime_ORC" SG_ 204 Rear_Axle_Regen_Capacity 0;
BA_ "GenSigTimeoutTime_MPAD" SG_ 204 Rear_Axle_Regen_Capacity 0;
BA_ "GenSigTimeoutTime_EVCU2" SG_ 204 Rear_Axle_Regen_Capacity 0;
BA_ "GenSigTimeoutTime_EPS" SG_ 204 Rear_Axle_Regen_Capacity 0;
BA_ "GenSigTimeoutTime_CVADAS" SG_ 204 Rear_Axle_Regen_Capacity 0;
BA_ "GenSigTimeoutTime_BSM2" SG_ 204 Rear_Axle_Regen_Capacity 0;
BA_ "GenSigTimeoutTime_ADCAM" SG_ 204 Rear_Axle_Regen_Capacity 0;
BA_ "GenSigTimeoutTime_ORC" SG_ 204 Rear_Axle_Est_Regen_Torq 0;
BA_ "GenSigTimeoutTime_MPAD" SG_ 204 Rear_Axle_Est_Regen_Torq 0;
BA_ "GenSigTimeoutTime_EVCU2" SG_ 204 Rear_Axle_Est_Regen_Torq 0;
BA_ "GenSigTimeoutTime_EPS" SG_ 204 Rear_Axle_Est_Regen_Torq 0;
BA_ "GenSigTimeoutTime_CVADAS" SG_ 204 Rear_Axle_Est_Regen_Torq 0;
BA_ "GenSigTimeoutTime_BSM2" SG_ 204 Rear_Axle_Est_Regen_Torq 0;
BA_ "GenSigTimeoutTime_ADCAM" SG_ 204 Rear_Axle_Est_Regen_Torq 0;
BA_ "GenSigTimeoutTime_ORC" SG_ 204 Axle_TorqueStatic_D_TTC 0;
BA_ "GenSigTimeoutTime_EVCU2" SG_ 204 Axle_TorqueStatic_D_TTC 0;
BA_ "GenSigTimeoutTime_EPS" SG_ 204 Axle_TorqueStatic_D_TTC 0;
BA_ "GenSigTimeoutTime_CVADAS" SG_ 204 Axle_TorqueStatic_D_TTC 0;
BA_ "GenSigTimeoutTime_BSM2" SG_ 204 Axle_TorqueStatic_D_TTC 0;
BA_ "GenSigStartValue" SG_ 204 Axle_TorqueStatic_D_TTC 32767;
BA_ "GenSigTimeoutTime_ORC" SG_ 292 BPCM_HV_SOC 0;
BA_ "GenSigTimeoutTime_MPAD" SG_ 292 BPCM_HV_SOC 0;
BA_ "GenSigTimeoutTime_EVCU2" SG_ 292 BPCM_HV_SOC 0;
BA_ "GenSigTimeoutTime_EPS" SG_ 292 BPCM_HV_SOC 0;
BA_ "GenSigTimeoutTime_CVADAS" SG_ 292 BPCM_HV_SOC 0;
BA_ "GenSigTimeoutTime_BSM2" SG_ 292 BPCM_HV_SOC 0;
BA_ "GenSigTimeoutTime_ADCAM" SG_ 292 BPCM_HV_SOC 0;
BA_ "GenSigTimeoutTime_MPAD" SG_ 292 BPCM_HV_InternalVoltage 0;
BA_ "GenSigTimeoutTime_EVCU2" SG_ 292 BPCM_HV_InternalVoltage 0;
BA_ "GenSigTimeoutTime_EPS" SG_ 292 BPCM_HV_InternalVoltage 0;
BA_ "GenSigTimeoutTime_CVADAS" SG_ 292 BPCM_HV_InternalVoltage 0;
BA_ "GenSigTimeoutTime_BSM2" SG_ 292 BPCM_HV_InternalVoltage 0;
BA_ "GenSigTimeoutTime_BSM" SG_ 292 BPCM_HV_InternalVoltage 0;
BA_ "GenSigTimeoutTime_ADCAM" SG_ 292 BPCM_HV_InternalVoltage 0;
BA_ "GenSigTimeoutTime_ORC" SG_ 204 Front_AxleTorque_Max 0;
BA_ "GenSigTimeoutTime_MPAD" SG_ 204 Front_AxleTorque_Max 0;
BA_ "GenSigTimeoutTime_EVCU2" SG_ 204 Front_AxleTorque_Max 0;
BA_ "GenSigTimeoutTime_EPS" SG_ 204 Front_AxleTorque_Max 0;
BA_ "GenSigTimeoutTime_CVADAS" SG_ 204 Front_AxleTorque_Max 0;
BA_ "GenSigTimeoutTime_BSM2" SG_ 204 Front_AxleTorque_Max 0;
BA_ "GenSigTimeoutTime_ADCAM" SG_ 204 Front_AxleTorque_Max 0;
BA_ "GenSigStartValue" SG_ 204 Front_AxleTorque_Max 32767;
BA_ "GenSigTimeoutTime_ORC" SG_ 204 Rear_AxleTorque_Min 0;
BA_ "GenSigTimeoutTime_MPAD" SG_ 204 Rear_AxleTorque_Min 0;
BA_ "GenSigTimeoutTime_EVCU2" SG_ 204 Rear_AxleTorque_Min 0;
BA_ "GenSigTimeoutTime_EPS" SG_ 204 Rear_AxleTorque_Min 0;
BA_ "GenSigTimeoutTime_CVADAS" SG_ 204 Rear_AxleTorque_Min 0;
BA_ "GenSigTimeoutTime_BSM2" SG_ 204 Rear_AxleTorque_Min 0;
BA_ "GenSigTimeoutTime_ADCAM" SG_ 204 Rear_AxleTorque_Min 0;
BA_ "GenSigStartValue" SG_ 204 Rear_AxleTorque_Min 32767;
BA_ "GenSigTimeoutTime_ORC" SG_ 204 Rear_AxleTorque_Max 0;
BA_ "GenSigTimeoutTime_MPAD" SG_ 204 Rear_AxleTorque_Max 0;
BA_ "GenSigTimeoutTime_EVCU2" SG_ 204 Rear_AxleTorque_Max 0;
BA_ "GenSigTimeoutTime_EPS" SG_ 204 Rear_AxleTorque_Max 0;
BA_ "GenSigTimeoutTime_CVADAS" SG_ 204 Rear_AxleTorque_Max 0;
BA_ "GenSigTimeoutTime_BSM2" SG_ 204 Rear_AxleTorque_Max 0;
BA_ "GenSigTimeoutTime_ADCAM" SG_ 204 Rear_AxleTorque_Max 0;
BA_ "GenSigStartValue" SG_ 204 Rear_AxleTorque_Max 32767;
BA_ "GenSigTimeoutTime_ORC" SG_ 204 Front_AxleTorque_Min 0;
BA_ "GenSigTimeoutTime_MPAD" SG_ 204 Front_AxleTorque_Min 0;
BA_ "GenSigTimeoutTime_EVCU2" SG_ 204 Front_AxleTorque_Min 0;
BA_ "GenSigTimeoutTime_EPS" SG_ 204 Front_AxleTorque_Min 0;
BA_ "GenSigTimeoutTime_CVADAS" SG_ 204 Front_AxleTorque_Min 0;
BA_ "GenSigTimeoutTime_BSM2" SG_ 204 Front_AxleTorque_Min 0;
BA_ "GenSigTimeoutTime_ADCAM" SG_ 204 Front_AxleTorque_Min 0;
BA_ "GenSigStartValue" SG_ 204 Front_AxleTorque_Min 32767;
BA_ "GenSigTimeoutTime_ORC" SG_ 299 MessageCounter_ADAS_FD_INFO3 0;
BA_ "GenSigTimeoutTime_EVCU2" SG_ 299 MessageCounter_ADAS_FD_INFO3 0;
BA_ "GenSigTimeoutTime_ORC" SG_ 299 ACC_Axle_Torque_Enabled 0;
BA_ "GenSigTimeoutTime_MPAD" SG_ 299 ACC_Axle_Torque_Enabled 0;
BA_ "GenSigTimeoutTime_EVCU2" SG_ 299 ACC_Axle_Torque_Enabled 0;
BA_ "GenSigTimeoutTime_EPS" SG_ 299 ACC_Axle_Torque_Enabled 0;
BA_ "GenSigTimeoutTime_CVADAS" SG_ 299 ACC_Axle_Torque_Enabled 0;
BA_ "GenSigTimeoutTime_BSM2" SG_ 299 ACC_Axle_Torque_Enabled 0;
BA_ "GenSigTimeoutTime_ADCAM" SG_ 299 ACC_Axle_Torque_Enabled 0;
BA_ "GenSigTimeoutTime_EPS" SG_ 299 MessageCounter_ADAS_FD_INFO3 0;
BA_ "GenSigTimeoutTime_CVADAS" SG_ 299 MessageCounter_ADAS_FD_INFO3 0;
BA_ "GenSigTimeoutTime_BSM2" SG_ 299 MessageCounter_ADAS_FD_INFO3 0;
BA_ "GenSigTimeoutTime_ADCAM" SG_ 299 MessageCounter_ADAS_FD_INFO3 0;
BA_ "GenSigTimeoutTime_ORC" SG_ 299 CRC_ADAS_FD_INFO3 0;
BA_ "GenSigTimeoutTime_EVCU2" SG_ 299 CRC_ADAS_FD_INFO3 0;
BA_ "GenSigTimeoutTime_EPS" SG_ 299 CRC_ADAS_FD_INFO3 0;
BA_ "GenSigTimeoutTime_CVADAS" SG_ 299 CRC_ADAS_FD_INFO3 0;
BA_ "GenSigTimeoutTime_BSM2" SG_ 299 CRC_ADAS_FD_INFO3 0;
BA_ "GenSigTimeoutTime_ADCAM" SG_ 299 CRC_ADAS_FD_INFO3 0;
BA_ "GenSigTimeoutTime_MPAD" SG_ 280 TorqueOverlaySteeringReq 0;
BA_ "GenSigTimeoutTime_EVCU2" SG_ 280 TorqueOverlaySteeringReq 0;
BA_ "GenSigTimeoutTime_CVADAS" SG_ 280 TorqueOverlaySteeringReq 0;
BA_ "GenSigTimeoutTime_ORC" SG_ 2654486552 CBV_bit7 0;
BA_ "GenSigTimeoutTime_MPAD" SG_ 2654486552 CBV_bit7 0;
BA_ "GenSigTimeoutTime_EVCU2" SG_ 2654486552 CBV_bit7 0;
BA_ "GenSigTimeoutTime_EPS" SG_ 2654486552 CBV_bit7 0;
BA_ "GenSigTimeoutTime_CVADAS" SG_ 2654486552 CBV_bit7 0;
BA_ "GenSigTimeoutTime_BSM2" SG_ 2654486552 CBV_bit7 0;
BA_ "GenSigTimeoutTime_BSM" SG_ 2654486552 CBV_bit7 0;
BA_ "GenSigTimeoutTime_ORC" SG_ 2654486552 SourceNodeIdentifier 0;
BA_ "GenSigTimeoutTime_MPAD" SG_ 2654486552 SourceNodeIdentifier 0;
BA_ "GenSigTimeoutTime_EVCU2" SG_ 2654486552 SourceNodeIdentifier 0;
BA_ "GenSigTimeoutTime_EPS" SG_ 2654486552 SourceNodeIdentifier 0;
BA_ "GenSigTimeoutTime_CVADAS" SG_ 2654486552 SourceNodeIdentifier 0;
BA_ "GenSigTimeoutTime_BSM2" SG_ 2654486552 SourceNodeIdentifier 0;
BA_ "GenSigTimeoutTime_BSM" SG_ 2654486552 SourceNodeIdentifier 0;
BA_ "GenSigTimeoutTime_ADCAM" SG_ 2654486552 SourceNodeIdentifier 0;
BA_ "GenSigTimeoutTime_ORC" SG_ 2654486554 SourceNodeIdentifier 0;
BA_ "GenSigTimeoutTime_MPAD" SG_ 2654486554 SourceNodeIdentifier 0;
BA_ "GenSigTimeoutTime_EVCU2" SG_ 2654486554 SourceNodeIdentifier 0;
BA_ "GenSigTimeoutTime_EPS" SG_ 2654486554 SourceNodeIdentifier 0;
BA_ "GenSigTimeoutTime_CVADAS" SG_ 2654486554 SourceNodeIdentifier 0;
BA_ "GenSigTimeoutTime_BSM2" SG_ 2654486554 SourceNodeIdentifier 0;
BA_ "GenSigTimeoutTime_BSM" SG_ 2654486554 SourceNodeIdentifier 0;
BA_ "GenSigTimeoutTime_ADCAM" SG_ 2654486554 SourceNodeIdentifier 0;
BA_ "GenSigTimeoutTime_ORC" SG_ 2654486701 SourceNodeIdentifier 0;
BA_ "GenSigTimeoutTime_MPAD" SG_ 2654486701 SourceNodeIdentifier 0;
BA_ "GenSigTimeoutTime_EVCU2" SG_ 2654486701 SourceNodeIdentifier 0;
BA_ "GenSigTimeoutTime_EPS" SG_ 2654486701 SourceNodeIdentifier 0;
BA_ "GenSigTimeoutTime_CVADAS" SG_ 2654486701 SourceNodeIdentifier 0;
BA_ "GenSigTimeoutTime_BSM2" SG_ 2654486701 SourceNodeIdentifier 0;
BA_ "GenSigTimeoutTime_BSM" SG_ 2654486701 SourceNodeIdentifier 0;
BA_ "GenSigTimeoutTime_ADCAM" SG_ 2654486701 SourceNodeIdentifier 0;
BA_ "GenSigTimeoutTime_ADCAM" SG_ 2654486552 CBV_bit7 0;
BA_ "GenSigTimeoutTime_ORC" SG_ 2654486554 CBV_bit7 0;
BA_ "GenSigTimeoutTime_MPAD" SG_ 2654486554 CBV_bit7 0;
BA_ "GenSigTimeoutTime_EVCU2" SG_ 2654486554 CBV_bit7 0;
BA_ "GenSigTimeoutTime_EPS" SG_ 2654486554 CBV_bit7 0;
BA_ "GenSigTimeoutTime_CVADAS" SG_ 2654486554 CBV_bit7 0;
BA_ "GenSigTimeoutTime_BSM2" SG_ 2654486554 CBV_bit7 0;
BA_ "GenSigTimeoutTime_BSM" SG_ 2654486554 CBV_bit7 0;
BA_ "GenSigTimeoutTime_ADCAM" SG_ 2654486554 CBV_bit7 0;
BA_ "GenSigTimeoutTime_ORC" SG_ 2654486701 CBV_bit7 0;
BA_ "GenSigTimeoutTime_MPAD" SG_ 2654486701 CBV_bit7 0;
BA_ "GenSigTimeoutTime_EVCU2" SG_ 2654486701 CBV_bit7 0;
BA_ "GenSigTimeoutTime_EPS" SG_ 2654486701 CBV_bit7 0;
BA_ "GenSigTimeoutTime_CVADAS" SG_ 2654486701 CBV_bit7 0;
BA_ "GenSigTimeoutTime_BSM2" SG_ 2654486701 CBV_bit7 0;
BA_ "GenSigTimeoutTime_BSM" SG_ 2654486701 CBV_bit7 0;
BA_ "GenSigTimeoutTime_ADCAM" SG_ 2654486701 CBV_bit7 0;
BA_ "GenSigTimeoutTime_ORC" SG_ 2654486701 CBV_bit6_PartialNtwInfBit 0;
BA_ "GenSigTimeoutTime_MPAD" SG_ 2654486701 CBV_bit6_PartialNtwInfBit 0;
BA_ "GenSigTimeoutTime_EVCU2" SG_ 2654486701 CBV_bit6_PartialNtwInfBit 0;
BA_ "GenSigTimeoutTime_EPS" SG_ 2654486701 CBV_bit6_PartialNtwInfBit 0;
BA_ "GenSigTimeoutTime_CVADAS" SG_ 2654486701 CBV_bit6_PartialNtwInfBit 0;
BA_ "GenSigTimeoutTime_BSM2" SG_ 2654486701 CBV_bit6_PartialNtwInfBit 0;
BA_ "GenSigTimeoutTime_BSM" SG_ 2654486701 CBV_bit6_PartialNtwInfBit 0;
BA_ "GenSigTimeoutTime_ADCAM" SG_ 2654486701 CBV_bit6_PartialNtwInfBit 0;
BA_ "GenSigTimeoutTime_ORC" SG_ 2654486701 CBV_bit0_RepeatMessageRequestBit 0;
BA_ "GenSigTimeoutTime_MPAD" SG_ 2654486701 CBV_bit0_RepeatMessageRequestBit 0;
BA_ "GenSigTimeoutTime_EVCU2" SG_ 2654486701 CBV_bit0_RepeatMessageRequestBit 0;
BA_ "GenSigTimeoutTime_EPS" SG_ 2654486701 CBV_bit0_RepeatMessageRequestBit 0;
BA_ "GenSigTimeoutTime_CVADAS" SG_ 2654486701 CBV_bit0_RepeatMessageRequestBit 0;
BA_ "GenSigTimeoutTime_BSM2" SG_ 2654486701 CBV_bit0_RepeatMessageRequestBit 0;
BA_ "GenSigTimeoutTime_BSM" SG_ 2654486701 CBV_bit0_RepeatMessageRequestBit 0;
BA_ "GenSigTimeoutTime_ADCAM" SG_ 2654486701 CBV_bit0_RepeatMessageRequestBit 0;
BA_ "GenSigTimeoutTime_ORC" SG_ 2654486701 CBV_bit3_NMCoordinatorBit 0;
BA_ "GenSigTimeoutTime_MPAD" SG_ 2654486701 CBV_bit3_NMCoordinatorBit 0;
BA_ "GenSigTimeoutTime_EVCU2" SG_ 2654486701 CBV_bit3_NMCoordinatorBit 0;
BA_ "GenSigTimeoutTime_EPS" SG_ 2654486701 CBV_bit3_NMCoordinatorBit 0;
BA_ "GenSigTimeoutTime_CVADAS" SG_ 2654486701 CBV_bit3_NMCoordinatorBit 0;
BA_ "GenSigTimeoutTime_BSM2" SG_ 2654486701 CBV_bit3_NMCoordinatorBit 0;
BA_ "GenSigTimeoutTime_BSM" SG_ 2654486701 CBV_bit3_NMCoordinatorBit 0;
BA_ "GenSigTimeoutTime_ADCAM" SG_ 2654486701 CBV_bit3_NMCoordinatorBit 0;
BA_ "GenSigTimeoutTime_ORC" SG_ 2654486701 CBV_bit4_ActiveWakeupBit 0;
BA_ "GenSigTimeoutTime_MPAD" SG_ 2654486701 CBV_bit4_ActiveWakeupBit 0;
BA_ "GenSigTimeoutTime_EVCU2" SG_ 2654486701 CBV_bit4_ActiveWakeupBit 0;
BA_ "GenSigTimeoutTime_EPS" SG_ 2654486701 CBV_bit4_ActiveWakeupBit 0;
BA_ "GenSigTimeoutTime_CVADAS" SG_ 2654486701 CBV_bit4_ActiveWakeupBit 0;
BA_ "GenSigTimeoutTime_BSM2" SG_ 2654486701 CBV_bit4_ActiveWakeupBit 0;
BA_ "GenSigTimeoutTime_BSM" SG_ 2654486701 CBV_bit4_ActiveWakeupBit 0;
BA_ "GenSigTimeoutTime_ADCAM" SG_ 2654486701 CBV_bit4_ActiveWakeupBit 0;
BA_ "GenSigTimeoutTime_ORC" SG_ 2654486554 CBV_bit0_RepeatMessageRequestBit 0;
BA_ "GenSigTimeoutTime_MPAD" SG_ 2654486554 CBV_bit0_RepeatMessageRequestBit 0;
BA_ "GenSigTimeoutTime_EVCU2" SG_ 2654486554 CBV_bit0_RepeatMessageRequestBit 0;
BA_ "GenSigTimeoutTime_EPS" SG_ 2654486554 CBV_bit0_RepeatMessageRequestBit 0;
BA_ "GenSigTimeoutTime_CVADAS" SG_ 2654486554 CBV_bit0_RepeatMessageRequestBit 0;
BA_ "GenSigTimeoutTime_BSM2" SG_ 2654486554 CBV_bit0_RepeatMessageRequestBit 0;
BA_ "GenSigTimeoutTime_BSM" SG_ 2654486554 CBV_bit0_RepeatMessageRequestBit 0;
BA_ "GenSigTimeoutTime_ADCAM" SG_ 2654486554 CBV_bit0_RepeatMessageRequestBit 0;
BA_ "GenSigTimeoutTime_ORC" SG_ 2654486552 CBV_bit0_RepeatMessageRequestBit 0;
BA_ "GenSigTimeoutTime_MPAD" SG_ 2654486552 CBV_bit0_RepeatMessageRequestBit 0;
BA_ "GenSigTimeoutTime_EVCU2" SG_ 2654486552 CBV_bit0_RepeatMessageRequestBit 0;
BA_ "GenSigTimeoutTime_EPS" SG_ 2654486552 CBV_bit0_RepeatMessageRequestBit 0;
BA_ "GenSigTimeoutTime_CVADAS" SG_ 2654486552 CBV_bit0_RepeatMessageRequestBit 0;
BA_ "GenSigTimeoutTime_BSM2" SG_ 2654486552 CBV_bit0_RepeatMessageRequestBit 0;
BA_ "GenSigTimeoutTime_BSM" SG_ 2654486552 CBV_bit0_RepeatMessageRequestBit 0;
BA_ "GenSigTimeoutTime_ADCAM" SG_ 2654486552 CBV_bit0_RepeatMessageRequestBit 0;
BA_ "GenSigTimeoutTime_ORC" SG_ 2654486701 CBV_bit1 0;
BA_ "GenSigTimeoutTime_MPAD" SG_ 2654486701 CBV_bit1 0;
BA_ "GenSigTimeoutTime_EVCU2" SG_ 2654486701 CBV_bit1 0;
BA_ "GenSigTimeoutTime_EPS" SG_ 2654486701 CBV_bit1 0;
BA_ "GenSigTimeoutTime_CVADAS" SG_ 2654486701 CBV_bit1 0;
BA_ "GenSigTimeoutTime_BSM2" SG_ 2654486701 CBV_bit1 0;
BA_ "GenSigTimeoutTime_BSM" SG_ 2654486701 CBV_bit1 0;
BA_ "GenSigTimeoutTime_ADCAM" SG_ 2654486701 CBV_bit1 0;
BA_ "GenSigTimeoutTime_ORC" SG_ 2654486552 CBV_bit1 0;
BA_ "GenSigTimeoutTime_MPAD" SG_ 2654486552 CBV_bit1 0;
BA_ "GenSigTimeoutTime_EVCU2" SG_ 2654486552 CBV_bit1 0;
BA_ "GenSigTimeoutTime_EPS" SG_ 2654486552 CBV_bit1 0;
BA_ "GenSigTimeoutTime_CVADAS" SG_ 2654486552 CBV_bit1 0;
BA_ "GenSigTimeoutTime_BSM2" SG_ 2654486552 CBV_bit1 0;
BA_ "GenSigTimeoutTime_BSM" SG_ 2654486552 CBV_bit1 0;
BA_ "GenSigTimeoutTime_ADCAM" SG_ 2654486552 CBV_bit1 0;
BA_ "GenSigTimeoutTime_ORC" SG_ 2654486554 CBV_bit1 0;
BA_ "GenSigTimeoutTime_MPAD" SG_ 2654486554 CBV_bit1 0;
BA_ "GenSigTimeoutTime_EVCU2" SG_ 2654486554 CBV_bit1 0;
BA_ "GenSigTimeoutTime_EPS" SG_ 2654486554 CBV_bit1 0;
BA_ "GenSigTimeoutTime_CVADAS" SG_ 2654486554 CBV_bit1 0;
BA_ "GenSigTimeoutTime_BSM2" SG_ 2654486554 CBV_bit1 0;
BA_ "GenSigTimeoutTime_BSM" SG_ 2654486554 CBV_bit1 0;
BA_ "GenSigTimeoutTime_ADCAM" SG_ 2654486554 CBV_bit1 0;
BA_ "GenSigTimeoutTime_ORC" SG_ 2654486554 CBV_bit2 0;
BA_ "GenSigTimeoutTime_MPAD" SG_ 2654486554 CBV_bit2 0;
BA_ "GenSigTimeoutTime_EVCU2" SG_ 2654486554 CBV_bit2 0;
BA_ "GenSigTimeoutTime_EPS" SG_ 2654486554 CBV_bit2 0;
BA_ "GenSigTimeoutTime_CVADAS" SG_ 2654486554 CBV_bit2 0;
BA_ "GenSigTimeoutTime_BSM2" SG_ 2654486554 CBV_bit2 0;
BA_ "GenSigTimeoutTime_BSM" SG_ 2654486554 CBV_bit2 0;
BA_ "GenSigTimeoutTime_ADCAM" SG_ 2654486554 CBV_bit2 0;
BA_ "GenSigTimeoutTime_ORC" SG_ 2654486701 CBV_bit2 0;
BA_ "GenSigTimeoutTime_MPAD" SG_ 2654486701 CBV_bit2 0;
BA_ "GenSigTimeoutTime_EVCU2" SG_ 2654486701 CBV_bit2 0;
BA_ "GenSigTimeoutTime_EPS" SG_ 2654486701 CBV_bit2 0;
BA_ "GenSigTimeoutTime_CVADAS" SG_ 2654486701 CBV_bit2 0;
BA_ "GenSigTimeoutTime_BSM2" SG_ 2654486701 CBV_bit2 0;
BA_ "GenSigTimeoutTime_BSM" SG_ 2654486701 CBV_bit2 0;
BA_ "GenSigTimeoutTime_ADCAM" SG_ 2654486701 CBV_bit2 0;
BA_ "GenSigTimeoutTime_ORC" SG_ 2654486552 CBV_bit2 0;
BA_ "GenSigTimeoutTime_MPAD" SG_ 2654486552 CBV_bit2 0;
BA_ "GenSigTimeoutTime_EVCU2" SG_ 2654486552 CBV_bit2 0;
BA_ "GenSigTimeoutTime_EPS" SG_ 2654486552 CBV_bit2 0;
BA_ "GenSigTimeoutTime_CVADAS" SG_ 2654486552 CBV_bit2 0;
BA_ "GenSigTimeoutTime_BSM2" SG_ 2654486552 CBV_bit2 0;
BA_ "GenSigTimeoutTime_BSM" SG_ 2654486552 CBV_bit2 0;
BA_ "GenSigTimeoutTime_ADCAM" SG_ 2654486552 CBV_bit2 0;
BA_ "GenSigTimeoutTime_ORC" SG_ 2654486552 CBV_bit3_NMCoordinatorBit 0;
BA_ "GenSigTimeoutTime_MPAD" SG_ 2654486552 CBV_bit3_NMCoordinatorBit 0;
BA_ "GenSigTimeoutTime_EVCU2" SG_ 2654486552 CBV_bit3_NMCoordinatorBit 0;
BA_ "GenSigTimeoutTime_EPS" SG_ 2654486552 CBV_bit3_NMCoordinatorBit 0;
BA_ "GenSigTimeoutTime_CVADAS" SG_ 2654486552 CBV_bit3_NMCoordinatorBit 0;
BA_ "GenSigTimeoutTime_BSM2" SG_ 2654486552 CBV_bit3_NMCoordinatorBit 0;
BA_ "GenSigTimeoutTime_BSM" SG_ 2654486552 CBV_bit3_NMCoordinatorBit 0;
BA_ "GenSigTimeoutTime_ADCAM" SG_ 2654486552 CBV_bit3_NMCoordinatorBit 0;
BA_ "GenSigTimeoutTime_ORC" SG_ 2654486554 CBV_bit3_NMCoordinatorBit 0;
BA_ "GenSigTimeoutTime_MPAD" SG_ 2654486554 CBV_bit3_NMCoordinatorBit 0;
BA_ "GenSigTimeoutTime_EVCU2" SG_ 2654486554 CBV_bit3_NMCoordinatorBit 0;
BA_ "GenSigTimeoutTime_EPS" SG_ 2654486554 CBV_bit3_NMCoordinatorBit 0;
BA_ "GenSigTimeoutTime_CVADAS" SG_ 2654486554 CBV_bit3_NMCoordinatorBit 0;
BA_ "GenSigTimeoutTime_BSM2" SG_ 2654486554 CBV_bit3_NMCoordinatorBit 0;
BA_ "GenSigTimeoutTime_BSM" SG_ 2654486554 CBV_bit3_NMCoordinatorBit 0;
BA_ "GenSigTimeoutTime_ADCAM" SG_ 2654486554 CBV_bit3_NMCoordinatorBit 0;
BA_ "GenSigTimeoutTime_ORC" SG_ 2654486554 CBV_bit4_ActiveWakeupBit 0;
BA_ "GenSigTimeoutTime_MPAD" SG_ 2654486554 CBV_bit4_ActiveWakeupBit 0;
BA_ "GenSigTimeoutTime_EVCU2" SG_ 2654486554 CBV_bit4_ActiveWakeupBit 0;
BA_ "GenSigTimeoutTime_EPS" SG_ 2654486554 CBV_bit4_ActiveWakeupBit 0;
BA_ "GenSigTimeoutTime_CVADAS" SG_ 2654486554 CBV_bit4_ActiveWakeupBit 0;
BA_ "GenSigTimeoutTime_BSM2" SG_ 2654486554 CBV_bit4_ActiveWakeupBit 0;
BA_ "GenSigTimeoutTime_BSM" SG_ 2654486554 CBV_bit4_ActiveWakeupBit 0;
BA_ "GenSigTimeoutTime_ADCAM" SG_ 2654486554 CBV_bit4_ActiveWakeupBit 0;
BA_ "GenSigTimeoutTime_ORC" SG_ 2654486552 CBV_bit4_ActiveWakeupBit 0;
BA_ "GenSigTimeoutTime_MPAD" SG_ 2654486552 CBV_bit4_ActiveWakeupBit 0;
BA_ "GenSigTimeoutTime_EVCU2" SG_ 2654486552 CBV_bit4_ActiveWakeupBit 0;
BA_ "GenSigTimeoutTime_EPS" SG_ 2654486552 CBV_bit4_ActiveWakeupBit 0;
BA_ "GenSigTimeoutTime_CVADAS" SG_ 2654486552 CBV_bit4_ActiveWakeupBit 0;
BA_ "GenSigTimeoutTime_BSM2" SG_ 2654486552 CBV_bit4_ActiveWakeupBit 0;
BA_ "GenSigTimeoutTime_BSM" SG_ 2654486552 CBV_bit4_ActiveWakeupBit 0;
BA_ "GenSigTimeoutTime_ADCAM" SG_ 2654486552 CBV_bit4_ActiveWakeupBit 0;
BA_ "GenSigTimeoutTime_ORC" SG_ 2654486701 CBV_bit5 0;
BA_ "GenSigTimeoutTime_MPAD" SG_ 2654486701 CBV_bit5 0;
BA_ "GenSigTimeoutTime_EVCU2" SG_ 2654486701 CBV_bit5 0;
BA_ "GenSigTimeoutTime_EPS" SG_ 2654486701 CBV_bit5 0;
BA_ "GenSigTimeoutTime_CVADAS" SG_ 2654486701 CBV_bit5 0;
BA_ "GenSigTimeoutTime_BSM2" SG_ 2654486701 CBV_bit5 0;
BA_ "GenSigTimeoutTime_BSM" SG_ 2654486701 CBV_bit5 0;
BA_ "GenSigTimeoutTime_ADCAM" SG_ 2654486701 CBV_bit5 0;
BA_ "GenSigTimeoutTime_ORC" SG_ 2654486552 CBV_bit5 0;
BA_ "GenSigTimeoutTime_MPAD" SG_ 2654486552 CBV_bit5 0;
BA_ "GenSigTimeoutTime_EVCU2" SG_ 2654486552 CBV_bit5 0;
BA_ "GenSigTimeoutTime_EPS" SG_ 2654486552 CBV_bit5 0;
BA_ "GenSigTimeoutTime_CVADAS" SG_ 2654486552 CBV_bit5 0;
BA_ "GenSigTimeoutTime_BSM2" SG_ 2654486552 CBV_bit5 0;
BA_ "GenSigTimeoutTime_BSM" SG_ 2654486552 CBV_bit5 0;
BA_ "GenSigTimeoutTime_ADCAM" SG_ 2654486552 CBV_bit5 0;
BA_ "GenSigTimeoutTime_ORC" SG_ 2654486552 CBV_bit6_PartialNtwInfBit 0;
BA_ "GenSigTimeoutTime_MPAD" SG_ 2654486552 CBV_bit6_PartialNtwInfBit 0;
BA_ "GenSigTimeoutTime_EVCU2" SG_ 2654486552 CBV_bit6_PartialNtwInfBit 0;
BA_ "GenSigTimeoutTime_EPS" SG_ 2654486552 CBV_bit6_PartialNtwInfBit 0;
BA_ "GenSigTimeoutTime_CVADAS" SG_ 2654486552 CBV_bit6_PartialNtwInfBit 0;
BA_ "GenSigTimeoutTime_BSM2" SG_ 2654486552 CBV_bit6_PartialNtwInfBit 0;
BA_ "GenSigTimeoutTime_BSM" SG_ 2654486552 CBV_bit6_PartialNtwInfBit 0;
BA_ "GenSigTimeoutTime_ADCAM" SG_ 2654486552 CBV_bit6_PartialNtwInfBit 0;
BA_ "GenSigTimeoutTime_ORC" SG_ 2654486554 CBV_bit5 0;
BA_ "GenSigTimeoutTime_MPAD" SG_ 2654486554 CBV_bit5 0;
BA_ "GenSigTimeoutTime_EVCU2" SG_ 2654486554 CBV_bit5 0;
BA_ "GenSigTimeoutTime_EPS" SG_ 2654486554 CBV_bit5 0;
BA_ "GenSigTimeoutTime_CVADAS" SG_ 2654486554 CBV_bit5 0;
BA_ "GenSigTimeoutTime_BSM2" SG_ 2654486554 CBV_bit5 0;
BA_ "GenSigTimeoutTime_BSM" SG_ 2654486554 CBV_bit5 0;
BA_ "GenSigTimeoutTime_ADCAM" SG_ 2654486554 CBV_bit5 0;
BA_ "GenSigTimeoutTime_ORC" SG_ 2654486554 CBV_bit6_PartialNtwInfBit 0;
BA_ "GenSigTimeoutTime_MPAD" SG_ 2654486554 CBV_bit6_PartialNtwInfBit 0;
BA_ "GenSigTimeoutTime_EVCU2" SG_ 2654486554 CBV_bit6_PartialNtwInfBit 0;
BA_ "GenSigTimeoutTime_EPS" SG_ 2654486554 CBV_bit6_PartialNtwInfBit 0;
BA_ "GenSigTimeoutTime_CVADAS" SG_ 2654486554 CBV_bit6_PartialNtwInfBit 0;
BA_ "GenSigTimeoutTime_BSM2" SG_ 2654486554 CBV_bit6_PartialNtwInfBit 0;
BA_ "GenSigTimeoutTime_BSM" SG_ 2654486554 CBV_bit6_PartialNtwInfBit 0;
BA_ "GenSigTimeoutTime_ADCAM" SG_ 2654486554 CBV_bit6_PartialNtwInfBit 0;
BA_ "GenSigTimeoutTime_ORC" SG_ 2654486689 CBV_bit5 0;
BA_ "GenSigTimeoutTime_MPAD" SG_ 2654486689 CBV_bit5 0;
BA_ "GenSigTimeoutTime_EVCU2" SG_ 2654486689 CBV_bit5 0;
BA_ "GenSigTimeoutTime_EPS" SG_ 2654486689 CBV_bit5 0;
BA_ "GenSigTimeoutTime_CVADAS" SG_ 2654486689 CBV_bit5 0;
BA_ "GenSigTimeoutTime_BSM2" SG_ 2654486689 CBV_bit5 0;
BA_ "GenSigTimeoutTime_BSM" SG_ 2654486689 CBV_bit5 0;
BA_ "GenSigTimeoutTime_ADCAM" SG_ 2654486689 CBV_bit5 0;
BA_ "GenSigTimeoutTime_ORC" SG_ 2654486534 CBV_bit5 0;
BA_ "GenSigTimeoutTime_MPAD" SG_ 2654486534 CBV_bit5 0;
BA_ "GenSigTimeoutTime_EVCU2" SG_ 2654486534 CBV_bit5 0;
BA_ "GenSigTimeoutTime_EPS" SG_ 2654486534 CBV_bit5 0;
BA_ "GenSigTimeoutTime_CVADAS" SG_ 2654486534 CBV_bit5 0;
BA_ "GenSigTimeoutTime_BSM2" SG_ 2654486534 CBV_bit5 0;
BA_ "GenSigTimeoutTime_BSM" SG_ 2654486534 CBV_bit5 0;
BA_ "GenSigTimeoutTime_ADCAM" SG_ 2654486534 CBV_bit5 0;
BA_ "GenSigTimeoutTime_ORC" SG_ 2654486534 CBV_bit4_ActiveWakeupBit 0;
BA_ "GenSigTimeoutTime_MPAD" SG_ 2654486534 CBV_bit4_ActiveWakeupBit 0;
BA_ "GenSigTimeoutTime_EVCU2" SG_ 2654486534 CBV_bit4_ActiveWakeupBit 0;
BA_ "GenSigTimeoutTime_EPS" SG_ 2654486534 CBV_bit4_ActiveWakeupBit 0;
BA_ "GenSigTimeoutTime_CVADAS" SG_ 2654486534 CBV_bit4_ActiveWakeupBit 0;
BA_ "GenSigTimeoutTime_BSM2" SG_ 2654486534 CBV_bit4_ActiveWakeupBit 0;
BA_ "GenSigTimeoutTime_BSM" SG_ 2654486534 CBV_bit4_ActiveWakeupBit 0;
BA_ "GenSigTimeoutTime_ADCAM" SG_ 2654486534 CBV_bit4_ActiveWakeupBit 0;
BA_ "GenSigTimeoutTime_ORC" SG_ 2654486534 CBV_bit3_NMCoordinatorBit 0;
BA_ "GenSigTimeoutTime_MPAD" SG_ 2654486534 CBV_bit3_NMCoordinatorBit 0;
BA_ "GenSigTimeoutTime_EVCU2" SG_ 2654486534 CBV_bit3_NMCoordinatorBit 0;
BA_ "GenSigTimeoutTime_EPS" SG_ 2654486534 CBV_bit3_NMCoordinatorBit 0;
BA_ "GenSigTimeoutTime_CVADAS" SG_ 2654486534 CBV_bit3_NMCoordinatorBit 0;
BA_ "GenSigTimeoutTime_BSM2" SG_ 2654486534 CBV_bit3_NMCoordinatorBit 0;
BA_ "GenSigTimeoutTime_BSM" SG_ 2654486534 CBV_bit3_NMCoordinatorBit 0;
BA_ "GenSigTimeoutTime_ADCAM" SG_ 2654486534 CBV_bit3_NMCoordinatorBit 0;
BA_ "GenSigTimeoutTime_ORC" SG_ 2654486689 CBV_bit2 0;
BA_ "GenSigTimeoutTime_MPAD" SG_ 2654486689 CBV_bit2 0;
BA_ "GenSigTimeoutTime_EVCU2" SG_ 2654486689 CBV_bit2 0;
BA_ "GenSigTimeoutTime_EPS" SG_ 2654486689 CBV_bit2 0;
BA_ "GenSigTimeoutTime_CVADAS" SG_ 2654486689 CBV_bit2 0;
BA_ "GenSigTimeoutTime_BSM2" SG_ 2654486689 CBV_bit2 0;
BA_ "GenSigTimeoutTime_BSM" SG_ 2654486689 CBV_bit2 0;
BA_ "GenSigTimeoutTime_ADCAM" SG_ 2654486689 CBV_bit2 0;
BA_ "GenSigTimeoutTime_ORC" SG_ 2654486534 CBV_bit2 0;
BA_ "GenSigTimeoutTime_MPAD" SG_ 2654486534 CBV_bit2 0;
BA_ "GenSigTimeoutTime_EVCU2" SG_ 2654486534 CBV_bit2 0;
BA_ "GenSigTimeoutTime_EPS" SG_ 2654486534 CBV_bit2 0;
BA_ "GenSigTimeoutTime_CVADAS" SG_ 2654486534 CBV_bit2 0;
BA_ "GenSigTimeoutTime_BSM2" SG_ 2654486534 CBV_bit2 0;
BA_ "GenSigTimeoutTime_BSM" SG_ 2654486534 CBV_bit2 0;
BA_ "GenSigTimeoutTime_ADCAM" SG_ 2654486534 CBV_bit2 0;
BA_ "GenSigTimeoutTime_ORC" SG_ 2654486689 CBV_bit1 0;
BA_ "GenSigTimeoutTime_MPAD" SG_ 2654486689 CBV_bit1 0;
BA_ "GenSigTimeoutTime_EVCU2" SG_ 2654486689 CBV_bit1 0;
BA_ "GenSigTimeoutTime_EPS" SG_ 2654486689 CBV_bit1 0;
BA_ "GenSigTimeoutTime_CVADAS" SG_ 2654486689 CBV_bit1 0;
BA_ "GenSigTimeoutTime_BSM2" SG_ 2654486689 CBV_bit1 0;
BA_ "GenSigTimeoutTime_BSM" SG_ 2654486689 CBV_bit1 0;
BA_ "GenSigTimeoutTime_ADCAM" SG_ 2654486689 CBV_bit1 0;
BA_ "GenSigTimeoutTime_ORC" SG_ 2654486534 CBV_bit1 0;
BA_ "GenSigTimeoutTime_MPAD" SG_ 2654486534 CBV_bit1 0;
BA_ "GenSigTimeoutTime_EVCU2" SG_ 2654486534 CBV_bit1 0;
BA_ "GenSigTimeoutTime_EPS" SG_ 2654486534 CBV_bit1 0;
BA_ "GenSigTimeoutTime_CVADAS" SG_ 2654486534 CBV_bit1 0;
BA_ "GenSigTimeoutTime_BSM2" SG_ 2654486534 CBV_bit1 0;
BA_ "GenSigTimeoutTime_BSM" SG_ 2654486534 CBV_bit1 0;
BA_ "GenSigTimeoutTime_ADCAM" SG_ 2654486534 CBV_bit1 0;
BA_ "GenSigTimeoutTime_ORC" SG_ 2654486534 CBV_bit0_RepeatMessageRequestBit 0;
BA_ "GenSigTimeoutTime_MPAD" SG_ 2654486534 CBV_bit0_RepeatMessageRequestBit 0;
BA_ "GenSigTimeoutTime_EVCU2" SG_ 2654486534 CBV_bit0_RepeatMessageRequestBit 0;
BA_ "GenSigTimeoutTime_EPS" SG_ 2654486534 CBV_bit0_RepeatMessageRequestBit 0;
BA_ "GenSigTimeoutTime_CVADAS" SG_ 2654486534 CBV_bit0_RepeatMessageRequestBit 0;
BA_ "GenSigTimeoutTime_BSM2" SG_ 2654486534 CBV_bit0_RepeatMessageRequestBit 0;
BA_ "GenSigTimeoutTime_BSM" SG_ 2654486534 CBV_bit0_RepeatMessageRequestBit 0;
BA_ "GenSigTimeoutTime_ADCAM" SG_ 2654486534 CBV_bit0_RepeatMessageRequestBit 0;
BA_ "GenSigTimeoutTime_ORC" SG_ 2654486689 CBV_bit4_ActiveWakeupBit 0;
BA_ "GenSigTimeoutTime_MPAD" SG_ 2654486689 CBV_bit4_ActiveWakeupBit 0;
BA_ "GenSigTimeoutTime_EVCU2" SG_ 2654486689 CBV_bit4_ActiveWakeupBit 0;
BA_ "GenSigTimeoutTime_EPS" SG_ 2654486689 CBV_bit4_ActiveWakeupBit 0;
BA_ "GenSigTimeoutTime_CVADAS" SG_ 2654486689 CBV_bit4_ActiveWakeupBit 0;
BA_ "GenSigTimeoutTime_BSM2" SG_ 2654486689 CBV_bit4_ActiveWakeupBit 0;
BA_ "GenSigTimeoutTime_BSM" SG_ 2654486689 CBV_bit4_ActiveWakeupBit 0;
BA_ "GenSigTimeoutTime_ADCAM" SG_ 2654486689 CBV_bit4_ActiveWakeupBit 0;
BA_ "GenSigTimeoutTime_ORC" SG_ 2654486689 CBV_bit6_PartialNtwInfBit 0;
BA_ "GenSigTimeoutTime_MPAD" SG_ 2654486689 CBV_bit6_PartialNtwInfBit 0;
BA_ "GenSigTimeoutTime_EVCU2" SG_ 2654486689 CBV_bit6_PartialNtwInfBit 0;
BA_ "GenSigTimeoutTime_EPS" SG_ 2654486689 CBV_bit6_PartialNtwInfBit 0;
BA_ "GenSigTimeoutTime_CVADAS" SG_ 2654486689 CBV_bit6_PartialNtwInfBit 0;
BA_ "GenSigTimeoutTime_BSM2" SG_ 2654486689 CBV_bit6_PartialNtwInfBit 0;
BA_ "GenSigTimeoutTime_BSM" SG_ 2654486689 CBV_bit6_PartialNtwInfBit 0;
BA_ "GenSigTimeoutTime_ADCAM" SG_ 2654486689 CBV_bit6_PartialNtwInfBit 0;
BA_ "GenSigTimeoutTime_ORC" SG_ 2654486689 CBV_bit3_NMCoordinatorBit 0;
BA_ "GenSigTimeoutTime_MPAD" SG_ 2654486689 CBV_bit3_NMCoordinatorBit 0;
BA_ "GenSigTimeoutTime_EVCU2" SG_ 2654486689 CBV_bit3_NMCoordinatorBit 0;
BA_ "GenSigTimeoutTime_EPS" SG_ 2654486689 CBV_bit3_NMCoordinatorBit 0;
BA_ "GenSigTimeoutTime_CVADAS" SG_ 2654486689 CBV_bit3_NMCoordinatorBit 0;
BA_ "GenSigTimeoutTime_BSM2" SG_ 2654486689 CBV_bit3_NMCoordinatorBit 0;
BA_ "GenSigTimeoutTime_BSM" SG_ 2654486689 CBV_bit3_NMCoordinatorBit 0;
BA_ "GenSigTimeoutTime_ADCAM" SG_ 2654486689 CBV_bit3_NMCoordinatorBit 0;
BA_ "GenSigTimeoutTime_ORC" SG_ 2654486689 CBV_bit0_RepeatMessageRequestBit 0;
BA_ "GenSigTimeoutTime_MPAD" SG_ 2654486689 CBV_bit0_RepeatMessageRequestBit 0;
BA_ "GenSigTimeoutTime_EVCU2" SG_ 2654486689 CBV_bit0_RepeatMessageRequestBit 0;
BA_ "GenSigTimeoutTime_EPS" SG_ 2654486689 CBV_bit0_RepeatMessageRequestBit 0;
BA_ "GenSigTimeoutTime_CVADAS" SG_ 2654486689 CBV_bit0_RepeatMessageRequestBit 0;
BA_ "GenSigTimeoutTime_BSM2" SG_ 2654486689 CBV_bit0_RepeatMessageRequestBit 0;
BA_ "GenSigTimeoutTime_BSM" SG_ 2654486689 CBV_bit0_RepeatMessageRequestBit 0;
BA_ "GenSigTimeoutTime_ADCAM" SG_ 2654486689 CBV_bit0_RepeatMessageRequestBit 0;
BA_ "GenSigTimeoutTime_ORC" SG_ 2654486534 CBV_bit6_PartialNtwInfBit 0;
BA_ "GenSigTimeoutTime_MPAD" SG_ 2654486534 CBV_bit6_PartialNtwInfBit 0;
BA_ "GenSigTimeoutTime_EVCU2" SG_ 2654486534 CBV_bit6_PartialNtwInfBit 0;
BA_ "GenSigTimeoutTime_EPS" SG_ 2654486534 CBV_bit6_PartialNtwInfBit 0;
BA_ "GenSigTimeoutTime_CVADAS" SG_ 2654486534 CBV_bit6_PartialNtwInfBit 0;
BA_ "GenSigTimeoutTime_BSM2" SG_ 2654486534 CBV_bit6_PartialNtwInfBit 0;
BA_ "GenSigTimeoutTime_BSM" SG_ 2654486534 CBV_bit6_PartialNtwInfBit 0;
BA_ "GenSigTimeoutTime_ADCAM" SG_ 2654486534 CBV_bit6_PartialNtwInfBit 0;
BA_ "GenSigTimeoutTime_ORC" SG_ 2654486689 CBV_bit7 0;
BA_ "GenSigTimeoutTime_MPAD" SG_ 2654486689 CBV_bit7 0;
BA_ "GenSigTimeoutTime_EVCU2" SG_ 2654486689 CBV_bit7 0;
BA_ "GenSigTimeoutTime_EPS" SG_ 2654486689 CBV_bit7 0;
BA_ "GenSigTimeoutTime_CVADAS" SG_ 2654486689 CBV_bit7 0;
BA_ "GenSigTimeoutTime_BSM2" SG_ 2654486689 CBV_bit7 0;
BA_ "GenSigTimeoutTime_BSM" SG_ 2654486689 CBV_bit7 0;
BA_ "GenSigTimeoutTime_ADCAM" SG_ 2654486689 CBV_bit7 0;
BA_ "GenSigTimeoutTime_BSM2" SG_ 2654486534 CBV_bit7 0;
BA_ "GenSigTimeoutTime_BSM" SG_ 2654486534 CBV_bit7 0;
BA_ "GenSigTimeoutTime_ADCAM" SG_ 2654486534 CBV_bit7 0;
BA_ "GenSigTimeoutTime_ORC" SG_ 2654486689 SourceNodeIdentifier 0;
BA_ "GenSigTimeoutTime_MPAD" SG_ 2654486689 SourceNodeIdentifier 0;
BA_ "GenSigTimeoutTime_EVCU2" SG_ 2654486689 SourceNodeIdentifier 0;
BA_ "GenSigTimeoutTime_EPS" SG_ 2654486689 SourceNodeIdentifier 0;
BA_ "GenSigTimeoutTime_CVADAS" SG_ 2654486689 SourceNodeIdentifier 0;
BA_ "GenSigTimeoutTime_BSM2" SG_ 2654486689 SourceNodeIdentifier 0;
BA_ "GenSigTimeoutTime_BSM" SG_ 2654486689 SourceNodeIdentifier 0;
BA_ "GenSigTimeoutTime_ADCAM" SG_ 2654486689 SourceNodeIdentifier 0;
BA_ "GenSigTimeoutTime_ORC" SG_ 524 BSM2_HEALTH_CHECK 0;
BA_ "GenSigTimeoutTime_MPAD" SG_ 524 BSM2_HEALTH_CHECK 0;
BA_ "GenSigTimeoutTime_EVCU2" SG_ 524 BSM2_HEALTH_CHECK 0;
BA_ "GenSigTimeoutTime_EPS" SG_ 524 BSM2_HEALTH_CHECK 0;
BA_ "GenSigTimeoutTime_CVADAS" SG_ 524 BSM2_HEALTH_CHECK 0;
BA_ "GenSigTimeoutTime_BSM2" SG_ 524 BSM2_HEALTH_CHECK 0;
BA_ "GenSigTimeoutTime_ADCAM" SG_ 524 BSM2_HEALTH_CHECK 0;
BA_ "GenSigTimeoutTime_ORC" SG_ 524 AEB_Type_Brk_B2 0;
BA_ "GenSigTimeoutTime_EVCU2" SG_ 524 AEB_Type_Brk_B2 0;
BA_ "GenSigTimeoutTime_EPS" SG_ 524 AEB_Type_Brk_B2 0;
BA_ "GenSigTimeoutTime_CVADAS" SG_ 524 AEB_Type_Brk_B2 0;
BA_ "GenSigTimeoutTime_BSM2" SG_ 524 AEB_Type_Brk_B2 0;
BA_ "GenSigTimeoutTime_BSM" SG_ 524 AEB_Type_Brk_B2 0;
BA_ "GenSigTimeoutTime_ADCAM" SG_ 524 AEB_Type_Brk_B2 0;
BA_ "GenSigTimeoutTime_ORC" SG_ 727 MessageCounter_CVPAM_FD_Data2 0;
BA_ "GenSigTimeoutTime_EVCU2" SG_ 727 MessageCounter_CVPAM_FD_Data2 0;
BA_ "GenSigTimeoutTime_EPS" SG_ 727 MessageCounter_CVPAM_FD_Data2 0;
BA_ "GenSigTimeoutTime_CVADAS" SG_ 727 MessageCounter_CVPAM_FD_Data2 0;
BA_ "GenSigTimeoutTime_BSM2" SG_ 727 MessageCounter_CVPAM_FD_Data2 0;
BA_ "GenSigTimeoutTime_BSM" SG_ 727 MessageCounter_CVPAM_FD_Data2 0;
BA_ "GenSigTimeoutTime_ADCAM" SG_ 727 MessageCounter_CVPAM_FD_Data2 0;
BA_ "GenSigStartValue" SG_ 524 BrkTrq_B2 32767;
BA_ "GenSigTimeoutTime_ORC" SG_ 524 BrkTrq_B2 0;
BA_ "GenSigTimeoutTime_EVCU2" SG_ 524 BrkTrq_B2 0;
BA_ "GenSigTimeoutTime_EPS" SG_ 524 BrkTrq_B2 0;
BA_ "GenSigTimeoutTime_CVADAS" SG_ 524 BrkTrq_B2 0;
BA_ "GenSigTimeoutTime_BSM2" SG_ 524 BrkTrq_B2 0;
BA_ "GenSigTimeoutTime_BSM" SG_ 524 BrkTrq_B2 0;
BA_ "GenSigTimeoutTime_ADCAM" SG_ 524 BrkTrq_B2 0;
BA_ "GenSigTimeoutTime_EVCU2" SG_ 524 CRC_BRAKE2_2 0;
BA_ "GenSigTimeoutTime_EPS" SG_ 524 CRC_BRAKE2_2 0;
BA_ "GenSigTimeoutTime_CVADAS" SG_ 524 CRC_BRAKE2_2 0;
BA_ "GenSigTimeoutTime_BSM2" SG_ 524 CRC_BRAKE2_2 0;
BA_ "GenSigTimeoutTime_ADCAM" SG_ 524 CRC_BRAKE2_2 0;
BA_ "GenSigTimeoutTime_EVCU2" SG_ 524 MessageCounter_BRAKE2_2 0;
BA_ "GenSigTimeoutTime_EPS" SG_ 524 MessageCounter_BRAKE2_2 0;
BA_ "GenSigTimeoutTime_CVADAS" SG_ 524 MessageCounter_BRAKE2_2 0;
BA_ "GenSigTimeoutTime_BSM2" SG_ 524 MessageCounter_BRAKE2_2 0;
BA_ "GenSigTimeoutTime_ADCAM" SG_ 524 MessageCounter_BRAKE2_2 0;
BA_ "GenSigTimeoutTime_ORC" SG_ 1156 ABSFailSts_B2 0;
BA_ "GenSigTimeoutTime_EVCU2" SG_ 1156 ABSFailSts_B2 0;
BA_ "GenSigTimeoutTime_EPS" SG_ 1156 ABSFailSts_B2 0;
BA_ "GenSigTimeoutTime_CVADAS" SG_ 1156 ABSFailSts_B2 0;
BA_ "GenSigTimeoutTime_BSM2" SG_ 1156 ABSFailSts_B2 0;
BA_ "GenSigTimeoutTime_BSM" SG_ 1156 ABSFailSts_B2 0;
BA_ "GenSigTimeoutTime_ADCAM" SG_ 1156 ABSFailSts_B2 0;
BA_ "GenSigSendType" SG_ 1156 ABSFailSts_B2 4;
BA_ "GenSigTimeoutTime_MPAD" SG_ 1156 CRC_BRAKE2_3 0;
BA_ "GenSigTimeoutTime_EVCU2" SG_ 1156 CRC_BRAKE2_3 0;
BA_ "GenSigTimeoutTime_EPS" SG_ 1156 CRC_BRAKE2_3 0;
BA_ "GenSigTimeoutTime_CVADAS" SG_ 1156 CRC_BRAKE2_3 0;
BA_ "GenSigTimeoutTime_BSM2" SG_ 1156 CRC_BRAKE2_3 0;
BA_ "GenSigTimeoutTime_BSM" SG_ 1156 CRC_BRAKE2_3 0;
BA_ "GenSigTimeoutTime_ADCAM" SG_ 1156 CRC_BRAKE2_3 0;
BA_ "GenSigTimeoutTime_MPAD" SG_ 1156 MessageCounter_BRAKE2_3 0;
BA_ "GenSigTimeoutTime_EVCU2" SG_ 1156 MessageCounter_BRAKE2_3 0;
BA_ "GenSigTimeoutTime_EPS" SG_ 1156 MessageCounter_BRAKE2_3 0;
BA_ "GenSigTimeoutTime_CVADAS" SG_ 1156 MessageCounter_BRAKE2_3 0;
BA_ "GenSigTimeoutTime_BSM2" SG_ 1156 MessageCounter_BRAKE2_3 0;
BA_ "GenSigTimeoutTime_BSM" SG_ 1156 MessageCounter_BRAKE2_3 0;
BA_ "GenSigTimeoutTime_ADCAM" SG_ 1156 MessageCounter_BRAKE2_3 0;
BA_ "GenSigTimeoutTime_ORC" SG_ 1156 RollsModeAct_B2 0;
BA_ "GenSigTimeoutTime_EVCU2" SG_ 1156 RollsModeAct_B2 0;
BA_ "GenSigTimeoutTime_EPS" SG_ 1156 RollsModeAct_B2 0;
BA_ "GenSigTimeoutTime_CVADAS" SG_ 1156 RollsModeAct_B2 0;
BA_ "GenSigTimeoutTime_BSM2" SG_ 1156 RollsModeAct_B2 0;
BA_ "GenSigTimeoutTime_BSM" SG_ 1156 RollsModeAct_B2 0;
BA_ "GenSigTimeoutTime_ADCAM" SG_ 1156 RollsModeAct_B2 0;
BA_ "GenSigSendType" SG_ 1156 RollsModeAct_B2 4;
BA_ "GenSigTimeoutTime_ORC" SG_ 726 CRC_CVPAM_FD_Data 0;
BA_ "GenSigTimeoutTime_EVCU2" SG_ 726 CRC_CVPAM_FD_Data 0;
BA_ "GenSigTimeoutTime_EPS" SG_ 726 CRC_CVPAM_FD_Data 0;
BA_ "GenSigTimeoutTime_CVADAS" SG_ 726 CRC_CVPAM_FD_Data 0;
BA_ "GenSigTimeoutTime_BSM2" SG_ 726 CRC_CVPAM_FD_Data 0;
BA_ "GenSigTimeoutTime_BSM" SG_ 726 CRC_CVPAM_FD_Data 0;
BA_ "GenSigTimeoutTime_ADCAM" SG_ 726 CRC_CVPAM_FD_Data 0;
BA_ "GenSigTimeoutTime_ORC" SG_ 726 MessageCounter_CVPAM_FD_Data 0;
BA_ "GenSigTimeoutTime_EVCU2" SG_ 726 MessageCounter_CVPAM_FD_Data 0;
BA_ "GenSigTimeoutTime_EPS" SG_ 726 MessageCounter_CVPAM_FD_Data 0;
BA_ "GenSigTimeoutTime_CVADAS" SG_ 726 MessageCounter_CVPAM_FD_Data 0;
BA_ "GenSigTimeoutTime_BSM2" SG_ 726 MessageCounter_CVPAM_FD_Data 0;
BA_ "GenSigTimeoutTime_BSM" SG_ 726 MessageCounter_CVPAM_FD_Data 0;
BA_ "GenSigTimeoutTime_ADCAM" SG_ 726 MessageCounter_CVPAM_FD_Data 0;
BA_ "GenSigTimeoutTime_ORC" SG_ 727 CRC_CVPAM_FD_Data2 0;
BA_ "GenSigTimeoutTime_EVCU2" SG_ 727 CRC_CVPAM_FD_Data2 0;
BA_ "GenSigTimeoutTime_EPS" SG_ 727 CRC_CVPAM_FD_Data2 0;
BA_ "GenSigTimeoutTime_CVADAS" SG_ 727 CRC_CVPAM_FD_Data2 0;
BA_ "GenSigTimeoutTime_BSM2" SG_ 727 CRC_CVPAM_FD_Data2 0;
BA_ "GenSigTimeoutTime_BSM" SG_ 727 CRC_CVPAM_FD_Data2 0;
BA_ "GenSigTimeoutTime_ADCAM" SG_ 727 CRC_CVPAM_FD_Data2 0;
BA_ "GenSigTimeoutTime_ORC" SG_ 524 VehicleStandStillSts_B2 0;
BA_ "GenSigTimeoutTime_EVCU2" SG_ 524 VehicleStandStillSts_B2 0;
BA_ "GenSigTimeoutTime_EPS" SG_ 524 VehicleStandStillSts_B2 0;
BA_ "GenSigTimeoutTime_CVADAS" SG_ 524 VehicleStandStillSts_B2 0;
BA_ "GenSigTimeoutTime_BSM2" SG_ 524 VehicleStandStillSts_B2 0;
BA_ "GenSigTimeoutTime_ADCAM" SG_ 524 VehicleStandStillSts_B2 0;
BA_ "GenSigStartValue" SG_ 524 VehicleStandStillSts_B2 1;
BA_ "GenSigTimeoutTime_ORC" SG_ 524 Brake_OpStat_Sec 0;
BA_ "GenSigTimeoutTime_EVCU2" SG_ 524 Brake_OpStat_Sec 0;
BA_ "GenSigTimeoutTime_EPS" SG_ 524 Brake_OpStat_Sec 0;
BA_ "GenSigTimeoutTime_CVADAS" SG_ 524 Brake_OpStat_Sec 0;
BA_ "GenSigTimeoutTime_BSM2" SG_ 524 Brake_OpStat_Sec 0;
BA_ "GenSigTimeoutTime_BSM" SG_ 524 Brake_OpStat_Sec 0;
BA_ "GenSigTimeoutTime_ADCAM" SG_ 524 Brake_OpStat_Sec 0;
BA_ "GenSigTimeoutTime_ORC" SG_ 524 BSM2_OpStat 0;
BA_ "GenSigTimeoutTime_EVCU2" SG_ 524 BSM2_OpStat 0;
BA_ "GenSigTimeoutTime_EPS" SG_ 524 BSM2_OpStat 0;
BA_ "GenSigTimeoutTime_CVADAS" SG_ 524 BSM2_OpStat 0;
BA_ "GenSigTimeoutTime_BSM2" SG_ 524 BSM2_OpStat 0;
BA_ "GenSigTimeoutTime_ADCAM" SG_ 524 BSM2_OpStat 0;
BA_ "GenSigTimeoutTime_ORC" SG_ 257 RHFWheelSpeed_B2 0;
BA_ "GenSigTimeoutTime_EVCU2" SG_ 257 RHFWheelSpeed_B2 0;
BA_ "GenSigTimeoutTime_EPS" SG_ 257 RHFWheelSpeed_B2 0;
BA_ "GenSigTimeoutTime_CVADAS" SG_ 257 RHFWheelSpeed_B2 0;
BA_ "GenSigTimeoutTime_BSM2" SG_ 257 RHFWheelSpeed_B2 0;
BA_ "GenSigTimeoutTime_BSM" SG_ 257 RHFWheelSpeed_B2 0;
BA_ "GenSigTimeoutTime_ADCAM" SG_ 257 RHFWheelSpeed_B2 0;
BA_ "GenSigTimeoutTime_ORC" SG_ 257 VehicleSpeedVSOSig_B2 0;
BA_ "GenSigTimeoutTime_EVCU2" SG_ 257 VehicleSpeedVSOSig_B2 0;
BA_ "GenSigTimeoutTime_CVADAS" SG_ 257 VehicleSpeedVSOSig_B2 0;
BA_ "GenSigTimeoutTime_BSM2" SG_ 257 VehicleSpeedVSOSig_B2 0;
BA_ "GenSigTimeoutTime_BSM" SG_ 257 VehicleSpeedVSOSig_B2 0;
BA_ "GenSigTimeoutTime_ADCAM" SG_ 257 VehicleSpeedVSOSig_B2 0;
BA_ "GenSigTimeoutTime_ORC" SG_ 257 LHFWheelSpeed_B2 0;
BA_ "GenSigTimeoutTime_EVCU2" SG_ 257 LHFWheelSpeed_B2 0;
BA_ "GenSigTimeoutTime_EPS" SG_ 257 LHFWheelSpeed_B2 0;
BA_ "GenSigTimeoutTime_CVADAS" SG_ 257 LHFWheelSpeed_B2 0;
BA_ "GenSigTimeoutTime_BSM2" SG_ 257 LHFWheelSpeed_B2 0;
BA_ "GenSigTimeoutTime_BSM" SG_ 257 LHFWheelSpeed_B2 0;
BA_ "GenSigTimeoutTime_ADCAM" SG_ 257 LHFWheelSpeed_B2 0;
BA_ "GenSigTimeoutTime_ORC" SG_ 257 RHF_FastPulseCounter_B2 0;
BA_ "GenSigTimeoutTime_EVCU2" SG_ 257 RHF_FastPulseCounter_B2 0;
BA_ "GenSigTimeoutTime_EPS" SG_ 257 RHF_FastPulseCounter_B2 0;
BA_ "GenSigTimeoutTime_CVADAS" SG_ 257 RHF_FastPulseCounter_B2 0;
BA_ "GenSigTimeoutTime_BSM2" SG_ 257 RHF_FastPulseCounter_B2 0;
BA_ "GenSigTimeoutTime_BSM" SG_ 257 RHF_FastPulseCounter_B2 0;
BA_ "GenSigTimeoutTime_ADCAM" SG_ 257 RHF_FastPulseCounter_B2 0;
BA_ "GenSigTimeoutTime_ORC" SG_ 257 ABSActive_B2 0;
BA_ "GenSigTimeoutTime_EVCU2" SG_ 257 ABSActive_B2 0;
BA_ "GenSigTimeoutTime_EPS" SG_ 257 ABSActive_B2 0;
BA_ "GenSigTimeoutTime_CVADAS" SG_ 257 ABSActive_B2 0;
BA_ "GenSigTimeoutTime_BSM2" SG_ 257 ABSActive_B2 0;
BA_ "GenSigTimeoutTime_BSM" SG_ 257 ABSActive_B2 0;
BA_ "GenSigTimeoutTime_ADCAM" SG_ 257 ABSActive_B2 0;
BA_ "GenSigTimeoutTime_ORC" SG_ 257 Brk_Stat_B2 0;
BA_ "GenSigTimeoutTime_EVCU2" SG_ 257 Brk_Stat_B2 0;
BA_ "GenSigTimeoutTime_EPS" SG_ 257 Brk_Stat_B2 0;
BA_ "GenSigTimeoutTime_CVADAS" SG_ 257 Brk_Stat_B2 0;
BA_ "GenSigTimeoutTime_BSM2" SG_ 257 Brk_Stat_B2 0;
BA_ "GenSigTimeoutTime_BSM" SG_ 257 Brk_Stat_B2 0;
BA_ "GenSigTimeoutTime_ADCAM" SG_ 257 Brk_Stat_B2 0;
BA_ "GenSigTimeoutTime_EVCU2" SG_ 257 CRC_BRAKE2_1 0;
BA_ "GenSigTimeoutTime_CVADAS" SG_ 257 CRC_BRAKE2_1 0;
BA_ "GenSigTimeoutTime_BSM2" SG_ 257 CRC_BRAKE2_1 0;
BA_ "GenSigTimeoutTime_BSM" SG_ 257 CRC_BRAKE2_1 0;
BA_ "GenSigTimeoutTime_ADCAM" SG_ 257 CRC_BRAKE2_1 0;
BA_ "GenSigTimeoutTime_ORC" SG_ 257 RHF_Spin_B2 0;
BA_ "GenSigTimeoutTime_EVCU2" SG_ 257 RHF_Spin_B2 0;
BA_ "GenSigTimeoutTime_EPS" SG_ 257 RHF_Spin_B2 0;
BA_ "GenSigTimeoutTime_CVADAS" SG_ 257 RHF_Spin_B2 0;
BA_ "GenSigTimeoutTime_BSM2" SG_ 257 RHF_Spin_B2 0;
BA_ "GenSigTimeoutTime_BSM" SG_ 257 RHF_Spin_B2 0;
BA_ "GenSigTimeoutTime_ADCAM" SG_ 257 RHF_Spin_B2 0;
BA_ "GenSigTimeoutTime_ORC" SG_ 257 RHF_WheelSensorFailSts_B2 0;
BA_ "GenSigTimeoutTime_EVCU2" SG_ 257 RHF_WheelSensorFailSts_B2 0;
BA_ "GenSigTimeoutTime_EPS" SG_ 257 RHF_WheelSensorFailSts_B2 0;
BA_ "GenSigTimeoutTime_CVADAS" SG_ 257 RHF_WheelSensorFailSts_B2 0;
BA_ "GenSigTimeoutTime_BSM2" SG_ 257 RHF_WheelSensorFailSts_B2 0;
BA_ "GenSigTimeoutTime_BSM" SG_ 257 RHF_WheelSensorFailSts_B2 0;
BA_ "GenSigTimeoutTime_ADCAM" SG_ 257 RHF_WheelSensorFailSts_B2 0;
BA_ "GenSigTimeoutTime_ORC" SG_ 257 Inlet_Pressure_Pos 0;
BA_ "GenSigTimeoutTime_EVCU2" SG_ 257 Inlet_Pressure_Pos 0;
BA_ "GenSigTimeoutTime_EPS" SG_ 257 Inlet_Pressure_Pos 0;
BA_ "GenSigTimeoutTime_CVADAS" SG_ 257 Inlet_Pressure_Pos 0;
BA_ "GenSigTimeoutTime_BSM2" SG_ 257 Inlet_Pressure_Pos 0;
BA_ "GenSigTimeoutTime_BSM" SG_ 257 Inlet_Pressure_Pos 0;
BA_ "GenSigTimeoutTime_ADCAM" SG_ 257 Inlet_Pressure_Pos 0;
BA_ "GenSigTimeoutTime_ORC" SG_ 257 LHF_Spin_B2 0;
BA_ "GenSigTimeoutTime_EVCU2" SG_ 257 LHF_Spin_B2 0;
BA_ "GenSigTimeoutTime_EPS" SG_ 257 LHF_Spin_B2 0;
BA_ "GenSigTimeoutTime_CVADAS" SG_ 257 LHF_Spin_B2 0;
BA_ "GenSigTimeoutTime_BSM2" SG_ 257 LHF_Spin_B2 0;
BA_ "GenSigTimeoutTime_BSM" SG_ 257 LHF_Spin_B2 0;
BA_ "GenSigTimeoutTime_ADCAM" SG_ 257 LHF_Spin_B2 0;
BA_ "GenSigTimeoutTime_ORC" SG_ 257 LHF_WheelSensorFailSts_B2 0;
BA_ "GenSigTimeoutTime_EVCU2" SG_ 257 LHF_WheelSensorFailSts_B2 0;
BA_ "GenSigTimeoutTime_EPS" SG_ 257 LHF_WheelSensorFailSts_B2 0;
BA_ "GenSigTimeoutTime_CVADAS" SG_ 257 LHF_WheelSensorFailSts_B2 0;
BA_ "GenSigTimeoutTime_BSM2" SG_ 257 LHF_WheelSensorFailSts_B2 0;
BA_ "GenSigTimeoutTime_BSM" SG_ 257 LHF_WheelSensorFailSts_B2 0;
BA_ "GenSigTimeoutTime_ADCAM" SG_ 257 LHF_WheelSensorFailSts_B2 0;
BA_ "GenSigTimeoutTime_EVCU2" SG_ 257 MessageCounter_BRAKE2_1 0;
BA_ "GenSigTimeoutTime_CVADAS" SG_ 257 MessageCounter_BRAKE2_1 0;
BA_ "GenSigTimeoutTime_BSM2" SG_ 257 MessageCounter_BRAKE2_1 0;
BA_ "GenSigTimeoutTime_BSM" SG_ 257 MessageCounter_BRAKE2_1 0;
BA_ "GenSigTimeoutTime_ADCAM" SG_ 257 MessageCounter_BRAKE2_1 0;
BA_ "GenSigTimeoutTime_ORC" SG_ 257 LHF_FastPulseCounter_B2 0;
BA_ "GenSigTimeoutTime_EVCU2" SG_ 257 LHF_FastPulseCounter_B2 0;
BA_ "GenSigTimeoutTime_EPS" SG_ 257 LHF_FastPulseCounter_B2 0;
BA_ "GenSigTimeoutTime_CVADAS" SG_ 257 LHF_FastPulseCounter_B2 0;
BA_ "GenSigTimeoutTime_BSM2" SG_ 257 LHF_FastPulseCounter_B2 0;
BA_ "GenSigTimeoutTime_BSM" SG_ 257 LHF_FastPulseCounter_B2 0;
BA_ "GenSigTimeoutTime_ADCAM" SG_ 257 LHF_FastPulseCounter_B2 0;
BA_ "GenSigTimeoutTime_ORC" SG_ 257 Ft_RrTrqCoupling_ModeRq_B2 0;
BA_ "GenSigTimeoutTime_MPAD" SG_ 257 Ft_RrTrqCoupling_ModeRq_B2 0;
BA_ "GenSigTimeoutTime_EVCU2" SG_ 257 Ft_RrTrqCoupling_ModeRq_B2 0;
BA_ "GenSigTimeoutTime_EPS" SG_ 257 Ft_RrTrqCoupling_ModeRq_B2 0;
BA_ "GenSigTimeoutTime_CVADAS" SG_ 257 Ft_RrTrqCoupling_ModeRq_B2 0;
BA_ "GenSigTimeoutTime_BSM2" SG_ 257 Ft_RrTrqCoupling_ModeRq_B2 0;
BA_ "GenSigTimeoutTime_BSM" SG_ 257 Ft_RrTrqCoupling_ModeRq_B2 0;
BA_ "GenSigTimeoutTime_ADCAM" SG_ 257 Ft_RrTrqCoupling_ModeRq_B2 0;
BA_ "GenSigTimeoutTime_ORC" SG_ 257 Ft_RrAxleCoupling_TrqRq_B2 0;
BA_ "GenSigTimeoutTime_MPAD" SG_ 257 Ft_RrAxleCoupling_TrqRq_B2 0;
BA_ "GenSigTimeoutTime_EVCU2" SG_ 257 Ft_RrAxleCoupling_TrqRq_B2 0;
BA_ "GenSigTimeoutTime_EPS" SG_ 257 Ft_RrAxleCoupling_TrqRq_B2 0;
BA_ "GenSigTimeoutTime_CVADAS" SG_ 257 Ft_RrAxleCoupling_TrqRq_B2 0;
BA_ "GenSigTimeoutTime_BSM2" SG_ 257 Ft_RrAxleCoupling_TrqRq_B2 0;
BA_ "GenSigTimeoutTime_BSM" SG_ 257 Ft_RrAxleCoupling_TrqRq_B2 0;
BA_ "GenSigTimeoutTime_ADCAM" SG_ 257 Ft_RrAxleCoupling_TrqRq_B2 0;
BA_ "GenSigStartValue" SG_ 257 Ft_RrAxleCoupling_TrqRq_B2 254;
BA_ "GenSigTimeoutTime_ORC" SG_ 205 CRC_BRAKE_FD_6 0;
BA_ "GenSigTimeoutTime_MPAD" SG_ 205 CRC_BRAKE_FD_6 0;
BA_ "GenSigTimeoutTime_EPS" SG_ 205 CRC_BRAKE_FD_6 0;
BA_ "GenSigTimeoutTime_CVADAS" SG_ 205 CRC_BRAKE_FD_6 0;
BA_ "GenSigTimeoutTime_BSM2" SG_ 205 CRC_BRAKE_FD_6 0;
BA_ "GenSigTimeoutTime_BSM" SG_ 205 CRC_BRAKE_FD_6 0;
BA_ "GenSigTimeoutTime_ADCAM" SG_ 205 CRC_BRAKE_FD_6 0;
BA_ "GenSigTimeoutTime_ORC" SG_ 205 RearAxle_Min_Rq_BSM 0;
BA_ "GenSigTimeoutTime_MPAD" SG_ 205 RearAxle_Min_Rq_BSM 0;
BA_ "GenSigTimeoutTime_EPS" SG_ 205 RearAxle_Min_Rq_BSM 0;
BA_ "GenSigTimeoutTime_CVADAS" SG_ 205 RearAxle_Min_Rq_BSM 0;
BA_ "GenSigTimeoutTime_BSM2" SG_ 205 RearAxle_Min_Rq_BSM 0;
BA_ "GenSigTimeoutTime_BSM" SG_ 205 RearAxle_Min_Rq_BSM 0;
BA_ "GenSigTimeoutTime_ADCAM" SG_ 205 RearAxle_Min_Rq_BSM 0;
BA_ "GenSigTimeoutTime_ORC" SG_ 205 MessageCounter_BRAKE_FD_6 0;
BA_ "GenSigTimeoutTime_MPAD" SG_ 205 MessageCounter_BRAKE_FD_6 0;
BA_ "GenSigTimeoutTime_EPS" SG_ 205 MessageCounter_BRAKE_FD_6 0;
BA_ "GenSigTimeoutTime_CVADAS" SG_ 205 MessageCounter_BRAKE_FD_6 0;
BA_ "GenSigTimeoutTime_BSM2" SG_ 205 MessageCounter_BRAKE_FD_6 0;
BA_ "GenSigTimeoutTime_BSM" SG_ 205 MessageCounter_BRAKE_FD_6 0;
BA_ "GenSigTimeoutTime_ADCAM" SG_ 205 MessageCounter_BRAKE_FD_6 0;
BA_ "GenSigTimeoutTime_ORC" SG_ 205 TotalAxle_Min_Rq_BSM 0;
BA_ "GenSigTimeoutTime_MPAD" SG_ 205 TotalAxle_Min_Rq_BSM 0;
BA_ "GenSigTimeoutTime_EPS" SG_ 205 TotalAxle_Min_Rq_BSM 0;
BA_ "GenSigTimeoutTime_CVADAS" SG_ 205 TotalAxle_Min_Rq_BSM 0;
BA_ "GenSigTimeoutTime_BSM2" SG_ 205 TotalAxle_Min_Rq_BSM 0;
BA_ "GenSigTimeoutTime_BSM" SG_ 205 TotalAxle_Min_Rq_BSM 0;
BA_ "GenSigTimeoutTime_ADCAM" SG_ 205 TotalAxle_Min_Rq_BSM 0;
BA_ "GenSigTimeoutTime_ORC" SG_ 205 FrontAxle_Max_Rq_BSM 0;
BA_ "GenSigTimeoutTime_MPAD" SG_ 205 FrontAxle_Max_Rq_BSM 0;
BA_ "GenSigTimeoutTime_EPS" SG_ 205 FrontAxle_Max_Rq_BSM 0;
BA_ "GenSigTimeoutTime_CVADAS" SG_ 205 FrontAxle_Max_Rq_BSM 0;
BA_ "GenSigTimeoutTime_BSM2" SG_ 205 FrontAxle_Max_Rq_BSM 0;
BA_ "GenSigTimeoutTime_BSM" SG_ 205 FrontAxle_Max_Rq_BSM 0;
BA_ "GenSigTimeoutTime_ADCAM" SG_ 205 FrontAxle_Max_Rq_BSM 0;
BA_ "GenSigTimeoutTime_ORC" SG_ 205 FrontAxle_Min_Rq_BSM 0;
BA_ "GenSigTimeoutTime_MPAD" SG_ 205 FrontAxle_Min_Rq_BSM 0;
BA_ "GenSigTimeoutTime_EPS" SG_ 205 FrontAxle_Min_Rq_BSM 0;
BA_ "GenSigTimeoutTime_CVADAS" SG_ 205 FrontAxle_Min_Rq_BSM 0;
BA_ "GenSigTimeoutTime_BSM2" SG_ 205 FrontAxle_Min_Rq_BSM 0;
BA_ "GenSigTimeoutTime_BSM" SG_ 205 FrontAxle_Min_Rq_BSM 0;
BA_ "GenSigTimeoutTime_ADCAM" SG_ 205 FrontAxle_Min_Rq_BSM 0;
BA_ "GenSigTimeoutTime_ORC" SG_ 205 RearAxle_Max_Rq_BSM 0;
BA_ "GenSigTimeoutTime_MPAD" SG_ 205 RearAxle_Max_Rq_BSM 0;
BA_ "GenSigTimeoutTime_EPS" SG_ 205 RearAxle_Max_Rq_BSM 0;
BA_ "GenSigTimeoutTime_CVADAS" SG_ 205 RearAxle_Max_Rq_BSM 0;
BA_ "GenSigTimeoutTime_BSM2" SG_ 205 RearAxle_Max_Rq_BSM 0;
BA_ "GenSigTimeoutTime_BSM" SG_ 205 RearAxle_Max_Rq_BSM 0;
BA_ "GenSigTimeoutTime_ADCAM" SG_ 205 RearAxle_Max_Rq_BSM 0;
BA_ "GenSigTimeoutTime_CVADAS" SG_ 205 Cmnd_TotBrkFrict_AxleTorq 0;
BA_ "GenSigTimeoutTime_BSM2" SG_ 205 Cmnd_TotBrkFrict_AxleTorq 0;
BA_ "GenSigTimeoutTime_BSM" SG_ 205 Cmnd_TotBrkFrict_AxleTorq 0;
BA_ "GenSigTimeoutTime_ADCAM" SG_ 205 Cmnd_TotBrkFrict_AxleTorq 0;
BA_ "GenSigTimeoutTime_ORC" SG_ 205 Cmnd_TotBrkFrict_AxleTorq 0;
BA_ "GenSigTimeoutTime_MPAD" SG_ 205 Cmnd_TotBrkFrict_AxleTorq 0;
BA_ "GenSigTimeoutTime_EPS" SG_ 205 Cmnd_TotBrkFrict_AxleTorq 0;
BA_ "GenSigTimeoutTime_ORC" SG_ 205 DriverReq_AxleTrq_Enabled_BSM 0;
BA_ "GenSigTimeoutTime_MPAD" SG_ 205 DriverReq_AxleTrq_Enabled_BSM 0;
BA_ "GenSigTimeoutTime_EPS" SG_ 205 DriverReq_AxleTrq_Enabled_BSM 0;
BA_ "GenSigTimeoutTime_BSM2" SG_ 205 DriverReq_AxleTrq_Enabled_BSM 0;
BA_ "GenSigTimeoutTime_BSM" SG_ 205 DriverReq_AxleTrq_Enabled_BSM 0;
BA_ "GenSigTimeoutTime_ADCAM" SG_ 205 DriverReq_AxleTrq_Enabled_BSM 0;
BA_ "GenSigTimeoutTime_ORC" SG_ 205 DrvrIntd_TotalBrk_AxleTorq 0;
BA_ "GenSigTimeoutTime_MPAD" SG_ 205 DrvrIntd_TotalBrk_AxleTorq 0;
BA_ "GenSigTimeoutTime_EPS" SG_ 205 DrvrIntd_TotalBrk_AxleTorq 0;
BA_ "GenSigTimeoutTime_CVADAS" SG_ 205 DrvrIntd_TotalBrk_AxleTorq 0;
BA_ "GenSigTimeoutTime_BSM2" SG_ 205 DrvrIntd_TotalBrk_AxleTorq 0;
BA_ "GenSigTimeoutTime_BSM" SG_ 205 DrvrIntd_TotalBrk_AxleTorq 0;
BA_ "GenSigTimeoutTime_ADCAM" SG_ 205 DrvrIntd_TotalBrk_AxleTorq 0;
BA_ "GenSigTimeoutTime_ORC" SG_ 205 TotalAxle_Max_Rq_BSM 0;
BA_ "GenSigTimeoutTime_MPAD" SG_ 205 TotalAxle_Max_Rq_BSM 0;
BA_ "GenSigTimeoutTime_EPS" SG_ 205 TotalAxle_Max_Rq_BSM 0;
BA_ "GenSigTimeoutTime_CVADAS" SG_ 205 TotalAxle_Max_Rq_BSM 0;
BA_ "GenSigTimeoutTime_BSM2" SG_ 205 TotalAxle_Max_Rq_BSM 0;
BA_ "GenSigTimeoutTime_BSM" SG_ 205 TotalAxle_Max_Rq_BSM 0;
BA_ "GenSigTimeoutTime_ADCAM" SG_ 205 TotalAxle_Max_Rq_BSM 0;
BA_ "GenSigTimeoutTime_ORC" SG_ 205 DriverRequested_AxleTrq_BSM 0;
BA_ "GenSigTimeoutTime_MPAD" SG_ 205 DriverRequested_AxleTrq_BSM 0;
BA_ "GenSigTimeoutTime_EPS" SG_ 205 DriverRequested_AxleTrq_BSM 0;
BA_ "GenSigTimeoutTime_CVADAS" SG_ 205 DriverRequested_AxleTrq_BSM 0;
BA_ "GenSigTimeoutTime_BSM2" SG_ 205 DriverRequested_AxleTrq_BSM 0;
BA_ "GenSigTimeoutTime_BSM" SG_ 205 DriverRequested_AxleTrq_BSM 0;
BA_ "GenSigTimeoutTime_ADCAM" SG_ 205 DriverRequested_AxleTrq_BSM 0;
BA_ "GenSigStartValue" SG_ 205 DriverRequested_AxleTrq_BSM 32767;
BA_ "GenSigTimeoutTime_ORC" SG_ 205 TotalAxle_Rq_BSM 0;
BA_ "GenSigTimeoutTime_MPAD" SG_ 205 TotalAxle_Rq_BSM 0;
BA_ "GenSigTimeoutTime_EPS" SG_ 205 TotalAxle_Rq_BSM 0;
BA_ "GenSigTimeoutTime_CVADAS" SG_ 205 TotalAxle_Rq_BSM 0;
BA_ "GenSigTimeoutTime_BSM2" SG_ 205 TotalAxle_Rq_BSM 0;
BA_ "GenSigTimeoutTime_BSM" SG_ 205 TotalAxle_Rq_BSM 0;
BA_ "GenSigTimeoutTime_ADCAM" SG_ 205 TotalAxle_Rq_BSM 0;
BA_ "GenSigStartValue" SG_ 205 TotalAxle_Rq_BSM 32767;
BA_ "GenSigTimeoutTime_ORC" SG_ 205 FrontAxle_Rq_BSM 0;
BA_ "GenSigTimeoutTime_MPAD" SG_ 205 FrontAxle_Rq_BSM 0;
BA_ "GenSigTimeoutTime_EPS" SG_ 205 FrontAxle_Rq_BSM 0;
BA_ "GenSigTimeoutTime_CVADAS" SG_ 205 FrontAxle_Rq_BSM 0;
BA_ "GenSigTimeoutTime_BSM2" SG_ 205 FrontAxle_Rq_BSM 0;
BA_ "GenSigTimeoutTime_BSM" SG_ 205 FrontAxle_Rq_BSM 0;
BA_ "GenSigTimeoutTime_ADCAM" SG_ 205 FrontAxle_Rq_BSM 0;
BA_ "GenSigStartValue" SG_ 205 FrontAxle_Rq_BSM 32767;
BA_ "GenSigTimeoutTime_ORC" SG_ 205 RearAxle_Rq_BSM 0;
BA_ "GenSigTimeoutTime_MPAD" SG_ 205 RearAxle_Rq_BSM 0;
BA_ "GenSigTimeoutTime_EPS" SG_ 205 RearAxle_Rq_BSM 0;
BA_ "GenSigTimeoutTime_CVADAS" SG_ 205 RearAxle_Rq_BSM 0;
BA_ "GenSigTimeoutTime_BSM2" SG_ 205 RearAxle_Rq_BSM 0;
BA_ "GenSigTimeoutTime_BSM" SG_ 205 RearAxle_Rq_BSM 0;
BA_ "GenSigTimeoutTime_ADCAM" SG_ 205 RearAxle_Rq_BSM 0;
BA_ "GenSigStartValue" SG_ 205 RearAxle_Rq_BSM 32767;
BA_ "GenSigTimeoutTime_ORC" SG_ 258 ParkingInterventionSts 0;
BA_ "GenSigTimeoutTime_MPAD" SG_ 258 ParkingInterventionSts 0;
BA_ "GenSigTimeoutTime_EVCU2" SG_ 258 ParkingInterventionSts 0;
BA_ "GenSigTimeoutTime_EPS" SG_ 258 ParkingInterventionSts 0;
BA_ "GenSigTimeoutTime_BSM2" SG_ 258 ParkingInterventionSts 0;
BA_ "GenSigTimeoutTime_BSM" SG_ 258 ParkingInterventionSts 0;
BA_ "GenSigTimeoutTime_ADCAM" SG_ 258 ParkingInterventionSts 0;
BA_ "GenSigTimeoutTime_ORC" SG_ 258 ParkingGearShiftReq_BSM 0;
BA_ "GenSigTimeoutTime_MPAD" SG_ 258 ParkingGearShiftReq_BSM 0;
BA_ "GenSigTimeoutTime_EVCU2" SG_ 258 ParkingGearShiftReq_BSM 0;
BA_ "GenSigTimeoutTime_EPS" SG_ 258 ParkingGearShiftReq_BSM 0;
BA_ "GenSigTimeoutTime_BSM2" SG_ 258 ParkingGearShiftReq_BSM 0;
BA_ "GenSigTimeoutTime_BSM" SG_ 258 ParkingGearShiftReq_BSM 0;
BA_ "GenSigTimeoutTime_ADCAM" SG_ 258 ParkingGearShiftReq_BSM 0;
BA_ "GenSigTimeoutTime_ORC" SG_ 258 Brk_Stat 0;
BA_ "GenSigTimeoutTime_EPS" SG_ 258 Brk_Stat 0;
BA_ "GenSigTimeoutTime_BSM2" SG_ 258 Brk_Stat 0;
BA_ "GenSigTimeoutTime_BSM" SG_ 258 Brk_Stat 0;
BA_ "GenSigTimeoutTime_ORC" SG_ 258 WheelRPM_FL 0;
BA_ "GenSigTimeoutTime_EVCU2" SG_ 258 WheelRPM_FL 0;
BA_ "GenSigTimeoutTime_CVADAS" SG_ 258 WheelRPM_FL 0;
BA_ "GenSigTimeoutTime_BSM2" SG_ 258 WheelRPM_FL 0;
BA_ "GenSigTimeoutTime_BSM" SG_ 258 WheelRPM_FL 0;
BA_ "GenSigTimeoutTime_ADCAM" SG_ 258 WheelRPM_FL 0;
BA_ "GenSigStartValue" SG_ 258 WheelRPM_FL 65535;
BA_ "GenSigTimeoutTime_ORC" SG_ 258 WheelRPM_FR 0;
BA_ "GenSigTimeoutTime_EVCU2" SG_ 258 WheelRPM_FR 0;
BA_ "GenSigTimeoutTime_CVADAS" SG_ 258 WheelRPM_FR 0;
BA_ "GenSigTimeoutTime_BSM2" SG_ 258 WheelRPM_FR 0;
BA_ "GenSigTimeoutTime_BSM" SG_ 258 WheelRPM_FR 0;
BA_ "GenSigTimeoutTime_ADCAM" SG_ 258 WheelRPM_FR 0;
BA_ "GenSigStartValue" SG_ 258 WheelRPM_FR 65535;
BA_ "GenSigTimeoutTime_ORC" SG_ 258 CRC_BRAKE2 0;
BA_ "GenSigTimeoutTime_BSM" SG_ 258 CRC_BRAKE2 0;
BA_ "GenSigTimeoutTime_ORC" SG_ 258 ABSActive 0;
BA_ "GenSigTimeoutTime_EPS" SG_ 258 ABSActive 0;
BA_ "GenSigTimeoutTime_CVADAS" SG_ 258 ABSActive 0;
BA_ "GenSigTimeoutTime_BSM2" SG_ 258 ABSActive 0;
BA_ "GenSigTimeoutTime_BSM" SG_ 258 ABSActive 0;
BA_ "GenSigTimeoutTime_ADCAM" SG_ 258 ABSActive 0;
BA_ "GenSigTimeoutTime_ORC" SG_ 258 BrakeBoostPressure 0;
BA_ "GenSigTimeoutTime_MPAD" SG_ 258 BrakeBoostPressure 0;
BA_ "GenSigTimeoutTime_EPS" SG_ 258 BrakeBoostPressure 0;
BA_ "GenSigTimeoutTime_CVADAS" SG_ 258 BrakeBoostPressure 0;
BA_ "GenSigTimeoutTime_BSM2" SG_ 258 BrakeBoostPressure 0;
BA_ "GenSigTimeoutTime_BSM" SG_ 258 BrakeBoostPressure 0;
BA_ "GenSigTimeoutTime_ADCAM" SG_ 258 BrakeBoostPressure 0;
BA_ "GenSigStartValue" SG_ 258 BrakeBoostPressure 2047;
BA_ "GenSigTimeoutTime_ORC" SG_ 258 BrakeBoostStat 0;
BA_ "GenSigTimeoutTime_MPAD" SG_ 258 BrakeBoostStat 0;
BA_ "GenSigTimeoutTime_EVCU2" SG_ 258 BrakeBoostStat 0;
BA_ "GenSigTimeoutTime_EPS" SG_ 258 BrakeBoostStat 0;
BA_ "GenSigTimeoutTime_CVADAS" SG_ 258 BrakeBoostStat 0;
BA_ "GenSigTimeoutTime_BSM2" SG_ 258 BrakeBoostStat 0;
BA_ "GenSigTimeoutTime_BSM" SG_ 258 BrakeBoostStat 0;
BA_ "GenSigTimeoutTime_ADCAM" SG_ 258 BrakeBoostStat 0;
BA_ "GenSigTimeoutTime_ORC" SG_ 258 BrakeInterventionSts 0;
BA_ "GenSigTimeoutTime_EVCU2" SG_ 258 BrakeInterventionSts 0;
BA_ "GenSigTimeoutTime_EPS" SG_ 258 BrakeInterventionSts 0;
BA_ "GenSigTimeoutTime_CVADAS" SG_ 258 BrakeInterventionSts 0;
BA_ "GenSigTimeoutTime_BSM" SG_ 258 BrakeInterventionSts 0;
BA_ "GenSigTimeoutTime_ORC" SG_ 258 BrakePedalPressure 0;
BA_ "GenSigTimeoutTime_MPAD" SG_ 258 BrakePedalPressure 0;
BA_ "GenSigTimeoutTime_EPS" SG_ 258 BrakePedalPressure 0;
BA_ "GenSigTimeoutTime_CVADAS" SG_ 258 BrakePedalPressure 0;
BA_ "GenSigTimeoutTime_BSM2" SG_ 258 BrakePedalPressure 0;
BA_ "GenSigTimeoutTime_BSM" SG_ 258 BrakePedalPressure 0;
BA_ "GenSigTimeoutTime_ADCAM" SG_ 258 BrakePedalPressure 0;
BA_ "GenSigStartValue" SG_ 258 BrakePedalPressure 2047;
BA_ "GenSigTimeoutTime_ORC" SG_ 258 ESCActive 0;
BA_ "GenSigTimeoutTime_EPS" SG_ 258 ESCActive 0;
BA_ "GenSigTimeoutTime_CVADAS" SG_ 258 ESCActive 0;
BA_ "GenSigTimeoutTime_BSM2" SG_ 258 ESCActive 0;
BA_ "GenSigTimeoutTime_BSM" SG_ 258 ESCActive 0;
BA_ "GenSigTimeoutTime_ADCAM" SG_ 258 ESCActive 0;
BA_ "GenSigTimeoutTime_ORC" SG_ 258 ESP_Sys_Stat 0;
BA_ "GenSigTimeoutTime_MPAD" SG_ 258 ESP_Sys_Stat 0;
BA_ "GenSigTimeoutTime_EVCU2" SG_ 258 ESP_Sys_Stat 0;
BA_ "GenSigTimeoutTime_EPS" SG_ 258 ESP_Sys_Stat 0;
BA_ "GenSigTimeoutTime_CVADAS" SG_ 258 ESP_Sys_Stat 0;
BA_ "GenSigTimeoutTime_BSM2" SG_ 258 ESP_Sys_Stat 0;
BA_ "GenSigTimeoutTime_BSM" SG_ 258 ESP_Sys_Stat 0;
BA_ "GenSigTimeoutTime_ADCAM" SG_ 258 ESP_Sys_Stat 0;
BA_ "GenSigStartValue" SG_ 258 ESP_Sys_Stat 1;
BA_ "GenSigTimeoutTime_ORC" SG_ 258 InternalError_BSM 0;
BA_ "GenSigTimeoutTime_EVCU2" SG_ 258 InternalError_BSM 0;
BA_ "GenSigTimeoutTime_EPS" SG_ 258 InternalError_BSM 0;
BA_ "GenSigTimeoutTime_CVADAS" SG_ 258 InternalError_BSM 0;
BA_ "GenSigTimeoutTime_BSM2" SG_ 258 InternalError_BSM 0;
BA_ "GenSigTimeoutTime_BSM" SG_ 258 InternalError_BSM 0;
BA_ "GenSigTimeoutTime_ORC" SG_ 258 LatAcceleration_BSM 0;
BA_ "GenSigTimeoutTime_EVCU2" SG_ 258 LatAcceleration_BSM 0;
BA_ "GenSigTimeoutTime_BSM2" SG_ 258 LatAcceleration_BSM 0;
BA_ "GenSigTimeoutTime_BSM" SG_ 258 LatAcceleration_BSM 0;
BA_ "GenSigStartValue" SG_ 258 LatAcceleration_BSM 4095;
BA_ "GenSigTimeoutTime_ORC" SG_ 258 LatAccelerationFailSts_BSM 0;
BA_ "GenSigTimeoutTime_EVCU2" SG_ 258 LatAccelerationFailSts_BSM 0;
BA_ "GenSigTimeoutTime_EPS" SG_ 258 LatAccelerationFailSts_BSM 0;
BA_ "GenSigTimeoutTime_BSM2" SG_ 258 LatAccelerationFailSts_BSM 0;
BA_ "GenSigTimeoutTime_BSM" SG_ 258 LatAccelerationFailSts_BSM 0;
BA_ "GenSigTimeoutTime_ORC" SG_ 258 LongAcceleration_BSM 0;
BA_ "GenSigTimeoutTime_EVCU2" SG_ 258 LongAcceleration_BSM 0;
BA_ "GenSigTimeoutTime_BSM2" SG_ 258 LongAcceleration_BSM 0;
BA_ "GenSigTimeoutTime_BSM" SG_ 258 LongAcceleration_BSM 0;
BA_ "GenSigStartValue" SG_ 258 LongAcceleration_BSM 4095;
BA_ "GenSigTimeoutTime_ORC" SG_ 258 LongAccelerationFailSts_BSM 0;
BA_ "GenSigTimeoutTime_EVCU2" SG_ 258 LongAccelerationFailSts_BSM 0;
BA_ "GenSigTimeoutTime_EPS" SG_ 258 LongAccelerationFailSts_BSM 0;
BA_ "GenSigTimeoutTime_BSM2" SG_ 258 LongAccelerationFailSts_BSM 0;
BA_ "GenSigTimeoutTime_BSM" SG_ 258 LongAccelerationFailSts_BSM 0;
BA_ "GenSigTimeoutTime_ORC" SG_ 258 MessageCounter_BRAKE2 0;
BA_ "GenSigTimeoutTime_BSM" SG_ 258 MessageCounter_BRAKE2 0;
BA_ "GenSigTimeoutTime_ORC" SG_ 258 VehicleSpeedVSOSig 0;
BA_ "GenSigTimeoutTime_BSM" SG_ 258 VehicleSpeedVSOSig 0;
BA_ "GenSigTimeoutTime_ORC" SG_ 258 PrefillActive 0;
BA_ "GenSigTimeoutTime_EVCU2" SG_ 258 PrefillActive 0;
BA_ "GenSigTimeoutTime_EPS" SG_ 258 PrefillActive 0;
BA_ "GenSigTimeoutTime_CVADAS" SG_ 258 PrefillActive 0;
BA_ "GenSigTimeoutTime_BSM2" SG_ 258 PrefillActive 0;
BA_ "GenSigTimeoutTime_BSM" SG_ 258 PrefillActive 0;
BA_ "GenSigTimeoutTime_ORC" SG_ 258 Slope 0;
BA_ "GenSigTimeoutTime_EVCU2" SG_ 258 Slope 0;
BA_ "GenSigTimeoutTime_EPS" SG_ 258 Slope 0;
BA_ "GenSigTimeoutTime_BSM2" SG_ 258 Slope 0;
BA_ "GenSigTimeoutTime_BSM" SG_ 258 Slope 0;
BA_ "GenSigTimeoutTime_ADCAM" SG_ 258 Slope 0;
BA_ "GenSigTimeoutTime_ORC" SG_ 258 YawRate_BSM 0;
BA_ "GenSigTimeoutTime_EVCU2" SG_ 258 YawRate_BSM 0;
BA_ "GenSigTimeoutTime_BSM2" SG_ 258 YawRate_BSM 0;
BA_ "GenSigTimeoutTime_BSM" SG_ 258 YawRate_BSM 0;
BA_ "GenSigStartValue" SG_ 258 YawRate_BSM 4095;
BA_ "GenSigTimeoutTime_ORC" SG_ 258 YawRateFailSts_BSM 0;
BA_ "GenSigTimeoutTime_EVCU2" SG_ 258 YawRateFailSts_BSM 0;
BA_ "GenSigTimeoutTime_BSM2" SG_ 258 YawRateFailSts_BSM 0;
BA_ "GenSigTimeoutTime_BSM" SG_ 258 YawRateFailSts_BSM 0;
BA_ "GenSigTimeoutTime_BSM2" SG_ 280 TorqueOverlaySteeringReq 0;
BA_ "GenSigTimeoutTime_BSM" SG_ 280 TorqueOverlaySteeringReq 0;
BA_ "GenSigTimeoutTime_ADCAM" SG_ 280 TorqueOverlaySteeringReq 0;
BA_ "GenSigStartValue" SG_ 280 TorqueOverlaySteeringReq 1024;
BA_ "GenSigTimeoutTime_ORC" SG_ 299 ACC_Axle_Torque 0;
BA_ "GenSigTimeoutTime_MPAD" SG_ 299 ACC_Axle_Torque 0;
BA_ "GenSigTimeoutTime_EVCU2" SG_ 299 ACC_Axle_Torque 0;
BA_ "GenSigTimeoutTime_EPS" SG_ 299 ACC_Axle_Torque 0;
BA_ "GenSigTimeoutTime_CVADAS" SG_ 299 ACC_Axle_Torque 0;
BA_ "GenSigTimeoutTime_BSM2" SG_ 299 ACC_Axle_Torque 0;
BA_ "GenSigTimeoutTime_ADCAM" SG_ 299 ACC_Axle_Torque 0;
BA_ "GenSigStartValue" SG_ 299 ACC_Axle_Torque 32768;
BA_ "GenSigTimeoutTime_ORC" SG_ 280 Prefill_Req 0;
BA_ "GenSigTimeoutTime_ORC" SG_ 280 SteeringVibration_Type 0;
BA_ "GenSigTimeoutTime_MPAD" SG_ 280 SteeringVibration_Type 0;
BA_ "GenSigTimeoutTime_EVCU2" SG_ 280 SteeringVibration_Type 0;
BA_ "GenSigTimeoutTime_CVADAS" SG_ 280 SteeringVibration_Type 0;
BA_ "GenSigTimeoutTime_BSM2" SG_ 280 SteeringVibration_Type 0;
BA_ "GenSigTimeoutTime_BSM" SG_ 280 SteeringVibration_Type 0;
BA_ "GenSigTimeoutTime_ADCAM" SG_ 280 SteeringVibration_Type 0;
BA_ "GenSigTimeoutTime_ORC" SG_ 280 SteeringVibration_Rq 0;
BA_ "GenSigTimeoutTime_MPAD" SG_ 280 SteeringVibration_Rq 0;
BA_ "GenSigTimeoutTime_EVCU2" SG_ 280 SteeringVibration_Rq 0;
BA_ "GenSigTimeoutTime_CVADAS" SG_ 280 SteeringVibration_Rq 0;
BA_ "GenSigTimeoutTime_BSM2" SG_ 280 SteeringVibration_Rq 0;
BA_ "GenSigTimeoutTime_BSM" SG_ 280 SteeringVibration_Rq 0;
BA_ "GenSigTimeoutTime_ADCAM" SG_ 280 SteeringVibration_Rq 0;
BA_ "GenSigTimeoutTime_ORC" SG_ 299 ACC_TORSts 0;
BA_ "GenSigTimeoutTime_MPAD" SG_ 299 ACC_TORSts 0;
BA_ "GenSigTimeoutTime_EVCU2" SG_ 299 ACC_TORSts 0;
BA_ "GenSigTimeoutTime_EPS" SG_ 299 ACC_TORSts 0;
BA_ "GenSigTimeoutTime_CVADAS" SG_ 299 ACC_TORSts 0;
BA_ "GenSigTimeoutTime_BSM2" SG_ 299 ACC_TORSts 0;
BA_ "GenSigTimeoutTime_BSM" SG_ 299 ACC_TORSts 0;
BA_ "GenSigTimeoutTime_ORC" SG_ 280 LKA_LAT_CTRL_RequestSts 0;
BA_ "GenSigTimeoutTime_MPAD" SG_ 280 LKA_LAT_CTRL_RequestSts 0;
BA_ "GenSigTimeoutTime_EVCU2" SG_ 280 LKA_LAT_CTRL_RequestSts 0;
BA_ "GenSigTimeoutTime_CVADAS" SG_ 280 LKA_LAT_CTRL_RequestSts 0;
BA_ "GenSigTimeoutTime_BSM2" SG_ 280 LKA_LAT_CTRL_RequestSts 0;
BA_ "GenSigTimeoutTime_BSM" SG_ 280 LKA_LAT_CTRL_RequestSts 0;
BA_ "GenSigTimeoutTime_ADCAM" SG_ 280 LKA_LAT_CTRL_RequestSts 0;
BA_ "GenSigTimeoutTime_MPAD" SG_ 280 LANE_CHANGE_STATUS 0;
BA_ "GenSigTimeoutTime_EVCU2" SG_ 280 LANE_CHANGE_STATUS 0;
BA_ "GenSigTimeoutTime_EPS" SG_ 280 LANE_CHANGE_STATUS 0;
BA_ "GenSigTimeoutTime_CVADAS" SG_ 280 LANE_CHANGE_STATUS 0;
BA_ "GenSigTimeoutTime_BSM2" SG_ 280 LANE_CHANGE_STATUS 0;
BA_ "GenSigTimeoutTime_BSM" SG_ 280 LANE_CHANGE_STATUS 0;
BA_ "GenSigTimeoutTime_MPAD" SG_ 280 Prefill_Req 0;
BA_ "GenSigTimeoutTime_EVCU2" SG_ 280 Prefill_Req 0;
BA_ "GenSigTimeoutTime_EPS" SG_ 280 Prefill_Req 0;
BA_ "GenSigTimeoutTime_CVADAS" SG_ 280 Prefill_Req 0;
BA_ "GenSigTimeoutTime_BSM2" SG_ 280 Prefill_Req 0;
BA_ "GenSigTimeoutTime_ADCAM" SG_ 280 Prefill_Req 0;
BA_ "GenSigTimeoutTime_MPAD" SG_ 280 DDD_SystemSts 0;
BA_ "GenSigTimeoutTime_EVCU2" SG_ 280 DDD_SystemSts 0;
BA_ "GenSigTimeoutTime_EPS" SG_ 280 DDD_SystemSts 0;
BA_ "GenSigTimeoutTime_CVADAS" SG_ 280 DDD_SystemSts 0;
BA_ "GenSigTimeoutTime_BSM2" SG_ 280 DDD_SystemSts 0;
BA_ "GenSigTimeoutTime_BSM" SG_ 280 DDD_SystemSts 0;
BA_ "GenSigTimeoutTime_ADCAM" SG_ 280 DDD_SystemSts 0;
BA_ "GenSigTimeoutTime_MPAD" SG_ 280 ESCALATION_TYPE 0;
BA_ "GenSigTimeoutTime_EVCU2" SG_ 280 ESCALATION_TYPE 0;
BA_ "GenSigTimeoutTime_EPS" SG_ 280 ESCALATION_TYPE 0;
BA_ "GenSigTimeoutTime_CVADAS" SG_ 280 ESCALATION_TYPE 0;
BA_ "GenSigTimeoutTime_BSM2" SG_ 280 ESCALATION_TYPE 0;
BA_ "GenSigTimeoutTime_BSM" SG_ 280 ESCALATION_TYPE 0;
BA_ "GenSigTimeoutTime_ADCAM" SG_ 280 ESCALATION_TYPE 0;
BA_ "GenSigTimeoutTime_ORC" SG_ 280 HAS_LAT_CTRL_RequestSts 0;
BA_ "GenSigTimeoutTime_MPAD" SG_ 280 HAS_LAT_CTRL_RequestSts 0;
BA_ "GenSigTimeoutTime_EVCU2" SG_ 280 HAS_LAT_CTRL_RequestSts 0;
BA_ "GenSigTimeoutTime_CVADAS" SG_ 280 HAS_LAT_CTRL_RequestSts 0;
BA_ "GenSigTimeoutTime_BSM2" SG_ 280 HAS_LAT_CTRL_RequestSts 0;
BA_ "GenSigTimeoutTime_BSM" SG_ 280 HAS_LAT_CTRL_RequestSts 0;
BA_ "GenSigTimeoutTime_ADCAM" SG_ 280 HAS_LAT_CTRL_RequestSts 0;
BA_ "GenSigTimeoutTime_MPAD" SG_ 280 HAS_OpStat_Prim 0;
BA_ "GenSigTimeoutTime_EVCU2" SG_ 280 HAS_OpStat_Prim 0;
BA_ "GenSigTimeoutTime_EPS" SG_ 280 HAS_OpStat_Prim 0;
BA_ "GenSigTimeoutTime_CVADAS" SG_ 280 HAS_OpStat_Prim 0;
BA_ "GenSigTimeoutTime_BSM2" SG_ 280 HAS_OpStat_Prim 0;
BA_ "GenSigTimeoutTime_BSM" SG_ 280 HAS_OpStat_Prim 0;
BA_ "GenSigTimeoutTime_ADCAM" SG_ 280 HAS_OpStat_Prim 0;
BA_ "GenSigTimeoutTime_ORC" SG_ 280 HAS_Status 0;
BA_ "GenSigTimeoutTime_MPAD" SG_ 280 HAS_Status 0;
BA_ "GenSigTimeoutTime_EVCU2" SG_ 280 HAS_Status 0;
BA_ "GenSigTimeoutTime_EPS" SG_ 280 HAS_Status 0;
BA_ "GenSigTimeoutTime_ADCAM" SG_ 280 HAS_Status 0;
BA_ "GenSigTimeoutTime_MPAD" SG_ 280 LANE_CHANGE_SIDE 0;
BA_ "GenSigTimeoutTime_EVCU2" SG_ 280 LANE_CHANGE_SIDE 0;
BA_ "GenSigTimeoutTime_EPS" SG_ 280 LANE_CHANGE_SIDE 0;
BA_ "GenSigTimeoutTime_CVADAS" SG_ 280 LANE_CHANGE_SIDE 0;
BA_ "GenSigTimeoutTime_BSM2" SG_ 280 LANE_CHANGE_SIDE 0;
BA_ "GenSigTimeoutTime_BSM" SG_ 280 LANE_CHANGE_SIDE 0;
BA_ "GenSigTimeoutTime_ADCAM" SG_ 280 LANE_CHANGE_SIDE 0;
BA_ "GenSigTimeoutTime_MPAD" SG_ 280 MRM_STATUS 0;
BA_ "GenSigTimeoutTime_EPS" SG_ 280 MRM_STATUS 0;
BA_ "GenSigTimeoutTime_BSM2" SG_ 280 MRM_STATUS 0;
BA_ "GenSigTimeoutTime_ADCAM" SG_ 280 MRM_STATUS 0;
BA_ "GenSigTimeoutTime_MPAD" SG_ 280 PEB_SystemSts 0;
BA_ "GenSigTimeoutTime_EVCU2" SG_ 280 PEB_SystemSts 0;
BA_ "GenSigTimeoutTime_EPS" SG_ 280 PEB_SystemSts 0;
BA_ "GenSigTimeoutTime_CVADAS" SG_ 280 PEB_SystemSts 0;
BA_ "GenSigTimeoutTime_BSM2" SG_ 280 PEB_SystemSts 0;
BA_ "GenSigTimeoutTime_BSM" SG_ 280 PEB_SystemSts 0;
BA_ "GenSigTimeoutTime_ADCAM" SG_ 280 PEB_SystemSts 0;
BA_ "GenSigTimeoutTime_MPAD" SG_ 280 ACC_Systemsts 0;
BA_ "GenSigTimeoutTime_EPS" SG_ 280 ACC_Systemsts 0;
BA_ "GenSigTimeoutTime_ORC" SG_ 280 AEB_Sensitivity_Setting 0;
BA_ "GenSigTimeoutTime_MPAD" SG_ 280 AEB_Sensitivity_Setting 0;
BA_ "GenSigTimeoutTime_EVCU2" SG_ 280 AEB_Sensitivity_Setting 0;
BA_ "GenSigTimeoutTime_EPS" SG_ 280 AEB_Sensitivity_Setting 0;
BA_ "GenSigTimeoutTime_CVADAS" SG_ 280 AEB_Sensitivity_Setting 0;
BA_ "GenSigTimeoutTime_BSM2" SG_ 280 AEB_Sensitivity_Setting 0;
BA_ "GenSigTimeoutTime_BSM" SG_ 280 AEB_Sensitivity_Setting 0;
BA_ "GenSigTimeoutTime_ADCAM" SG_ 280 AEB_Sensitivity_Setting 0;
BA_ "GenSigTimeoutTime_MPAD" SG_ 280 AEB_Systemsts 0;
BA_ "GenSigTimeoutTime_EVCU2" SG_ 280 AEB_Systemsts 0;
BA_ "GenSigTimeoutTime_EPS" SG_ 280 AEB_Systemsts 0;
BA_ "GenSigTimeoutTime_CVADAS" SG_ 280 AEB_Systemsts 0;
BA_ "GenSigTimeoutTime_BSM2" SG_ 280 AEB_Systemsts 0;
BA_ "GenSigTimeoutTime_BSM" SG_ 280 AEB_Systemsts 0;
BA_ "GenSigTimeoutTime_ADCAM" SG_ 280 AEB_Systemsts 0;
BA_ "GenSigTimeoutTime_MPAD" SG_ 280 AEB_Type 0;
BA_ "GenSigTimeoutTime_EVCU2" SG_ 280 AEB_Type 0;
BA_ "GenSigTimeoutTime_EPS" SG_ 280 AEB_Type 0;
BA_ "GenSigTimeoutTime_CVADAS" SG_ 280 AEB_Type 0;
BA_ "GenSigTimeoutTime_ADCAM" SG_ 280 AEB_Type 0;
BA_ "GenSigTimeoutTime_ORC" SG_ 280 CADM_OpStat 0;
BA_ "GenSigTimeoutTime_MPAD" SG_ 280 CADM_OpStat 0;
BA_ "GenSigTimeoutTime_EVCU2" SG_ 280 CADM_OpStat 0;
BA_ "GenSigTimeoutTime_EPS" SG_ 280 CADM_OpStat 0;
BA_ "GenSigTimeoutTime_BSM2" SG_ 280 CADM_OpStat 0;
BA_ "GenSigTimeoutTime_BSM" SG_ 280 CADM_OpStat 0;
BA_ "GenSigTimeoutTime_ADCAM" SG_ 280 CADM_OpStat 0;
BA_ "GenSigTimeoutTime_ORC" SG_ 280 DDD_Setting_Avail 0;
BA_ "GenSigTimeoutTime_MPAD" SG_ 280 DDD_Setting_Avail 0;
BA_ "GenSigTimeoutTime_EVCU2" SG_ 280 DDD_Setting_Avail 0;
BA_ "GenSigTimeoutTime_EPS" SG_ 280 DDD_Setting_Avail 0;
BA_ "GenSigTimeoutTime_CVADAS" SG_ 280 DDD_Setting_Avail 0;
BA_ "GenSigTimeoutTime_BSM2" SG_ 280 DDD_Setting_Avail 0;
BA_ "GenSigTimeoutTime_BSM" SG_ 280 DDD_Setting_Avail 0;
BA_ "GenSigTimeoutTime_ADCAM" SG_ 280 DDD_Setting_Avail 0;
BA_ "GenSigTimeoutTime_MPAD" SG_ 280 CRC_ADAS_FD_INFO 0;
BA_ "GenSigTimeoutTime_ADCAM" SG_ 280 CRC_ADAS_FD_INFO 0;
BA_ "GenSigTimeoutTime_BSM2" SG_ 280 ACC_DsrSpeedKPH 0;
BA_ "GenSigTimeoutTime_BSM" SG_ 280 ACC_DsrSpeedKPH 0;
BA_ "GenSigTimeoutTime_ADCAM" SG_ 280 ACC_DsrSpeedKPH 0;
BA_ "GenSigStartValue" SG_ 280 ACC_DsrSpeedKPH 255;
BA_ "GenSigTimeoutTime_ORC" SG_ 280 ACC_DsrSpeedKPH 0;
BA_ "GenSigTimeoutTime_MPAD" SG_ 280 ACC_DsrSpeedKPH 0;
BA_ "GenSigTimeoutTime_EPS" SG_ 280 ACC_DsrSpeedKPH 0;
BA_ "GenSigTimeoutTime_CVADAS" SG_ 280 ACC_DsrSpeedKPH 0;
BA_ "GenSigTimeoutTime_MPAD" SG_ 280 Intervention 0;
BA_ "GenSigTimeoutTime_EVCU2" SG_ 280 Intervention 0;
BA_ "GenSigTimeoutTime_EPS" SG_ 280 Intervention 0;
BA_ "GenSigTimeoutTime_CVADAS" SG_ 280 Intervention 0;
BA_ "GenSigTimeoutTime_ADCAM" SG_ 280 Intervention 0;
BA_ "GenSigStartValue" SG_ 280 Intervention 4095;
BA_ "GenSigTimeoutTime_ORC" SG_ 280 ACC_Drive_Cmd 0;
BA_ "GenSigTimeoutTime_MPAD" SG_ 280 ACC_Drive_Cmd 0;
BA_ "GenSigTimeoutTime_EVCU2" SG_ 280 ACC_Drive_Cmd 0;
BA_ "GenSigTimeoutTime_EPS" SG_ 280 ACC_Drive_Cmd 0;
BA_ "GenSigTimeoutTime_CVADAS" SG_ 280 ACC_Drive_Cmd 0;
BA_ "GenSigTimeoutTime_BSM2" SG_ 280 ACC_Drive_Cmd 0;
BA_ "GenSigTimeoutTime_ADCAM" SG_ 280 ACC_Drive_Cmd 0;
BA_ "GenSigTimeoutTime_ORC" SG_ 280 ACC_Engine_Torque_Enabled 0;
BA_ "GenSigTimeoutTime_MPAD" SG_ 280 ACC_Engine_Torque_Enabled 0;
BA_ "GenSigTimeoutTime_EVCU2" SG_ 280 ACC_Engine_Torque_Enabled 0;
BA_ "GenSigTimeoutTime_EPS" SG_ 280 ACC_Engine_Torque_Enabled 0;
BA_ "GenSigTimeoutTime_CVADAS" SG_ 280 ACC_Engine_Torque_Enabled 0;
BA_ "GenSigTimeoutTime_BSM2" SG_ 280 ACC_Engine_Torque_Enabled 0;
BA_ "GenSigTimeoutTime_ADCAM" SG_ 280 ACC_Engine_Torque_Enabled 0;
BA_ "GenSigTimeoutTime_ORC" SG_ 280 Brake_Jerk_Req 0;
BA_ "GenSigTimeoutTime_MPAD" SG_ 280 Brake_Jerk_Req 0;
BA_ "GenSigTimeoutTime_EVCU2" SG_ 280 Brake_Jerk_Req 0;
BA_ "GenSigTimeoutTime_EPS" SG_ 280 Brake_Jerk_Req 0;
BA_ "GenSigTimeoutTime_CVADAS" SG_ 280 Brake_Jerk_Req 0;
BA_ "GenSigTimeoutTime_BSM2" SG_ 280 Brake_Jerk_Req 0;
BA_ "GenSigTimeoutTime_ADCAM" SG_ 280 Brake_Jerk_Req 0;
BA_ "GenSigTimeoutTime_MPAD" SG_ 280 CIPV_Fused 0;
BA_ "GenSigTimeoutTime_EVCU2" SG_ 280 CIPV_Fused 0;
BA_ "GenSigTimeoutTime_EPS" SG_ 280 CIPV_Fused 0;
BA_ "GenSigTimeoutTime_CVADAS" SG_ 280 CIPV_Fused 0;
BA_ "GenSigTimeoutTime_BSM2" SG_ 280 CIPV_Fused 0;
BA_ "GenSigTimeoutTime_BSM" SG_ 280 CIPV_Fused 0;
BA_ "GenSigTimeoutTime_ADCAM" SG_ 280 CIPV_Fused 0;
BA_ "GenSigTimeoutTime_ORC" SG_ 280 GrMax_Rq_ACC 0;
BA_ "GenSigTimeoutTime_MPAD" SG_ 280 GrMax_Rq_ACC 0;
BA_ "GenSigTimeoutTime_EVCU2" SG_ 280 GrMax_Rq_ACC 0;
BA_ "GenSigTimeoutTime_EPS" SG_ 280 GrMax_Rq_ACC 0;
BA_ "GenSigTimeoutTime_CVADAS" SG_ 280 GrMax_Rq_ACC 0;
BA_ "GenSigTimeoutTime_BSM2" SG_ 280 GrMax_Rq_ACC 0;
BA_ "GenSigTimeoutTime_ADCAM" SG_ 280 GrMax_Rq_ACC 0;
BA_ "GenSigTimeoutTime_MPAD" SG_ 280 HIS_Req 0;
BA_ "GenSigTimeoutTime_EVCU2" SG_ 280 HIS_Req 0;
BA_ "GenSigTimeoutTime_EPS" SG_ 280 HIS_Req 0;
BA_ "GenSigTimeoutTime_CVADAS" SG_ 280 HIS_Req 0;
BA_ "GenSigTimeoutTime_ADCAM" SG_ 280 HIS_Req 0;
BA_ "GenSigTimeoutTime_MPAD" SG_ 280 MessageCounter_ADAS_FD_INFO 0;
BA_ "GenSigTimeoutTime_ADCAM" SG_ 280 MessageCounter_ADAS_FD_INFO 0;
BA_ "GenSigTimeoutTime_MPAD" SG_ 280 Object_Dist 0;
BA_ "GenSigTimeoutTime_EPS" SG_ 280 Object_Dist 0;
BA_ "GenSigTimeoutTime_CVADAS" SG_ 280 Object_Dist 0;
BA_ "GenSigTimeoutTime_BSM2" SG_ 280 Object_Dist 0;
BA_ "GenSigTimeoutTime_ADCAM" SG_ 280 Object_Dist 0;
BA_ "GenSigStartValue" SG_ 280 Object_Dist 255;
BA_ "GenSigTimeoutTime_ORC" SG_ 280 LC_Jerk 0;
BA_ "GenSigTimeoutTime_MPAD" SG_ 280 LC_Jerk 0;
BA_ "GenSigTimeoutTime_EVCU2" SG_ 280 LC_Jerk 0;
BA_ "GenSigTimeoutTime_EPS" SG_ 280 LC_Jerk 0;
BA_ "GenSigTimeoutTime_CVADAS" SG_ 280 LC_Jerk 0;
BA_ "GenSigTimeoutTime_BSM2" SG_ 280 LC_Jerk 0;
BA_ "GenSigTimeoutTime_ADCAM" SG_ 280 LC_Jerk 0;
BA_ "GenSigTimeoutTime_ORC" SG_ 280 CADM2_EPSSEC_FAIL 0;
BA_ "GenSigTimeoutTime_MPAD" SG_ 280 CADM2_EPSSEC_FAIL 0;
BA_ "GenSigTimeoutTime_EVCU2" SG_ 280 CADM2_EPSSEC_FAIL 0;
BA_ "GenSigTimeoutTime_CVADAS" SG_ 280 CADM2_EPSSEC_FAIL 0;
BA_ "GenSigTimeoutTime_BSM2" SG_ 280 CADM2_EPSSEC_FAIL 0;
BA_ "GenSigTimeoutTime_BSM" SG_ 280 CADM2_EPSSEC_FAIL 0;
BA_ "GenSigTimeoutTime_ADCAM" SG_ 280 CADM2_EPSSEC_FAIL 0;
VAL_ 280 Object_Dist 255 "SNA";
VAL_ 280 ACC_DsrSpeedKPH 255 "SNA";
VAL_ 258 YawRateFailSts_BSM 0 "Fail_Not_Present" 1 "Fail_Present";
VAL_ 258 YawRate_BSM 4095 "SNA";
VAL_ 258 VehicleSpeedVSOSig 8191 "SNA";
VAL_ 258 Slope 255 "SNA";
VAL_ 258 PrefillActive 0 "Not_Active" 1 "Active";
VAL_ 258 LongAccelerationFailSts_BSM 0 "Fail_Not_Present" 1 "Fail_Present";
VAL_ 258 LongAcceleration_BSM 4095 "SNA";
VAL_ 258 LatAccelerationFailSts_BSM 0 "Fail_Not_Present" 1 "Fail_Present";
VAL_ 258 LatAcceleration_BSM 4095 "SNA";
VAL_ 258 InternalError_BSM 0 "No_int_processing_error_detected" 1 "Int_processing_error_detected";
VAL_ 258 ESP_Sys_Stat 0 "ABSERR_DIAG" 1 "NORM" 2 "HALF" 3 "ABGAS";
VAL_ 258 ESCActive 0 "Not_active" 1 "Active";
VAL_ 258 BrakePedalPressure 2047 "SNA";
VAL_ 258 BrakeInterventionSts 0 "No_active_brake_intervention" 1 "Active_brake_intervention";
VAL_ 258 BrakeBoostStat 0 "INIT_Bst" 1 "Normal_Bst" 2 "Limited_Bst" 3 "Shutdown_Bst" 4 "MOCO" 5 "Half_Sys_Bst" 6 "No_Bst" 15 "SNA";
VAL_ 258 BrakeBoostPressure 2047 "SNA";
VAL_ 258 ABSActive 0 "Not_active" 1 "Active";
VAL_ 280 Intervention 4095 "SNA";
VAL_ 280 HIS_Req 0 "Not_Active" 1 "Active";
VAL_ 280 GrMax_Rq_ACC 0 "Passive" 1 "G1" 2 "G2" 3 "G3" 4 "G4" 5 "G5" 6 "G6" 7 "G7" 8 "G8" 9 "G9" 10 "G10" 11 "G11" 12 "G12" 13 "G13" 14 "G14" 15 "G15";
VAL_ 280 CIPV_Fused 0 "Not_Active" 1 "Active";
VAL_ 280 Brake_Jerk_Req 0 "Not_Active" 1 "Active";
VAL_ 280 ACC_Engine_Torque_Enabled 0 "Not_Enabled" 1 "Enabled";
VAL_ 280 ACC_Drive_Cmd 0 "Not_Enabled" 1 "Enabled";
VAL_ 524 VehicleStandStillSts_B2 0 "True" 1 "False" 3 "SNA";
VAL_ 524 BSM2_OpStat 0 "Inactive" 1 "FullService" 2 "FailOperational" 3 "FailDegraded" 4 "Emergency" 5 "No_Function";
VAL_ 524 Brake_OpStat_Sec 0 "Inactive" 1 "FullService" 2 "FailOperational" 3 "FailDegraded" 4 "Emergency" 5 "No_Function";
VAL_ 257 VehicleSpeedVSOSig_B2 8191 "SNA";
VAL_ 257 RHFWheelSpeed_B2 8191 "SNA";
VAL_ 257 RHF_FastPulseCounter_B2 255 "SNA";
VAL_ 257 LHFWheelSpeed_B2 8191 "SNA";
VAL_ 257 LHF_FastPulseCounter_B2 255 "SNA";
VAL_ 258 WheelRPM_FR 65535 "SNA";
VAL_ 258 WheelRPM_FL 65535 "SNA";
VAL_ 258 Brk_Stat 0 "IDLE" 1 "BRAKING" 2 "NDEF2" 3 "SNA";
VAL_ 280 Prefill_Req 0 "No_Prefill_Requested" 1 "Prefill_Requested";
VAL_ 280 PEB_SystemSts 0 "OFF" 1 "ON";
VAL_ 280 MRM_STATUS 0 "Not_Active" 1 "MRM_in_Process" 2 "Vehicle_Secure_Request" 3 "Vehicle_Securement_Complete" 4 "Canceled" 7 "SNA";
VAL_ 280 LANE_CHANGE_SIDE 0 "NO_CHNG" 1 "RIGHT" 2 "LEFT";
VAL_ 280 HAS_Status 0 "Disabled" 1 "Enabled" 2 "Engaged" 3 "Faulted";
VAL_ 280 HAS_OpStat_Prim 0 "Inactive" 1 "FullService" 2 "FailOperational" 3 "FailDegraded" 4 "Emergency" 5 "No_Function";
VAL_ 280 HAS_LAT_CTRL_RequestSts 0 "Idle" 1 "Faulted" 2 "HAS_Request";
VAL_ 280 ESCALATION_TYPE 0 "None" 1 "Driver_Inattention" 2 "Low_Urgency" 3 "Med_Urgency" 4 "High_Urgency";
VAL_ 280 DDD_SystemSts 0 "OFF" 1 "ON";
VAL_ 280 DDD_Setting_Avail 0 "Available" 1 "Not_Available";
VAL_ 280 CADM_OpStat 0 "Inactive" 1 "FullService" 2 "FailOperational" 3 "FailDegraded" 4 "Emergency" 5 "No_Function";
VAL_ 280 AEB_Type 0 "NONE" 1 "ACC" 2 "CMS" 3 "CMS_XTD" 4 "ABA" 5 "LSCM" 6 "PEB" 7 "ICA_L" 8 "ICA_R" 9 "HAS_MRM" 10 "RRCC" 11 "L3" 15 "SNA";
VAL_ 280 AEB_Systemsts 0 "FCW_Off" 1 "FCW_On_Only_Warning" 2 "FCW_On_Full";
VAL_ 280 AEB_Sensitivity_Setting 0 "NEAR" 1 "MEDIUM" 2 "FAR";
VAL_ 280 ACC_Systemsts 0 "OFF" 1 "ACC_Enabled" 2 "ACC_Engaged" 3 "ACC_Engaged_BrakeOnly" 4 "ACC_Cancel" 5 "NCC_Enabled" 6 "NCC_Engaged" 7 "NCC_Cancel" 8 "HAS_BSoC" 9 "RRCC_Enabled_No_Set_Speed" 10 "RRCC_Enabled_With_Set_Speed" 11 "RRCC_Engaged" 12 "L3_Engaged" 13 "L3_Disengaged" 15 "SNA";
VAL_ 280 LANE_CHANGE_STATUS 0 "NO_CHNG" 1 "PEND" 2 "EARLY1" 3 "EARLY2" 4 "LATE" 5 "ABORTING" 6 "ABORTED" 7 "COMPL" 8 "LOCKOUT" 9 "CANCELLING" 10 "CANCELLED" 11 "Lane_Change_Avail_Indication" 12 "Msg_12" 13 "Msg_13" 14 "Msg_14" 15 "SNA";
VAL_ 2654486554 CBV_bit6_PartialNtwInfBit 0 "NM PDU contains no Partial Network request information" 1 "NM PDU contains Partial Network request information";
VAL_ 2654486534 CBV_bit6_PartialNtwInfBit 0 "NM_PDU_contains_no_Partial_Network_request_information" 1 "NM_PDU_contains_Partial_Network_request_information";
VAL_ 2654486676 CBV_bit6_PartialNtwInfBit 0 "NM_PDU_contains_no_Partial_Network_request_information" 1 "NM_PDU_contains_Partial_Network_request_information";
VAL_ 2654486552 CBV_bit6_PartialNtwInfBit 0 "NM_PDU_contains_no_Partial_Network_request_information" 1 "NM_PDU_contains_Partial_Network_request_information";
VAL_ 2654486530 CBV_bit6_PartialNtwInfBit 0 "NM_PDU_contains_no_Partial_Network_request_information" 1 "NM_PDU_contains_Partial_Network_request_information";
VAL_ 2654486554 CBV_bit4_ActiveWakeupBit 0 "PassiveWakeup" 1 "ActiveWakeup";
VAL_ 2654486552 CBV_bit4_ActiveWakeupBit 0 "PassiveWakeup" 1 "ActiveWakeup";
VAL_ 2654486676 CBV_bit4_ActiveWakeupBit 0 "PassiveWakeup" 1 "ActiveWakeup";
VAL_ 2654486530 CBV_bit4_ActiveWakeupBit 0 "PassiveWakeup" 1 "ActiveWakeup";
VAL_ 2654486534 CBV_bit4_ActiveWakeupBit 0 "PassiveWakeup" 1 "ActiveWakeup";
VAL_ 2654486554 CBV_bit3_NMCoordinatorBit 0 "Start of synchronized shutdown is not requested by main coordinator" 1 "Start of synchronized shutdown is requested by main coordinator";
VAL_ 258 ParkingGearShiftReq_BSM 0 "Idle" 1 "P" 2 "R" 3 "N" 4 "D" 7 "SNA";
VAL_ 1156 RollsModeAct_B2 0 "No Fault" 1 "Fault";
VAL_ 1156 ABSFailSts_B2 0 "Fail_Not_Present" 1 "Fail_Present";
VAL_ 524 BrkTrq_B2 32767 "SNA";
VAL_ 257 RHF_WheelSensorFailSts_B2 0 "Fail_Not_Present" 1 "Fail_Present";
VAL_ 257 RHF_Spin_B2 0 "Stand_Still" 1 "Forward" 2 "Backward" 3 "SNA";
VAL_ 257 LHF_WheelSensorFailSts_B2 0 "Fail_Not_Present" 1 "Fail_Present";
VAL_ 257 LHF_Spin_B2 0 "Stand_Still" 1 "Forward" 2 "Backward" 3 "SNA";
VAL_ 257 Inlet_Pressure_Pos 0 "False" 1 "True" 3 "SNA";
VAL_ 257 Brk_Stat_B2 0 "IDLE" 1 "BRAKING" 2 "NDEF2" 3 "SNA";
VAL_ 257 ABSActive_B2 0 "Not_active" 1 "Active";
VAL_ 280 SteeringVibration_Type 0 "TYPE_0" 1 "TYPE_1" 2 "TYPE_2" 3 "TYPE_3" 4 "TYPE_4" 5 "TYPE_5" 6 "TYPE_6" 7 "TYPE_7" 8 "TYPE_8" 9 "TYPE_9" 10 "TYPE_10" 11 "TYPE_11" 15 "SNA";
VAL_ 280 SteeringVibration_Rq 0 "NOT_REQUESTED" 1 "REQUESTED";
VAL_ 280 LKA_LAT_CTRL_RequestSts 0 "Idle" 1 "Faulted" 2 "LKA_Request";
VAL_ 2654486534 CBV_bit3_NMCoordinatorBit 0 "Start_of_synchronized_shutdown_is_not_requested_by_main_coordinator" 1 "Start_of_synchronized_shutdown_is_requested_by_main_coordinator";
VAL_ 2654486530 CBV_bit3_NMCoordinatorBit 0 "Start_of_synchronized_shutdown_is_not_requested_by_main_coordinator" 1 "Start_of_synchronized_shutdown_is_requested_by_main_coordinator";
VAL_ 2654486676 CBV_bit3_NMCoordinatorBit 0 "Start_of_synchronized_shutdown_is_not_requested_by_main_coordinator" 1 "Start_of_synchronized_shutdown_is_requested_by_main_coordinator";
VAL_ 2654486552 CBV_bit3_NMCoordinatorBit 0 "Start_of_synchronized_shutdown_is_not_requested_by_main_coordinator" 1 "Start_of_synchronized_shutdown_is_requested_by_main_coordinator";
VAL_ 2654486552 CBV_bit0_RepeatMessageRequestBit 0 "Repeat_Message_State_not_requested" 1 "Repeat_Message_State_requested";
VAL_ 2654486530 CBV_bit0_RepeatMessageRequestBit 0 "Repeat_Message_State_not_requested" 1 "Repeat_Message_State_requested";
VAL_ 2654486534 CBV_bit0_RepeatMessageRequestBit 0 "Repeat_Message_State_not_requested" 1 "Repeat_Message_State_requested";
VAL_ 2654486676 CBV_bit0_RepeatMessageRequestBit 0 "Repeat_Message_State_not_requested" 1 "Repeat_Message_State_requested";
VAL_ 2654486554 CBV_bit0_RepeatMessageRequestBit 0 "Repeat Message State not requested" 1 "Repeat Message State requested";
VAL_ 280 LC_Jerk 0 "Not_Active" 1 "Active";
VAL_ 258 ParkingInterventionSts 0 "Not_Active" 1 "Active" 2 "Faulted_External" 3 "Faulted_Internal";
VAL_ 524 AEB_Type_Brk_B2 0 "NONE" 1 "ACC" 2 "CMS" 3 "CMS_XTD" 4 "ABA" 5 "LSCM" 6 "PEB" 7 "ICA_L" 8 "ICA_R" 9 "HAS_MRM" 15 "SNA";
VAL_ 280 CADM2_EPSSEC_FAIL 0 "False" 1 "True";
VAL_ 257 Ft_RrTrqCoupling_ModeRq_B2 0 "FREE" 1 "HOLD" 2 "OPEN" 3 "SNA";
VAL_ 257 Ft_RrAxleCoupling_TrqRq_B2 255 "SNA";
VAL_ 205 RearAxle_Min_Rq_BSM 0 "Not_Active" 1 "Active";
VAL_ 205 RearAxle_Max_Rq_BSM 0 "Not_Active" 1 "Active";
VAL_ 205 FrontAxle_Min_Rq_BSM 0 "Not_Active" 1 "Active";
VAL_ 205 FrontAxle_Max_Rq_BSM 0 "Not_Active" 1 "Active";
VAL_ 205 TotalAxle_Min_Rq_BSM 0 "Not_Active" 1 "Active";
VAL_ 205 TotalAxle_Max_Rq_BSM 0 "Not_Active" 1 "Active";
VAL_ 205 DrvrIntd_TotalBrk_AxleTorq 32767 "SNA";
VAL_ 205 DriverReq_AxleTrq_Enabled_BSM 0 "No_Req" 1 "ACC_NCC" 2 "SSC" 3 "PPPA" 4 "RRCC" 15 "SNA";
VAL_ 205 Cmnd_TotBrkFrict_AxleTorq 32767 "SNA";
VAL_ 204 Rear_Axle_Regen_Capacity 16383 "SNA";
VAL_ 204 Rear_Axle_Est_Regen_Torq 16383 "SNA";
VAL_ 204 Front_Axle_Regen_Capacity 16383 "SNA";
VAL_ 204 Front_Axle_Est_Regen_Torq 16383 "SNA";
VAL_ 292 BPCM_HV_Trac_Main_Contac_Sts 0 "Open" 1 "Closed" 3 "Error_Stuck_Open" 4 "Error_Stuck_Closed" 7 "SNA";
VAL_ 292 BPCM_HV_Trac_Bus_Sts 0 "Open" 1 "Closed" 2 "Precharging" 3 "Precharging_Failed" 4 "Precharging_Inhibited" 7 "SNA";
VAL_ 205 TotalAxle_Rq_BSM 65535 "SNA";
VAL_ 205 DriverRequested_AxleTrq_BSM 65535 "SNA";
VAL_ 204 Total_AxleTorque_Min 65535 "SNA";
VAL_ 204 Total_AxleTorque_Max 65535 "SNA";
VAL_ 204 Axle_TorqueStatic_D_TTC 65535 "SNA";
VAL_ 204 Axle_Torque_DrvReqMod 65535 "SNA";
VAL_ 292 BPCM_HV_SOC 1023 "SNA";
VAL_ 292 BPCM_HV_InternalVoltage 16383 "SNA";
VAL_ 2654486701 CBV_bit6_PartialNtwInfBit 0 "Partial_Network_info_contained" 1 "No_Partial_Network_info_contained";
VAL_ 2654486689 CBV_bit6_PartialNtwInfBit 0 "Partial_Network_info_contained" 1 "No_Partial_Network_info_contained";
VAL_ 2654486689 CBV_bit4_ActiveWakeupBit 0 "PassiveWakeup" 1 "ActiveWakeup";
VAL_ 2654486701 CBV_bit4_ActiveWakeupBit 0 "PassiveWakeup" 1 "ActiveWakeup";
VAL_ 2654486689 CBV_bit3_NMCoordinatorBit 0 "Synch_shutdown_not_requested" 1 "Synch_shutdown_requested";
VAL_ 2654486701 CBV_bit3_NMCoordinatorBit 0 "Synch_shutdown_not_requested" 1 "Synch_shutdown_requested";
VAL_ 2654486701 CBV_bit0_RepeatMessageRequestBit 0 "Repeat_Msg_State_not_requested" 1 "Repeat_Msg_State_requested";
VAL_ 2654486689 CBV_bit0_RepeatMessageRequestBit 0 "Repeat_Msg_State_not_requested" 1 "Repeat_Msg_State_requested";
VAL_ 205 RearAxle_Rq_BSM 65535 "SNA";
VAL_ 205 FrontAxle_Rq_BSM 65535 "SNA";
VAL_ 204 Rear_AxleTorque_Min 65535 "SNA";
VAL_ 204 Rear_AxleTorque_Max 65535 "SNA";
VAL_ 204 Front_AxleTorque_Min 65535 "SNA";
VAL_ 204 Front_AxleTorque_Max 65535 "SNA";
VAL_ 299 ACC_Axle_Torque 65535 "SNA";
VAL_ 299 ACC_Axle_Torque_Enabled 0 "Not_Enabled" 1 "Enabled";
VAL_ 299 ACC_TORSts 0 "TOR_Active" 1 "TOR_Not_Active";
SIG_GROUP_ 258 BRAKE_FD_2_Pkt 1 : YawRateFailSts_BSM YawRate_BSM VehicleSpeedVSOSig Slope PrefillActive MessageCounter_BRAKE2 LongAccelerationFailSts_BSM LongAcceleration_BSM LatAccelerationFailSts_BSM LatAcceleration_BSM InternalError_BSM ESP_Sys_Stat ESCActive CRC_BRAKE2 BrakePedalPressure BrakeInterventionSts BrakeBoostStat BrakeBoostPressure ABSActive WheelRPM_FR WheelRPM_FL Brk_Stat ParkingGearShiftReq_BSM ParkingInterventionSts;
SIG_GROUP_ 524 BRAKE2_FD_2_Pkt 1 : VehicleStandStillSts_B2 BSM2_OpStat Brake_OpStat_Sec MessageCounter_BRAKE2_2 CRC_BRAKE2_2 BrkTrq_B2 BSM2_HEALTH_CHECK AEB_Type_Brk_B2;
SIG_GROUP_ 257 BRAKE2_FD_1_Pkt 1 : VehicleSpeedVSOSig_B2 RHFWheelSpeed_B2 RHF_FastPulseCounter_B2 LHFWheelSpeed_B2 LHF_FastPulseCounter_B2 RHF_WheelSensorFailSts_B2 RHF_Spin_B2 MessageCounter_BRAKE2_1 LHF_WheelSensorFailSts_B2 LHF_Spin_B2 Inlet_Pressure_Pos CRC_BRAKE2_1 Brk_Stat_B2 ABSActive_B2 Ft_RrTrqCoupling_ModeRq_B2 Ft_RrAxleCoupling_TrqRq_B2;
SIG_GROUP_ 727 CVPAM_FD_Data2_Pkt 1 : MessageCounter_CVPAM_FD_Data2 CRC_CVPAM_FD_Data2;
SIG_GROUP_ 726 CVPAM_FD_Data_Pkt 1 : MessageCounter_CVPAM_FD_Data CRC_CVPAM_FD_Data;
SIG_GROUP_ 1156 BRAKE2_FD_3_Pkt 1 : RollsModeAct_B2 MessageCounter_BRAKE2_3 CRC_BRAKE2_3 ABSFailSts_B2;
SIG_GROUP_ 280 ADAS_FD_INFO_Pkt 1 : Object_Dist MessageCounter_ADAS_FD_INFO CRC_ADAS_FD_INFO ACC_DsrSpeedKPH Intervention HIS_Req GrMax_Rq_ACC CIPV_Fused Brake_Jerk_Req ACC_Engine_Torque_Enabled ACC_Drive_Cmd Prefill_Req PEB_SystemSts MRM_STATUS LANE_CHANGE_SIDE HAS_Status HAS_OpStat_Prim HAS_LAT_CTRL_RequestSts ESCALATION_TYPE DDD_SystemSts DDD_Setting_Avail CADM_OpStat AEB_Type AEB_Systemsts AEB_Sensitivity_Setting ACC_Systemsts SteeringVibration_Type SteeringVibration_Rq LKA_LAT_CTRL_RequestSts LANE_CHANGE_STATUS LC_Jerk CADM2_EPSSEC_FAIL TorqueOverlaySteeringReq;
SIG_GROUP_ 205 BRAKE_FD_6_Pkt 1 : CRC_BRAKE_FD_6 MessageCounter_BRAKE_FD_6 RearAxle_Min_Rq_BSM RearAxle_Max_Rq_BSM FrontAxle_Min_Rq_BSM FrontAxle_Max_Rq_BSM TotalAxle_Min_Rq_BSM TotalAxle_Max_Rq_BSM DrvrIntd_TotalBrk_AxleTorq DriverReq_AxleTrq_Enabled_BSM Cmnd_TotBrkFrict_AxleTorq TotalAxle_Rq_BSM DriverRequested_AxleTrq_BSM RearAxle_Rq_BSM FrontAxle_Rq_BSM;
SIG_GROUP_ 204 AXLE_TORQUE_FD_1_Pkt 1 : MessageCounter_AXLE_TORQUE_FD_1 CRC_AXLE_TORQUE_FD_1 Rear_Axle_Regen_Capacity Rear_Axle_Est_Regen_Torq Front_Axle_Regen_Capacity Front_Axle_Est_Regen_Torq Total_AxleTorque_Min Total_AxleTorque_Max Axle_TorqueStatic_D_TTC Axle_Torque_DrvReqMod Rear_AxleTorque_Min Rear_AxleTorque_Max Front_AxleTorque_Min Front_AxleTorque_Max;
SIG_GROUP_ 292 BATTERY_HV_STATUS1_Pkt 1 : CRC_BATT_HV_STATUS1 MessageCounter_BATT_HV_STATUS1 BPCM_HV_Trac_Main_Contac_Sts BPCM_HV_Trac_Bus_Sts BPCM_HV_SOC BPCM_HV_InternalVoltage;
SIG_GROUP_ 299 ADAS_FD_INFO3_Pkt 1 : ACC_Axle_Torque ACC_Axle_Torque_Enabled MessageCounter_ADAS_FD_INFO3 CRC_ADAS_FD_INFO3 ACC_TORSts;
